VERSION ""

NS_ :

BS_:

BU_: VMCU VGGSECUSystem TECU OBDScanT2 HMIIOM EMS ECUspare2 ECUspare1 DACU CIOM BBM

BO_ 2566560036 VMCU_BB2_33S: 230 VMCU
 SG_ MaintInfoGrp_MaintOption30_ISig_ : 52|4@1+ (1,0) [0|0] ""  VGGSECUSystem,HMIIOM
 SG_ MaintInfoGrp_Unit36_ISig_4 : 363|3@1+ (1,0) [0|0] ""  VGGSECUSystem,HMIIOM
 SG_ MaintInfoGrp_MaintOption33_ISig_ : 40|4@1+ (1,0) [0|0] ""  HMIIOM,VGGSECUSystem
 SG_ MaintInfoGrp_ResetAuthorized32_I : 506|2@1+ (1,0) [0|0] ""  HMIIOM,VGGSECUSystem
 SG_ MaintInfoGrp_Status10_ISig_4 : 395|3@1+ (1,0) [0|0] ""  HMIIOM,VGGSECUSystem
 SG_ MaintInfoGrp_Unit2_ISig_4 : 459|3@1+ (1,0) [0|0] ""  VGGSECUSystem,HMIIOM
 SG_ MaintInfoGrp_Unit14_ISig_4 : 160|3@1+ (1,0) [0|0] ""  HMIIOM,VGGSECUSystem
 SG_ MaintInfoGrp_ResetAuthorized28_I : 486|2@1+ (1,0) [0|0] ""  HMIIOM,VGGSECUSystem
 SG_ MaintInfoGrp_ResetAuthorized10_I : 510|2@1+ (1,0) [0|0] ""  VGGSECUSystem,HMIIOM
 SG_ MaintInfoGrp_Status31_ISig_4 : 368|3@1+ (1,0) [0|0] ""  HMIIOM,VGGSECUSystem
 SG_ MaintInfoGrp_Unit32_ISig_4 : 427|3@1+ (1,0) [0|0] ""  HMIIOM,VGGSECUSystem
 SG_ MaintInfoGrp_Status15_ISig_4 : 251|3@1+ (1,0) [0|0] ""  HMIIOM,VGGSECUSystem
 SG_ MaintInfoGrp_Supported19_ISig_4 : 278|2@1+ (1,0) [0|0] ""  VGGSECUSystem,HMIIOM
 SG_ MaintInfoGrp_Unit34_ISig_4 : 312|3@1+ (1,0) [0|0] ""  VGGSECUSystem,HMIIOM
 SG_ MaintInfoGrp_Data17_ISig_4 : 816|32@1+ (1,0) [0|4294967295] ""  VGGSECUSystem,HMIIOM
 SG_ MaintInfoGrp_Unit26_ISig_4 : 179|3@1+ (1,0) [0|0] ""  VGGSECUSystem,HMIIOM
 SG_ MaintInfoGrp_Data24_ISig_4 : 848|32@1+ (1,0) [0|4294967295] ""  VGGSECUSystem,HMIIOM
 SG_ MaintInfoGrp_ResetAuthorized24_I : 502|2@1+ (1,0) [0|0] ""  VGGSECUSystem,HMIIOM
 SG_ MaintInfoGrp_ResetAuthorized34_I : 454|2@1+ (1,0) [0|0] ""  VGGSECUSystem,HMIIOM
 SG_ MaintInfoGrp_Unit28_ISig_4 : 176|3@1+ (1,0) [0|0] ""  VGGSECUSystem,HMIIOM
 SG_ MaintInfoGrp_Status26_ISig_4 : 219|3@1+ (1,0) [0|0] ""  HMIIOM,VGGSECUSystem
 SG_ MaintInfoGrp_Unit10_ISig_4 : 352|3@1+ (1,0) [0|0] ""  VGGSECUSystem,HMIIOM
 SG_ MaintInfoGrp_Data12_ISig_4 : 1616|32@1+ (1,0) [0|4294967295] ""  HMIIOM,VGGSECUSystem
 SG_ MaintInfoGrp_ResetAuthorized38_I : 230|2@1+ (1,0) [0|0] ""  HMIIOM,VGGSECUSystem
 SG_ MaintInfoGrp_MaintOption14_ISig_ : 128|4@1+ (1,0) [0|0] ""  HMIIOM,VGGSECUSystem
 SG_ MaintInfoGrp_MaintOption17_ISig_ : 0|4@1+ (1,0) [0|0] ""  VGGSECUSystem,HMIIOM
 SG_ MaintInfoGrp_Status33_ISig_4 : 360|3@1+ (1,0) [0|0] ""  HMIIOM,VGGSECUSystem
 SG_ MaintInfoGrp_Unit6_ISig_4 : 203|3@1+ (1,0) [0|0] ""  VGGSECUSystem,HMIIOM
 SG_ MaintInfoGrp_Supported7_ISig_4 : 504|2@1+ (1,0) [0|0] ""  HMIIOM,VGGSECUSystem
 SG_ MaintInfoGrp_Status7_ISig_4 : 240|3@1+ (1,0) [0|0] ""  VGGSECUSystem,HMIIOM
 SG_ MaintInfoGrp_ResetAuthorized2_IS : 462|2@1+ (1,0) [0|0] ""  HMIIOM,VGGSECUSystem
 SG_ MaintInfoGrp_MaintOption27_ISig_ : 44|4@1+ (1,0) [0|0] ""  HMIIOM,VGGSECUSystem
 SG_ MaintInfoGrp_Supported36_ISig_4 : 492|2@1+ (1,0) [0|0] ""  HMIIOM,VGGSECUSystem
 SG_ MaintInfoGrp_Unit22_ISig_4 : 171|3@1+ (1,0) [0|0] ""  VGGSECUSystem,HMIIOM
 SG_ MaintInfoGrp_Unit18_ISig_4 : 315|3@1+ (1,0) [0|0] ""  VGGSECUSystem,HMIIOM
 SG_ MaintInfoGrp_MaintOption28_ISig_ : 96|4@1+ (1,0) [0|0] ""  VGGSECUSystem,HMIIOM
 SG_ MaintInfoGrp_Supported18_ISig_4 : 526|2@1+ (1,0) [0|0] ""  HMIIOM,VGGSECUSystem
 SG_ MaintInfoGrp_Status22_ISig_4 : 304|3@1+ (1,0) [0|0] ""  HMIIOM,VGGSECUSystem
 SG_ MaintInfoGrp_Status30_ISig_4 : 200|3@1+ (1,0) [0|0] ""  VGGSECUSystem,HMIIOM
 SG_ MaintInfoGrp_Status20_ISig_4 : 467|3@1+ (1,0) [0|0] ""  VGGSECUSystem,HMIIOM
 SG_ MaintInfoGrp_Status38_ISig_4 : 419|3@1+ (1,0) [0|0] ""  VGGSECUSystem,HMIIOM
 SG_ MaintInfoGrp_Data38_ISig_4 : 688|32@1+ (1,0) [0|4294967295] ""  HMIIOM,VGGSECUSystem
 SG_ MaintInfoGrp_ResetAuthorized7_IS : 190|2@1+ (1,0) [0|0] ""  HMIIOM,VGGSECUSystem
 SG_ MaintInfoGrp_Data19_ISig_4 : 1104|32@1+ (1,0) [0|4294967295] ""  HMIIOM,VGGSECUSystem
 SG_ MaintInfoGrp_ResetAuthorized19_I : 438|2@1+ (1,0) [0|0] ""  HMIIOM,VGGSECUSystem
 SG_ MaintInfoGrp_ResetAuthorized12_I : 542|2@1+ (1,0) [0|0] ""  HMIIOM,VGGSECUSystem
 SG_ MaintInfoGrp_MaintOption8_ISig_4 : 108|4@1+ (1,0) [0|0] ""  HMIIOM,VGGSECUSystem
 SG_ MaintInfoGrp_MaintOption9_ISig_4 : 56|4@1+ (1,0) [0|0] ""  HMIIOM,VGGSECUSystem
 SG_ MaintInfoGrp_ResetAuthorized13_I : 522|2@1+ (1,0) [0|0] ""  VGGSECUSystem,HMIIOM
 SG_ MaintInfoGrp_Unit31_ISig_4 : 283|3@1+ (1,0) [0|0] ""  VGGSECUSystem,HMIIOM
 SG_ MaintInfoGrp_Status2_ISig_4 : 400|3@1+ (1,0) [0|0] ""  VGGSECUSystem,HMIIOM
 SG_ MaintInfoGrp_ResetAuthorized5_IS : 206|2@1+ (1,0) [0|0] ""  VGGSECUSystem,HMIIOM
 SG_ MaintInfoGrp_Supported33_ISig_4 : 350|2@1+ (1,0) [0|0] ""  VGGSECUSystem,HMIIOM
 SG_ MaintInfoGrp_Unit7_ISig_4 : 256|3@1+ (1,0) [0|0] ""  HMIIOM,VGGSECUSystem
 SG_ MaintInfoGrp_Supported34_ISig_4 : 524|2@1+ (1,0) [0|0] ""  HMIIOM,VGGSECUSystem
 SG_ MaintInfoGrp_Data16_ISig_4 : 1392|32@1+ (1,0) [0|4294967295] ""  HMIIOM,VGGSECUSystem
 SG_ MaintInfoGrp_Unit19_ISig_4 : 299|3@1+ (1,0) [0|0] ""  HMIIOM,VGGSECUSystem
 SG_ MaintInfoGrp_ResetAuthorized21_I : 494|2@1+ (1,0) [0|0] ""  HMIIOM,VGGSECUSystem
 SG_ MaintInfoGrp_ResetAuthorized31_I : 552|2@1+ (1,0) [0|0] ""  HMIIOM,VGGSECUSystem
 SG_ MaintInfoGrp_Data28_ISig_4 : 1488|32@1+ (1,0) [0|4294967295] ""  HMIIOM,VGGSECUSystem
 SG_ MaintInfoGrp_ResetAuthorized3_IS : 374|2@1+ (1,0) [0|0] ""  HMIIOM,VGGSECUSystem
 SG_ MaintInfoGrp_MaintOption34_ISig_ : 12|4@1+ (1,0) [0|0] ""  VGGSECUSystem,HMIIOM
 SG_ MaintInfoGrp_Status21_ISig_4 : 475|3@1+ (1,0) [0|0] ""  VGGSECUSystem,HMIIOM
 SG_ MaintInfoGrp_Unit21_ISig_4 : 235|3@1+ (1,0) [0|0] ""  VGGSECUSystem,HMIIOM
 SG_ MaintInfoGrp_MaintOption24_ISig_ : 116|4@1+ (1,0) [0|0] ""  HMIIOM,VGGSECUSystem
 SG_ MaintInfoGrp_Data26_ISig_4 : 976|32@1+ (1,0) [0|4294967295] ""  VGGSECUSystem,HMIIOM
 SG_ MaintInfoGrp_Data37_ISig_4 : 752|32@1+ (1,0) [0|4294967295] ""  VGGSECUSystem,HMIIOM
 SG_ MaintInfoGrp_Data35_ISig_4 : 1136|32@1+ (1,0) [0|4294967295] ""  VGGSECUSystem,HMIIOM
 SG_ MaintInfoGrp_Supported17_ISig_4 : 222|2@1+ (1,0) [0|0] ""  VGGSECUSystem,HMIIOM
 SG_ MaintInfoGrp_ResetAuthorized17_I : 546|2@1+ (1,0) [0|0] ""  VGGSECUSystem,HMIIOM
 SG_ MaintInfoGrp_Unit25_ISig_4 : 248|3@1+ (1,0) [0|0] ""  HMIIOM,VGGSECUSystem
 SG_ MaintInfoGrp_Unit37_ISig_4 : 344|3@1+ (1,0) [0|0] ""  VGGSECUSystem,HMIIOM
 SG_ MaintInfoGrp_MaintOption2_ISig_4 : 60|4@1+ (1,0) [0|0] ""  HMIIOM,VGGSECUSystem
 SG_ MaintInfoGrp_Supported21_ISig_4 : 406|2@1+ (1,0) [0|0] ""  VGGSECUSystem,HMIIOM
 SG_ MaintInfoGrp_ResetAuthorized16_I : 270|2@1+ (1,0) [0|0] ""  HMIIOM,VGGSECUSystem
 SG_ MaintInfoGrp_Supported15_ISig_4 : 528|2@1+ (1,0) [0|0] ""  HMIIOM,VGGSECUSystem
 SG_ MaintInfoGrp_ResetAuthorized9_IS : 540|2@1+ (1,0) [0|0] ""  HMIIOM,VGGSECUSystem
 SG_ MaintInfoGrp_MaintOption18_ISig_ : 36|4@1+ (1,0) [0|0] ""  VGGSECUSystem,HMIIOM
 SG_ MaintInfoGrp_Data14_ISig_4 : 1456|32@1+ (1,0) [0|4294967295] ""  HMIIOM,VGGSECUSystem
 SG_ MaintInfoGrp_Data8_ISig_4 : 1808|32@1+ (1,0) [0|4294967295] ""  HMIIOM,VGGSECUSystem
 SG_ MaintInfoGrp_Supported29_ISig_4 : 484|2@1+ (1,0) [0|0] ""  HMIIOM,VGGSECUSystem
 SG_ MaintInfoGrp_ResetAuthorized39_I : 558|2@1+ (1,0) [0|0] ""  HMIIOM,VGGSECUSystem
 SG_ MaintInfoGrp_Supported32_ISig_4 : 358|2@1+ (1,0) [0|0] ""  HMIIOM,VGGSECUSystem
 SG_ MaintInfoGrp_Data33_ISig_4 : 1328|32@1+ (1,0) [0|4294967295] ""  VGGSECUSystem,HMIIOM
 SG_ MaintInfoGrp_ResetAuthorized35_I : 550|2@1+ (1,0) [0|0] ""  VGGSECUSystem,HMIIOM
 SG_ MaintInfoGrp_Data30_ISig_4 : 880|32@1+ (1,0) [0|4294967295] ""  VGGSECUSystem,HMIIOM
 SG_ MaintInfoGrp_ResetAuthorized29_I : 534|2@1+ (1,0) [0|0] ""  VGGSECUSystem,HMIIOM
 SG_ MaintInfoGrp_Supported35_ISig_4 : 310|2@1+ (1,0) [0|0] ""  VGGSECUSystem,HMIIOM
 SG_ MaintInfoGrp_ResetAuthorized4_IS : 530|2@1+ (1,0) [0|0] ""  VGGSECUSystem,HMIIOM
 SG_ MaintInfoGrp_Data10_ISig_4 : 624|32@1+ (1,0) [0|4294967295] ""  HMIIOM,VGGSECUSystem
 SG_ MaintInfoGrp_Data9_ISig_4 : 1584|32@1+ (1,0) [0|4294967295] ""  VGGSECUSystem,HMIIOM
 SG_ MaintInfoGrp_Unit1_ISig_4 : 328|3@1+ (1,0) [0|0] ""  VGGSECUSystem,HMIIOM
 SG_ MaintInfoGrp_MaintOption7_ISig_4 : 104|4@1+ (1,0) [0|0] ""  HMIIOM,VGGSECUSystem
 SG_ MaintInfoGrp_Supported24_ISig_4 : 390|2@1+ (1,0) [0|0] ""  VGGSECUSystem,HMIIOM
 SG_ MaintInfoGrp_Supported25_ISig_4 : 514|2@1+ (1,0) [0|0] ""  VGGSECUSystem,HMIIOM
 SG_ MaintInfoGrp_Unit15_ISig_4 : 339|3@1+ (1,0) [0|0] ""  VGGSECUSystem,HMIIOM
 SG_ MaintInfoGrp_Supported1_ISig_4 : 446|2@1+ (1,0) [0|0] ""  HMIIOM,VGGSECUSystem
 SG_ MaintInfoGrp_ResetAuthorized11_I : 254|2@1+ (1,0) [0|0] ""  HMIIOM,VGGSECUSystem
 SG_ MaintInfoGrp_Supported13_ISig_4 : 238|2@1+ (1,0) [0|0] ""  HMIIOM,VGGSECUSystem
 SG_ MaintInfoGrp_Supported10_ISig_4 : 490|2@1+ (1,0) [0|0] ""  HMIIOM,VGGSECUSystem
 SG_ MaintInfoGrp_Data2_ISig_4 : 720|32@1+ (1,0) [0|4294967295] ""  HMIIOM,VGGSECUSystem
 SG_ MaintInfoGrp_Unit16_ISig_4 : 243|3@1+ (1,0) [0|0] ""  HMIIOM,VGGSECUSystem
 SG_ MaintInfoGrp_MaintOption35_ISig_ : 144|4@1+ (1,0) [0|0] ""  VGGSECUSystem,HMIIOM
 SG_ MaintInfoGrp_MaintOption22_ISig_ : 156|4@1+ (1,0) [0|0] ""  HMIIOM,VGGSECUSystem
 SG_ MaintInfoGrp_MaintOption12_ISig_ : 8|4@1+ (1,0) [0|0] ""  VGGSECUSystem,HMIIOM
 SG_ MaintInfoGrp_Supported9_ISig_4 : 342|2@1+ (1,0) [0|0] ""  HMIIOM,VGGSECUSystem
 SG_ MaintInfoGrp_Supported31_ISig_4 : 512|2@1+ (1,0) [0|0] ""  VGGSECUSystem,HMIIOM
 SG_ MaintInfoGrp_MaintOption37_ISig_ : 100|4@1+ (1,0) [0|0] ""  HMIIOM,VGGSECUSystem
 SG_ MaintInfoGrp_MaintOption13_ISig_ : 120|4@1+ (1,0) [0|0] ""  HMIIOM,VGGSECUSystem
 SG_ MaintInfoGrp_ResetAuthorized22_I : 538|2@1+ (1,0) [0|0] ""  VGGSECUSystem,HMIIOM
 SG_ MaintInfoGrp_Status14_ISig_4 : 259|3@1+ (1,0) [0|0] ""  VGGSECUSystem,HMIIOM
 SG_ MaintInfoGrp_Status18_ISig_4 : 424|3@1+ (1,0) [0|0] ""  HMIIOM,VGGSECUSystem
 SG_ MaintInfoGrp_Unit17_ISig_4 : 187|3@1+ (1,0) [0|0] ""  VGGSECUSystem,HMIIOM
 SG_ MaintInfoGrp_Unit12_ISig_4 : 224|3@1+ (1,0) [0|0] ""  HMIIOM,VGGSECUSystem
 SG_ MaintInfoGrp_Data22_ISig_4 : 1552|32@1+ (1,0) [0|4294967295] ""  HMIIOM,VGGSECUSystem
 SG_ MaintInfoGrp_Supported27_ISig_4 : 262|2@1+ (1,0) [0|0] ""  HMIIOM,VGGSECUSystem
 SG_ MaintInfoGrp_Unit4_ISig_4 : 163|3@1+ (1,0) [0|0] ""  HMIIOM,VGGSECUSystem
 SG_ MaintInfoGrp_Data13_ISig_4 : 656|32@1+ (1,0) [0|4294967295] ""  VGGSECUSystem,HMIIOM
 SG_ MaintInfoGrp_Status27_ISig_4 : 355|3@1+ (1,0) [0|0] ""  VGGSECUSystem,HMIIOM
 SG_ MaintInfoGrp_MaintOption29_ISig_ : 124|4@1+ (1,0) [0|0] ""  HMIIOM,VGGSECUSystem
 SG_ MaintInfoGrp_Unit9_ISig_4 : 435|3@1+ (1,0) [0|0] ""  VGGSECUSystem,HMIIOM
 SG_ MaintInfoGrp_Unit13_ISig_4 : 387|3@1+ (1,0) [0|0] ""  VGGSECUSystem,HMIIOM
 SG_ MaintInfoGrp_Data25_ISig_4 : 560|32@1+ (1,0) [0|4294967295] ""  HMIIOM,VGGSECUSystem
 SG_ MaintInfoGrp_Unit3_ISig_4 : 472|3@1+ (1,0) [0|0] ""  VGGSECUSystem,HMIIOM
 SG_ MaintInfoGrp_MaintOption15_ISig_ : 148|4@1+ (1,0) [0|0] ""  VGGSECUSystem,HMIIOM
 SG_ MaintInfoGrp_ResetAuthorized15_I : 508|2@1+ (1,0) [0|0] ""  VGGSECUSystem,HMIIOM
 SG_ MaintInfoGrp_MaintOption11_ISig_ : 68|4@1+ (1,0) [0|0] ""  HMIIOM,VGGSECUSystem
 SG_ MaintInfoGrp_MaintOption25_ISig_ : 112|4@1+ (1,0) [0|0] ""  VGGSECUSystem,HMIIOM
 SG_ MaintInfoGrp_Supported16_ISig_4 : 174|2@1+ (1,0) [0|0] ""  HMIIOM,VGGSECUSystem
 SG_ MaintInfoGrp_Supported23_ISig_4 : 544|2@1+ (1,0) [0|0] ""  VGGSECUSystem,HMIIOM
 SG_ MaintInfoGrp_Status13_ISig_4 : 267|3@1+ (1,0) [0|0] ""  VGGSECUSystem,HMIIOM
 SG_ MaintInfoGrp_Status17_ISig_4 : 307|3@1+ (1,0) [0|0] ""  HMIIOM,VGGSECUSystem
 SG_ MaintInfoGrp_Unit8_ISig_4 : 275|3@1+ (1,0) [0|0] ""  VGGSECUSystem,HMIIOM
 SG_ MaintInfoGrp_MaintOption38_ISig_ : 64|4@1+ (1,0) [0|0] ""  VGGSECUSystem,HMIIOM
 SG_ MaintInfoGrp_Data4_ISig_4 : 1040|32@1+ (1,0) [0|4294967295] ""  VGGSECUSystem,HMIIOM
 SG_ MaintInfoGrp_Supported2_ISig_4 : 198|2@1+ (1,0) [0|0] ""  VGGSECUSystem,HMIIOM
 SG_ MaintInfoGrp_ResetAuthorized0_IS : 516|2@1+ (1,0) [0|0] ""  VGGSECUSystem,HMIIOM
 SG_ MaintInfoGrp_Supported5_ISig_4 : 478|2@1+ (1,0) [0|0] ""  HMIIOM,VGGSECUSystem
 SG_ MaintInfoGrp_Status6_ISig_4 : 336|3@1+ (1,0) [0|0] ""  HMIIOM,VGGSECUSystem
 SG_ MaintInfoGrp_Unit5_ISig_4 : 411|3@1+ (1,0) [0|0] ""  VGGSECUSystem,HMIIOM
 SG_ MaintInfoGrp_Data0_ISig_4 : 592|32@1+ (1,0) [0|4294967295] ""  HMIIOM,VGGSECUSystem
 SG_ MaintInfoGrp_Data29_ISig_4 : 1776|32@1+ (1,0) [0|4294967295] ""  HMIIOM,VGGSECUSystem
 SG_ MaintInfoGrp_Supported28_ISig_4 : 498|2@1+ (1,0) [0|0] ""  VGGSECUSystem,HMIIOM
 SG_ MaintInfoGrp_Status32_ISig_4 : 371|3@1+ (1,0) [0|0] ""  VGGSECUSystem,HMIIOM
 SG_ MaintInfoGrp_MaintOption0_ISig_4 : 152|4@1+ (1,0) [0|0] ""  VGGSECUSystem,HMIIOM
 SG_ MaintInfoGrp_ResetAuthorized25_I : 480|2@1+ (1,0) [0|0] ""  HMIIOM,VGGSECUSystem
 SG_ MaintInfoGrp_MaintOption32_ISig_ : 28|4@1+ (1,0) [0|0] ""  HMIIOM,VGGSECUSystem
 SG_ MaintInfoGrp_Unit11_ISig_4 : 464|3@1+ (1,0) [0|0] ""  VGGSECUSystem,HMIIOM
 SG_ MaintInfoGrp_Data39_ISig_4 : 912|32@1+ (1,0) [0|4294967295] ""  VGGSECUSystem,HMIIOM
 SG_ MaintInfoGrp_MaintOption4_ISig_4 : 80|4@1+ (1,0) [0|0] ""  VGGSECUSystem,HMIIOM
 SG_ MaintInfoGrp_Supported38_ISig_4 : 302|2@1+ (1,0) [0|0] ""  VGGSECUSystem,HMIIOM
 SG_ MaintInfoGrp_MaintOption1_ISig_4 : 136|4@1+ (1,0) [0|0] ""  VGGSECUSystem,HMIIOM
 SG_ MaintInfoGrp_Supported30_ISig_4 : 182|2@1+ (1,0) [0|0] ""  HMIIOM,VGGSECUSystem
 SG_ MaintInfoGrp_ResetAuthorized33_I : 496|2@1+ (1,0) [0|0] ""  HMIIOM,VGGSECUSystem
 SG_ MaintInfoGrp_Status0_ISig_4 : 392|3@1+ (1,0) [0|0] ""  HMIIOM,VGGSECUSystem
 SG_ MaintInfoGrp_ResetAuthorized20_I : 334|2@1+ (1,0) [0|0] ""  VGGSECUSystem,HMIIOM
 SG_ MaintInfoGrp_Unit33_ISig_4 : 232|3@1+ (1,0) [0|0] ""  VGGSECUSystem,HMIIOM
 SG_ MaintInfoGrp_Supported26_ISig_4 : 500|2@1+ (1,0) [0|0] ""  VGGSECUSystem,HMIIOM
 SG_ MaintInfoGrp_ResetAuthorized6_IS : 532|2@1+ (1,0) [0|0] ""  VGGSECUSystem,HMIIOM
 SG_ MaintInfoGrp_Data18_ISig_4 : 1648|32@1+ (1,0) [0|4294967295] ""  HMIIOM,VGGSECUSystem
 SG_ MaintInfoGrp_Status16_ISig_4 : 432|3@1+ (1,0) [0|0] ""  HMIIOM,VGGSECUSystem
 SG_ MaintInfoGrp_ResetAuthorized18_I : 294|2@1+ (1,0) [0|0] ""  HMIIOM,VGGSECUSystem
 SG_ MaintInfoGrp_Status4_ISig_4 : 168|3@1+ (1,0) [0|0] ""  HMIIOM,VGGSECUSystem
 SG_ MaintInfoGrp_Data3_ISig_4 : 1072|32@1+ (1,0) [0|4294967295] ""  VGGSECUSystem,HMIIOM
 SG_ MaintInfoGrp_MaintOption20_ISig_ : 140|4@1+ (1,0) [0|0] ""  VGGSECUSystem,HMIIOM
 SG_ MaintInfoGrp_ResetAuthorized30_I : 166|2@1+ (1,0) [0|0] ""  HMIIOM,VGGSECUSystem
 SG_ MaintInfoGrp_ResetAuthorized23_I : 520|2@1+ (1,0) [0|0] ""  HMIIOM,VGGSECUSystem
 SG_ MaintInfoGrp_Unit30_ISig_4 : 408|3@1+ (1,0) [0|0] ""  HMIIOM,VGGSECUSystem
 SG_ MaintInfoGrp_Data20_ISig_4 : 944|32@1+ (1,0) [0|4294967295] ""  HMIIOM,VGGSECUSystem
 SG_ MaintInfoGrp_MaintOption23_ISig_ : 132|4@1+ (1,0) [0|0] ""  VGGSECUSystem,HMIIOM
 SG_ MaintInfoGrp_Data23_ISig_4 : 1680|32@1+ (1,0) [0|4294967295] ""  VGGSECUSystem,HMIIOM
 SG_ MaintInfoGrp_Unit20_ISig_4 : 376|3@1+ (1,0) [0|0] ""  VGGSECUSystem,HMIIOM
 SG_ MaintInfoGrp_MaintOption10_ISig_ : 76|4@1+ (1,0) [0|0] ""  VGGSECUSystem,HMIIOM
 SG_ MaintInfoGrp_Status39_ISig_4 : 443|3@1+ (1,0) [0|0] ""  VGGSECUSystem,HMIIOM
 SG_ MaintInfoGrp_Data21_ISig_4 : 1424|32@1+ (1,0) [0|4294967295] ""  VGGSECUSystem,HMIIOM
 SG_ MaintInfoGrp_Status3_ISig_4 : 451|3@1+ (1,0) [0|0] ""  VGGSECUSystem,HMIIOM
 SG_ MaintInfoGrp_Data5_ISig_4 : 784|32@1+ (1,0) [0|4294967295] ""  HMIIOM,VGGSECUSystem
 SG_ MaintInfoGrp_ResetAuthorized26_I : 556|2@1+ (1,0) [0|0] ""  VGGSECUSystem,HMIIOM
 SG_ MaintInfoGrp_Supported12_ISig_4 : 366|2@1+ (1,0) [0|0] ""  VGGSECUSystem,HMIIOM
 SG_ MaintInfoGrp_Data32_ISig_4 : 1296|32@1+ (1,0) [0|4294967295] ""  VGGSECUSystem,HMIIOM
 SG_ MaintInfoGrp_Status29_ISig_4 : 323|3@1+ (1,0) [0|0] ""  HMIIOM,VGGSECUSystem
 SG_ MaintInfoGrp_ResetAuthorized37_I : 246|2@1+ (1,0) [0|0] ""  HMIIOM,VGGSECUSystem
 SG_ MaintInfoGrp_Status36_ISig_4 : 379|3@1+ (1,0) [0|0] ""  HMIIOM,VGGSECUSystem
 SG_ MaintInfoGrp_Supported22_ISig_4 : 326|2@1+ (1,0) [0|0] ""  HMIIOM,VGGSECUSystem
 SG_ MaintInfoGrp_Status35_ISig_4 : 331|3@1+ (1,0) [0|0] ""  HMIIOM,VGGSECUSystem
 SG_ MaintInfoGrp_Data7_ISig_4 : 1360|32@1+ (1,0) [0|4294967295] ""  HMIIOM,VGGSECUSystem
 SG_ MaintInfoGrp_MaintOption26_ISig_ : 48|4@1+ (1,0) [0|0] ""  VGGSECUSystem,HMIIOM
 SG_ MaintInfoGrp_Status23_ISig_4 : 403|3@1+ (1,0) [0|0] ""  VGGSECUSystem,HMIIOM
 SG_ MaintInfoGrp_Unit35_ISig_4 : 192|3@1+ (1,0) [0|0] ""  VGGSECUSystem,HMIIOM
 SG_ MaintInfoGrp_Supported6_ISig_4 : 398|2@1+ (1,0) [0|0] ""  VGGSECUSystem,HMIIOM
 SG_ MaintInfoGrp_Data34_ISig_4 : 1008|32@1+ (1,0) [0|4294967295] ""  HMIIOM,VGGSECUSystem
 SG_ MaintInfoGrp_Unit27_ISig_4 : 416|3@1+ (1,0) [0|0] ""  VGGSECUSystem,HMIIOM
 SG_ MaintInfoGrp_MaintOption19_ISig_ : 72|4@1+ (1,0) [0|0] ""  HMIIOM,VGGSECUSystem
 SG_ MaintInfoGrp_ResetAuthorized14_I : 214|2@1+ (1,0) [0|0] ""  VGGSECUSystem,HMIIOM
 SG_ MaintInfoGrp_Status34_ISig_4 : 272|3@1+ (1,0) [0|0] ""  HMIIOM,VGGSECUSystem
 SG_ MaintInfoGrp_Supported37_ISig_4 : 286|2@1+ (1,0) [0|0] ""  VGGSECUSystem,HMIIOM
 SG_ MaintInfoGrp_MaintOption3_ISig_4 : 20|4@1+ (1,0) [0|0] ""  VGGSECUSystem,HMIIOM
 SG_ MaintInfoGrp_Status1_ISig_4 : 384|3@1+ (1,0) [0|0] ""  HMIIOM,VGGSECUSystem
 SG_ MaintInfoGrp_Data1_ISig_4 : 1200|32@1+ (1,0) [0|4294967295] ""  HMIIOM,VGGSECUSystem
 SG_ MaintInfoGrp_Status25_ISig_4 : 296|3@1+ (1,0) [0|0] ""  HMIIOM,VGGSECUSystem
 SG_ MaintInfoGrp_ResetAuthorized1_IS : 318|2@1+ (1,0) [0|0] ""  VGGSECUSystem,HMIIOM
 SG_ MaintInfoGrp_ResetAuthorized27_I : 518|2@1+ (1,0) [0|0] ""  VGGSECUSystem,HMIIOM
 SG_ MaintInfoGrp_ResetAuthorized36_I : 470|2@1+ (1,0) [0|0] ""  HMIIOM,VGGSECUSystem
 SG_ MaintInfoGrp_Status28_ISig_4 : 347|3@1+ (1,0) [0|0] ""  HMIIOM,VGGSECUSystem
 SG_ MaintInfoGrp_Status24_ISig_4 : 280|3@1+ (1,0) [0|0] ""  VGGSECUSystem,HMIIOM
 SG_ MaintInfoGrp_MaintOption31_ISig_ : 32|4@1+ (1,0) [0|0] ""  HMIIOM,VGGSECUSystem
 SG_ MaintInfoGrp_Supported20_ISig_4 : 482|2@1+ (1,0) [0|0] ""  HMIIOM,VGGSECUSystem
 SG_ MaintInfoGrp_Unit38_ISig_4 : 195|3@1+ (1,0) [0|0] ""  VGGSECUSystem,HMIIOM
 SG_ MaintInfoGrp_Unit24_ISig_4 : 448|3@1+ (1,0) [0|0] ""  VGGSECUSystem,HMIIOM
 SG_ MaintInfoGrp_Data15_ISig_4 : 1264|32@1+ (1,0) [0|4294967295] ""  HMIIOM,VGGSECUSystem
 SG_ MaintInfoGrp_Status37_ISig_4 : 440|3@1+ (1,0) [0|0] ""  VGGSECUSystem,HMIIOM
 SG_ MaintInfoGrp_Supported39_ISig_4 : 414|2@1+ (1,0) [0|0] ""  HMIIOM,VGGSECUSystem
 SG_ MaintInfoGrp_MaintOption39_ISig_ : 4|4@1+ (1,0) [0|0] ""  HMIIOM,VGGSECUSystem
 SG_ MaintInfoGrp_Supported4_ISig_4 : 430|2@1+ (1,0) [0|0] ""  HMIIOM,VGGSECUSystem
 SG_ MaintInfoGrp_Supported3_ISig_4 : 536|2@1+ (1,0) [0|0] ""  HMIIOM,VGGSECUSystem
 SG_ MaintInfoGrp_Data6_ISig_4 : 1520|32@1+ (1,0) [0|4294967295] ""  HMIIOM,VGGSECUSystem
 SG_ MaintInfoGrp_Unit39_ISig_4 : 320|3@1+ (1,0) [0|0] ""  VGGSECUSystem,HMIIOM
 SG_ MaintInfoGrp_Status5_ISig_4 : 291|3@1+ (1,0) [0|0] ""  HMIIOM,VGGSECUSystem
 SG_ MaintInfoGrp_Data36_ISig_4 : 1232|32@1+ (1,0) [0|4294967295] ""  VGGSECUSystem,HMIIOM
 SG_ MaintInfoGrp_MaintOption6_ISig_4 : 84|4@1+ (1,0) [0|0] ""  VGGSECUSystem,HMIIOM
 SG_ MaintInfoGrp_Status11_ISig_4 : 211|3@1+ (1,0) [0|0] ""  HMIIOM,VGGSECUSystem
 SG_ MaintInfoGrp_Status19_ISig_4 : 216|3@1+ (1,0) [0|0] ""  VGGSECUSystem,HMIIOM
 SG_ MaintInfoGrp_Status9_ISig_4 : 288|3@1+ (1,0) [0|0] ""  HMIIOM,VGGSECUSystem
 SG_ MaintInfoGrp_Supported11_ISig_4 : 548|2@1+ (1,0) [0|0] ""  HMIIOM,VGGSECUSystem
 SG_ MaintInfoGrp_Data27_ISig_4 : 1168|32@1+ (1,0) [0|4294967295] ""  VGGSECUSystem,HMIIOM
 SG_ MaintInfoGrp_Data31_ISig_4 : 1744|32@1+ (1,0) [0|4294967295] ""  HMIIOM,VGGSECUSystem
 SG_ MaintInfoGrp_MaintOption36_ISig_ : 16|4@1+ (1,0) [0|0] ""  VGGSECUSystem,HMIIOM
 SG_ MaintInfoGrp_ResetAuthorized8_IS : 422|2@1+ (1,0) [0|0] ""  VGGSECUSystem,HMIIOM
 SG_ MaintInfoGrp_MaintOption21_ISig_ : 92|4@1+ (1,0) [0|0] ""  HMIIOM,VGGSECUSystem
 SG_ MaintInfoGrp_Unit23_ISig_4 : 227|3@1+ (1,0) [0|0] ""  VGGSECUSystem,HMIIOM
 SG_ MaintInfoGrp_MaintOption5_ISig_4 : 88|4@1+ (1,0) [0|0] ""  HMIIOM,VGGSECUSystem
 SG_ MaintInfoGrp_MaintOption16_ISig_ : 24|4@1+ (1,0) [0|0] ""  VGGSECUSystem,HMIIOM
 SG_ MaintInfoGrp_Unit29_ISig_4 : 208|3@1+ (1,0) [0|0] ""  VGGSECUSystem,HMIIOM
 SG_ MaintInfoGrp_Status12_ISig_4 : 184|3@1+ (1,0) [0|0] ""  VGGSECUSystem,HMIIOM
 SG_ MaintInfoGrp_Supported0_ISig_4 : 554|2@1+ (1,0) [0|0] ""  HMIIOM,VGGSECUSystem
 SG_ MaintInfoGrp_Status8_ISig_4 : 456|3@1+ (1,0) [0|0] ""  VGGSECUSystem,HMIIOM
 SG_ MaintInfoGrp_Data11_ISig_4 : 1712|32@1+ (1,0) [0|4294967295] ""  VGGSECUSystem,HMIIOM
 SG_ MaintInfoGrp_Unit0_ISig_4 : 264|3@1+ (1,0) [0|0] ""  VGGSECUSystem,HMIIOM
 SG_ MaintInfoGrp_Supported14_ISig_4 : 488|2@1+ (1,0) [0|0] ""  HMIIOM,VGGSECUSystem
 SG_ MaintInfoGrp_Supported8_ISig_4 : 382|2@1+ (1,0) [0|0] ""  HMIIOM,VGGSECUSystem

BO_ 2566044965 VMCU_BB2_32S_FCM: 8 CIOM
 SG_ VMCU_BB2_32S_FCS : 0|64@1+ (1,0) [0|0] ""  VMCU

BO_ 2566044964 VMCU_BB2_32S: 11 VMCU
 SG_ ECU2VIN_stat_ISig_4 : 0|88@1+ (1,0) [0|0] ""  CIOM

BO_ 2566089509 VMCU_BB2_31S_FCM: 8 CIOM
 SG_ VMCU_BB2_31S_FCS : 0|64@1+ (1,0) [0|0] ""  VMCU

BO_ 2566089508 VMCU_BB2_31S: 11 VMCU
 SG_ ECU1VIN_stat : 0|88@1+ (1,0) [0|0] ""  CIOM

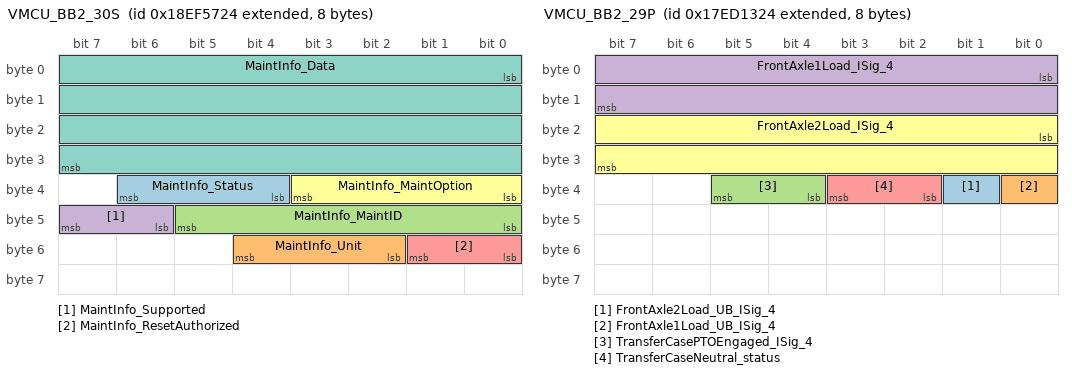
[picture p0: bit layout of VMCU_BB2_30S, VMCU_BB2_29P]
BO_ 2565822244 VMCU_BB2_30S: 8 VMCU
 SG_ MaintInfo_Status : 36|3@1+ (1,0) [0|0] ""  HMIIOM
 SG_ MaintInfo_Unit : 50|3@1+ (1,0) [0|0] ""  HMIIOM
 SG_ MaintInfo_MaintID : 40|6@1+ (1,0) [0|0] ""  HMIIOM
 SG_ MaintInfo_Supported : 46|2@1+ (1,0) [0|0] ""  HMIIOM
 SG_ MaintInfo_ResetAuthorized : 48|2@1+ (1,0) [0|0] ""  HMIIOM
 SG_ MaintInfo_MaintOption : 32|4@1+ (1,0) [0|0] ""  HMIIOM
 SG_ MaintInfo_Data : 0|32@1+ (1,0) [0|4294967295] ""  HMIIOM

BO_ 2548896548 VMCU_BB2_29P: 8 VMCU
 SG_ FrontAxle2Load_UB_ISig_4 : 33|1@1+ (1,0) [0|0] ""  TECU,BBM,DACU,HMIIOM
 SG_ FrontAxle1Load_UB_ISig_4 : 32|1@1+ (1,0) [0|0] ""  TECU,DACU,HMIIOM,BBM
 SG_ TransferCasePTOEngaged_ISig_4 : 36|2@1+ (1,0) [0|0] ""  CIOM
 SG_ FrontAxle1Load_ISig_4 : 0|16@1+ (0.5,0) [0|32767.5] "kg"  HMIIOM,DACU,TECU,BBM
 SG_ TransferCaseNeutral_status : 34|2@1+ (1,0) [0|0] ""  CIOM,HMIIOM,BBM
 SG_ FrontAxle2Load_ISig_4 : 16|16@1+ (0.5,0) [0|32767.5] "kg"  HMIIOM,DACU,BBM,TECU

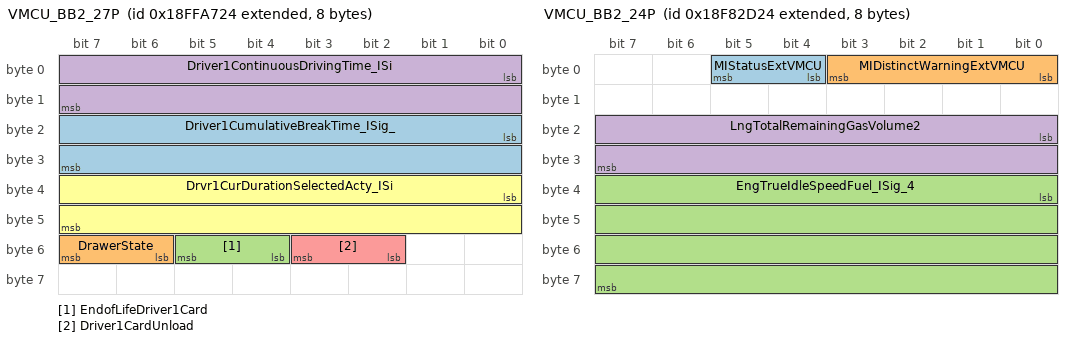
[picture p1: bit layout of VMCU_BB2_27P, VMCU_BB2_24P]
BO_ 2566891300 VMCU_BB2_27P: 8 VMCU
 SG_ Driver1CumulativeBreakTime_ISig_ : 16|16@1+ (1,0) [0|65535] "min"  HMIIOM
 SG_ DrawerState : 54|2@1+ (1,0) [0|0] ""  HMIIOM
 SG_ EndofLifeDriver1Card : 52|2@1+ (1,0) [0|0] ""  HMIIOM
 SG_ Driver1ContinuousDrivingTime_ISi : 0|16@1+ (1,0) [0|65535] "min"  HMIIOM
 SG_ Driver1CardUnload : 50|2@1+ (1,0) [0|0] ""  HMIIOM
 SG_ Drvr1CurDurationSelectedActy_ISi : 32|16@1+ (1,0) [0|65535] "min"  HMIIOM

BO_ 2566490404 VMCU_BB2_26P: 8 VMCU
 SG_ FuelConsumptionPTO_ISig_4 : 32|32@1+ (0.01,0) [0|42949672.95] "l"  HMIIOM
 SG_ AtLeastOnePTOActivationTime_ISig : 0|32@1+ (1,0) [0|4294967295] "s"  HMIIOM,BBM

BO_ 2566445860 VMCU_BB2_25P: 8 VMCU
 SG_ EngineGreenAreaOutFuel_ISig_4 : 0|32@1+ (0.01,0) [0|42949672.95] "l"  HMIIOM
 SG_ CCTime_ISig_4 : 32|32@1+ (1,0) [0|4294967295] "s"  HMIIOM

BO_ 2566401316 VMCU_BB2_24P: 8 VMCU
 SG_ MIStatusExtVMCU : 4|2@1+ (1,0) [0|0] ""  EMS
 SG_ MIDistinctWarningExtVMCU : 0|4@1+ (1,0) [0|0] ""  EMS
 SG_ EngTrueIdleSpeedFuel_ISig_4 : 32|32@1+ (0.01,0) [0|42949672.95] "l"  HMIIOM
 SG_ LngTotalRemainingGasVolume2 : 16|16@1+ (1,0) [0|65535] "kg"  HMIIOM

BO_ 2566356772 VMCU_BB2_23P: 8 VMCU
 SG_ FuelConsumptionVehicleStopped_IS : 32|32@1+ (0.01,0) [0|42949672.95] "l"  HMIIOM
 SG_ FuelConsumptionVehicleRunning_IS : 0|32@1+ (0.01,0) [0|42949672.95] "l"  HMIIOM

BO_ 2566312228 VMCU_BB2_22P: 8 VMCU
 SG_ AdBlueConsumptVehicleRunning_ISi : 0|32@1+ (0.01,0) [0|42949672.95] "l"  HMIIOM
 SG_ AdBlueConsumptVehicleStopped_ISi : 32|32@1+ (0.01,0) [0|42949672.95] "l"  HMIIOM

CM_ SG_ 2548896548 FrontAxle1Load_ISig_4 "65024 - 65279 Error ; 65280 - 65535 Not available";
CM_ SG_ 2548896548 FrontAxle2Load_ISig_4 "65024 - 65279 Error ; 65280 - 65535 Not available";
CM_ SG_ 2566891300 Driver1CumulativeBreakTime_ISig_ "65024 - 65279 Error ; 65280 - 65535 Not available";
CM_ SG_ 2566891300 Driver1ContinuousDrivingTime_ISi "65024 - 65279 Error ; 65280 - 65535 Not available";
CM_ SG_ 2566891300 Drvr1CurDurationSelectedActy_ISi "65024 - 65279 Error ; 65280 - 65535 Not available";
CM_ SG_ 2566490404 AtLeastOnePTOActivationTime_ISig "4294967295 Not available";
CM_ SG_ 2566445860 EngineGreenAreaOutFuel_ISig_4 "4294967295 Not available";
CM_ SG_ 2566445860 CCTime_ISig_4 "4294967295 Not available";
CM_ SG_ 2566401316 EngTrueIdleSpeedFuel_ISig_4 "4294967295 Not available";
CM_ SG_ 2566356772 FuelConsumptionVehicleStopped_IS "4294967295 Not available";
CM_ SG_ 2566356772 FuelConsumptionVehicleRunning_IS "4294967295 Not available";
CM_ SG_ 2566312228 AdBlueConsumptVehicleRunning_ISi "4294967295 Not available";
CM_ SG_ 2566312228 AdBlueConsumptVehicleStopped_ISi "4294967295 Not available";
BA_DEF_ BO_  "GenMsgStartDelayTime" INT 0 0;
BA_DEF_ BO_  "GenMsgDelayTime" INT 0 0;
BA_DEF_ BO_  "GenMsgCycleTime" INT 0 0;
BA_DEF_ BO_  "GenMsgSendType" ENUM  "Cyclic","NotUsed","NotUsed","NotUsed","NotUsed","NotUsed","NotUsed","IfActive","NoMsgSendType","NotUsed";
BA_DEF_ SG_  "GenSigStartValue" INT 0 0;
BA_DEF_ SG_  "GenSigCycleTimeActive" INT 0 0;
BA_DEF_ SG_  "GenSigCycleTime" INT 0 0;
BA_DEF_ SG_  "GenSigSendType" ENUM  "Cyclic","OnWrite","OnWriteWithRepetition","OnChange","OnChangeWithRepetition","IfActive","IfActiveWithRepetition","NoSigSendType","NotUsed","NotUsed","NotUsed","NotUsed","NotUsed";
BA_DEF_ BO_  "VFrameFormat" ENUM  "StandardCAN","ExtendedCAN","reserved","J1939PG";
BA_DEF_ SG_  "SigType" ENUM  "Default","Range","RangeSigned","ASCII","Discrete","Control","ReferencePGN","DTC","StringDelimiter","StringLength","StringLengthControl";
BA_DEF_ SG_  "SeToolVersion_SIGNAL" STRING ;
BA_DEF_ SG_  "SeToolUniqueID_SIGNAL" STRING ;
BA_DEF_ SG_  "SeToolOwnerSigGroup_SIGNAL" STRING ;
BA_DEF_ SG_  "SeToolOwnerSigGroupID_SIGNAL" STRING ;
BA_DEF_ SG_  "SeToolName_SIGNAL" STRING ;
BA_DEF_ SG_  "SeToolItemID_SIGNAL" STRING ;
BA_DEF_ SG_  "SeToolAncestorID_SIGNAL" STRING ;
BA_DEF_ SG_  "Platform_VMCU1_Sig" ENUM  "No","Yes";
BA_DEF_ BO_  "NmAsrMessage" ENUM  "No","Yes";
BA_DEF_ SG_  "NeedsUpdateBit" ENUM  "No","Yes";
BA_DEF_ SG_  "MmAnSignal" ENUM  "No","Yes";
BA_DEF_ SG_  "GenSigMaxLatency" INT 0 65535;
BA_DEF_ SG_  "GenSigILSupport" ENUM  "Yes","No";
BA_DEF_ BO_  "GenMsgRequestable" INT 0 1;
BA_DEF_ BO_  "GenMsgILSupport" ENUM  "No","Yes";
BA_DEF_ BO_  "DiagUUDTResponse" ENUM  "No","Yes";
BA_DEF_ BO_  "DiagState" ENUM  "No","Yes";
BA_DEF_ BO_  "DiagResponse" ENUM  "No","Yes";
BA_DEF_ BO_  "DiagRequest" ENUM  "No","Yes";
BA_DEF_ BO_  "DiagConnection" HEX 0 65535;
BA_DEF_ BO_  "CanTpSTmin" INT 0 255;
BA_DEF_ BO_  "CanTpFcFrameId" HEX 0 2147483647;
BA_DEF_ BO_  "CanTpBs" INT 0 255;
BA_DEF_ SG_  "SystemSignalLongSymbol" STRING ;
BA_DEF_REL_ BU_SG_REL_  "GenSigTimeoutTime" INT 0 65535;
BA_DEF_REL_ BU_SG_REL_  "GenSigFirstTimeoutTime" INT 0 65535;
BA_DEF_DEF_  "GenMsgStartDelayTime" 0;
BA_DEF_DEF_  "GenMsgDelayTime" 0;
BA_DEF_DEF_  "GenMsgCycleTime" 0;
BA_DEF_DEF_  "GenMsgSendType" "Cyclic";
BA_DEF_DEF_  "GenSigStartValue" 0;
BA_DEF_DEF_  "GenSigCycleTimeActive" 0;
BA_DEF_DEF_  "GenSigCycleTime" 0;
BA_DEF_DEF_  "GenSigSendType" "Cyclic";
BA_DEF_DEF_  "VFrameFormat" "ExtendedCAN";
BA_DEF_DEF_  "SigType" "Default";
BA_DEF_DEF_  "SeToolVersion_SIGNAL" "";
BA_DEF_DEF_  "SeToolUniqueID_SIGNAL" "";
BA_DEF_DEF_  "SeToolOwnerSigGroup_SIGNAL" "";
BA_DEF_DEF_  "SeToolOwnerSigGroupID_SIGNAL" "";
BA_DEF_DEF_  "SeToolName_SIGNAL" "";
BA_DEF_DEF_  "SeToolItemID_SIGNAL" "";
BA_DEF_DEF_  "SeToolAncestorID_SIGNAL" "";
BA_DEF_DEF_  "Platform_VMCU1_Sig" "No";
BA_DEF_DEF_  "NmAsrMessage" "No";
BA_DEF_DEF_  "NeedsUpdateBit" "No";
BA_DEF_DEF_  "MmAnSignal" "No";
BA_DEF_DEF_  "GenSigMaxLatency" 0;
BA_DEF_DEF_  "GenSigILSupport" "Yes";
BA_DEF_DEF_  "GenMsgRequestable" 1;
BA_DEF_DEF_  "GenMsgILSupport" "Yes";
BA_DEF_DEF_  "DiagUUDTResponse" "No";
BA_DEF_DEF_  "DiagState" "No";
BA_DEF_DEF_  "DiagResponse" "No";
BA_DEF_DEF_  "DiagRequest" "No";
BA_DEF_DEF_  "DiagConnection" 0;
BA_DEF_DEF_  "CanTpSTmin" 0;
BA_DEF_DEF_  "CanTpFcFrameId" 2147483647;
BA_DEF_DEF_  "CanTpBs" 255;
BA_DEF_DEF_REL_ "GenSigTimeoutTime" 0;
BA_DEF_DEF_REL_ "GenSigFirstTimeoutTime" 0;
BA_DEF_DEF_  "SystemSignalLongSymbol" "";
BA_ "CanTpFcFrameId" BO_ 2566560036 419076389;
BA_ "GenMsgSendType" BO_ 2566560036 8;
BA_ "GenMsgDelayTime" BO_ 2566560036 2500;
BA_ "GenMsgStartDelayTime" BO_ 2566560036 50;
BA_ "GenMsgILSupport" BO_ 2566044965 0;
BA_ "GenMsgSendType" BO_ 2566044965 8;
BA_ "CanTpFcFrameId" BO_ 2566044964 418561317;
BA_ "GenMsgSendType" BO_ 2566044964 8;
BA_ "GenMsgDelayTime" BO_ 2566044964 110;
BA_ "GenMsgILSupport" BO_ 2566089509 0;
BA_ "GenMsgSendType" BO_ 2566089509 8;
BA_ "CanTpFcFrameId" BO_ 2566089508 418605861;
BA_ "GenMsgSendType" BO_ 2566089508 8;
BA_ "GenMsgDelayTime" BO_ 2566089508 110;
BA_ "GenMsgSendType" BO_ 2565822244 8;
BA_ "GenMsgDelayTime" BO_ 2565822244 80;
BA_ "GenMsgStartDelayTime" BO_ 2565822244 50;
BA_ "GenMsgCycleTime" BO_ 2548896548 250;
BA_ "GenMsgStartDelayTime" BO_ 2548896548 25;
BA_ "GenMsgCycleTime" BO_ 2566891300 1000;
BA_ "GenMsgStartDelayTime" BO_ 2566891300 295;
BA_ "GenMsgCycleTime" BO_ 2566490404 1000;
BA_ "GenMsgStartDelayTime" BO_ 2566490404 390;
BA_ "GenMsgCycleTime" BO_ 2566445860 1000;
BA_ "GenMsgStartDelayTime" BO_ 2566445860 485;
BA_ "GenMsgCycleTime" BO_ 2566401316 1000;
BA_ "GenMsgStartDelayTime" BO_ 2566401316 580;
BA_ "GenMsgCycleTime" BO_ 2566356772 1000;
BA_ "GenMsgStartDelayTime" BO_ 2566356772 675;
BA_ "GenMsgCycleTime" BO_ 2566312228 1000;
BA_ "GenMsgStartDelayTime" BO_ 2566312228 770;
BA_ "GenSigSendType" SG_ 2566560036 MaintInfoGrp_MaintOption30_ISig_ 1;
BA_ "GenSigStartValue" SG_ 2566560036 MaintInfoGrp_MaintOption30_ISig_ 15;
BA_ "GenSigMaxLatency" SG_ 2566560036 MaintInfoGrp_MaintOption30_ISig_ 3000;
BA_ "Platform_VMCU1_Sig" SG_ 2566560036 MaintInfoGrp_MaintOption30_ISig_ 1;
BA_ "SystemSignalLongSymbol" SG_ 2566560036 MaintInfoGrp_MaintOption30_ISig_ "MaintInfoGrp_MaintOption30_ISig_4";
BA_ "GenSigSendType" SG_ 2566560036 MaintInfoGrp_Unit36_ISig_4 1;
BA_ "GenSigStartValue" SG_ 2566560036 MaintInfoGrp_Unit36_ISig_4 7;
BA_ "GenSigMaxLatency" SG_ 2566560036 MaintInfoGrp_Unit36_ISig_4 3000;
BA_ "Platform_VMCU1_Sig" SG_ 2566560036 MaintInfoGrp_Unit36_ISig_4 1;
BA_ "GenSigSendType" SG_ 2566560036 MaintInfoGrp_MaintOption33_ISig_ 1;
BA_ "GenSigStartValue" SG_ 2566560036 MaintInfoGrp_MaintOption33_ISig_ 15;
BA_ "GenSigMaxLatency" SG_ 2566560036 MaintInfoGrp_MaintOption33_ISig_ 3000;
BA_ "Platform_VMCU1_Sig" SG_ 2566560036 MaintInfoGrp_MaintOption33_ISig_ 1;
BA_ "SystemSignalLongSymbol" SG_ 2566560036 MaintInfoGrp_MaintOption33_ISig_ "MaintInfoGrp_MaintOption33_ISig_4";
BA_ "GenSigSendType" SG_ 2566560036 MaintInfoGrp_ResetAuthorized32_I 1;
BA_ "GenSigStartValue" SG_ 2566560036 MaintInfoGrp_ResetAuthorized32_I 3;
BA_ "GenSigMaxLatency" SG_ 2566560036 MaintInfoGrp_ResetAuthorized32_I 3000;
BA_ "Platform_VMCU1_Sig" SG_ 2566560036 MaintInfoGrp_ResetAuthorized32_I 1;
BA_ "SystemSignalLongSymbol" SG_ 2566560036 MaintInfoGrp_ResetAuthorized32_I "MaintInfoGrp_ResetAuthorized32_ISig_4";
BA_ "GenSigSendType" SG_ 2566560036 MaintInfoGrp_Status10_ISig_4 1;
BA_ "GenSigStartValue" SG_ 2566560036 MaintInfoGrp_Status10_ISig_4 7;
BA_ "GenSigMaxLatency" SG_ 2566560036 MaintInfoGrp_Status10_ISig_4 3000;
BA_ "Platform_VMCU1_Sig" SG_ 2566560036 MaintInfoGrp_Status10_ISig_4 1;
BA_ "GenSigSendType" SG_ 2566560036 MaintInfoGrp_Unit2_ISig_4 1;
BA_ "GenSigStartValue" SG_ 2566560036 MaintInfoGrp_Unit2_ISig_4 7;
BA_ "GenSigMaxLatency" SG_ 2566560036 MaintInfoGrp_Unit2_ISig_4 3000;
BA_ "Platform_VMCU1_Sig" SG_ 2566560036 MaintInfoGrp_Unit2_ISig_4 1;
BA_ "GenSigSendType" SG_ 2566560036 MaintInfoGrp_Unit14_ISig_4 1;
BA_ "GenSigStartValue" SG_ 2566560036 MaintInfoGrp_Unit14_ISig_4 7;
BA_ "GenSigMaxLatency" SG_ 2566560036 MaintInfoGrp_Unit14_ISig_4 3000;
BA_ "Platform_VMCU1_Sig" SG_ 2566560036 MaintInfoGrp_Unit14_ISig_4 1;
BA_ "GenSigSendType" SG_ 2566560036 MaintInfoGrp_ResetAuthorized28_I 1;
BA_ "GenSigStartValue" SG_ 2566560036 MaintInfoGrp_ResetAuthorized28_I 3;
BA_ "GenSigMaxLatency" SG_ 2566560036 MaintInfoGrp_ResetAuthorized28_I 3000;
BA_ "Platform_VMCU1_Sig" SG_ 2566560036 MaintInfoGrp_ResetAuthorized28_I 1;
BA_ "SystemSignalLongSymbol" SG_ 2566560036 MaintInfoGrp_ResetAuthorized28_I "MaintInfoGrp_ResetAuthorized28_ISig_4";
BA_ "GenSigSendType" SG_ 2566560036 MaintInfoGrp_ResetAuthorized10_I 1;
BA_ "GenSigStartValue" SG_ 2566560036 MaintInfoGrp_ResetAuthorized10_I 3;
BA_ "GenSigMaxLatency" SG_ 2566560036 MaintInfoGrp_ResetAuthorized10_I 3000;
BA_ "Platform_VMCU1_Sig" SG_ 2566560036 MaintInfoGrp_ResetAuthorized10_I 1;
BA_ "SystemSignalLongSymbol" SG_ 2566560036 MaintInfoGrp_ResetAuthorized10_I "MaintInfoGrp_ResetAuthorized10_ISig_4";
BA_ "GenSigSendType" SG_ 2566560036 MaintInfoGrp_Status31_ISig_4 1;
BA_ "GenSigStartValue" SG_ 2566560036 MaintInfoGrp_Status31_ISig_4 7;
BA_ "GenSigMaxLatency" SG_ 2566560036 MaintInfoGrp_Status31_ISig_4 3000;
BA_ "Platform_VMCU1_Sig" SG_ 2566560036 MaintInfoGrp_Status31_ISig_4 1;
BA_ "GenSigSendType" SG_ 2566560036 MaintInfoGrp_Unit32_ISig_4 1;
BA_ "GenSigStartValue" SG_ 2566560036 MaintInfoGrp_Unit32_ISig_4 7;
BA_ "GenSigMaxLatency" SG_ 2566560036 MaintInfoGrp_Unit32_ISig_4 3000;
BA_ "Platform_VMCU1_Sig" SG_ 2566560036 MaintInfoGrp_Unit32_ISig_4 1;
BA_ "GenSigSendType" SG_ 2566560036 MaintInfoGrp_Status15_ISig_4 1;
BA_ "GenSigStartValue" SG_ 2566560036 MaintInfoGrp_Status15_ISig_4 7;
BA_ "GenSigMaxLatency" SG_ 2566560036 MaintInfoGrp_Status15_ISig_4 3000;
BA_ "Platform_VMCU1_Sig" SG_ 2566560036 MaintInfoGrp_Status15_ISig_4 1;
BA_ "GenSigSendType" SG_ 2566560036 MaintInfoGrp_Supported19_ISig_4 1;
BA_ "GenSigStartValue" SG_ 2566560036 MaintInfoGrp_Supported19_ISig_4 3;
BA_ "GenSigMaxLatency" SG_ 2566560036 MaintInfoGrp_Supported19_ISig_4 3000;
BA_ "Platform_VMCU1_Sig" SG_ 2566560036 MaintInfoGrp_Supported19_ISig_4 1;
BA_ "GenSigSendType" SG_ 2566560036 MaintInfoGrp_Unit34_ISig_4 1;
BA_ "GenSigStartValue" SG_ 2566560036 MaintInfoGrp_Unit34_ISig_4 7;
BA_ "GenSigMaxLatency" SG_ 2566560036 MaintInfoGrp_Unit34_ISig_4 3000;
BA_ "Platform_VMCU1_Sig" SG_ 2566560036 MaintInfoGrp_Unit34_ISig_4 1;
BA_ "GenSigSendType" SG_ 2566560036 MaintInfoGrp_Data17_ISig_4 1;
BA_ "GenSigStartValue" SG_ 2566560036 MaintInfoGrp_Data17_ISig_4 4294967295;
BA_ "GenSigMaxLatency" SG_ 2566560036 MaintInfoGrp_Data17_ISig_4 3000;
BA_ "Platform_VMCU1_Sig" SG_ 2566560036 MaintInfoGrp_Data17_ISig_4 1;
BA_ "GenSigSendType" SG_ 2566560036 MaintInfoGrp_Unit26_ISig_4 1;
BA_ "GenSigStartValue" SG_ 2566560036 MaintInfoGrp_Unit26_ISig_4 7;
BA_ "GenSigMaxLatency" SG_ 2566560036 MaintInfoGrp_Unit26_ISig_4 3000;
BA_ "Platform_VMCU1_Sig" SG_ 2566560036 MaintInfoGrp_Unit26_ISig_4 1;
BA_ "GenSigSendType" SG_ 2566560036 MaintInfoGrp_Data24_ISig_4 1;
BA_ "GenSigStartValue" SG_ 2566560036 MaintInfoGrp_Data24_ISig_4 4294967295;
BA_ "GenSigMaxLatency" SG_ 2566560036 MaintInfoGrp_Data24_ISig_4 3000;
BA_ "Platform_VMCU1_Sig" SG_ 2566560036 MaintInfoGrp_Data24_ISig_4 1;
BA_ "GenSigSendType" SG_ 2566560036 MaintInfoGrp_ResetAuthorized24_I 1;
BA_ "GenSigStartValue" SG_ 2566560036 MaintInfoGrp_ResetAuthorized24_I 3;
BA_ "GenSigMaxLatency" SG_ 2566560036 MaintInfoGrp_ResetAuthorized24_I 3000;
BA_ "Platform_VMCU1_Sig" SG_ 2566560036 MaintInfoGrp_ResetAuthorized24_I 1;
BA_ "SystemSignalLongSymbol" SG_ 2566560036 MaintInfoGrp_ResetAuthorized24_I "MaintInfoGrp_ResetAuthorized24_ISig_4";
BA_ "GenSigSendType" SG_ 2566560036 MaintInfoGrp_ResetAuthorized34_I 1;
BA_ "GenSigStartValue" SG_ 2566560036 MaintInfoGrp_ResetAuthorized34_I 3;
BA_ "GenSigMaxLatency" SG_ 2566560036 MaintInfoGrp_ResetAuthorized34_I 3000;
BA_ "Platform_VMCU1_Sig" SG_ 2566560036 MaintInfoGrp_ResetAuthorized34_I 1;
BA_ "SystemSignalLongSymbol" SG_ 2566560036 MaintInfoGrp_ResetAuthorized34_I "MaintInfoGrp_ResetAuthorized34_ISig_4";
BA_ "GenSigSendType" SG_ 2566560036 MaintInfoGrp_Unit28_ISig_4 1;
BA_ "GenSigStartValue" SG_ 2566560036 MaintInfoGrp_Unit28_ISig_4 7;
BA_ "GenSigMaxLatency" SG_ 2566560036 MaintInfoGrp_Unit28_ISig_4 3000;
BA_ "Platform_VMCU1_Sig" SG_ 2566560036 MaintInfoGrp_Unit28_ISig_4 1;
BA_ "GenSigSendType" SG_ 2566560036 MaintInfoGrp_Status26_ISig_4 1;
BA_ "GenSigStartValue" SG_ 2566560036 MaintInfoGrp_Status26_ISig_4 7;
BA_ "GenSigMaxLatency" SG_ 2566560036 MaintInfoGrp_Status26_ISig_4 3000;
BA_ "Platform_VMCU1_Sig" SG_ 2566560036 MaintInfoGrp_Status26_ISig_4 1;
BA_ "GenSigSendType" SG_ 2566560036 MaintInfoGrp_Unit10_ISig_4 1;
BA_ "GenSigStartValue" SG_ 2566560036 MaintInfoGrp_Unit10_ISig_4 7;
BA_ "GenSigMaxLatency" SG_ 2566560036 MaintInfoGrp_Unit10_ISig_4 3000;
BA_ "Platform_VMCU1_Sig" SG_ 2566560036 MaintInfoGrp_Unit10_ISig_4 1;
BA_ "GenSigSendType" SG_ 2566560036 MaintInfoGrp_Data12_ISig_4 1;
BA_ "GenSigStartValue" SG_ 2566560036 MaintInfoGrp_Data12_ISig_4 4294967295;
BA_ "GenSigMaxLatency" SG_ 2566560036 MaintInfoGrp_Data12_ISig_4 3000;
BA_ "Platform_VMCU1_Sig" SG_ 2566560036 MaintInfoGrp_Data12_ISig_4 1;
BA_ "GenSigSendType" SG_ 2566560036 MaintInfoGrp_ResetAuthorized38_I 1;
BA_ "GenSigStartValue" SG_ 2566560036 MaintInfoGrp_ResetAuthorized38_I 3;
BA_ "GenSigMaxLatency" SG_ 2566560036 MaintInfoGrp_ResetAuthorized38_I 3000;
BA_ "Platform_VMCU1_Sig" SG_ 2566560036 MaintInfoGrp_ResetAuthorized38_I 1;
BA_ "SystemSignalLongSymbol" SG_ 2566560036 MaintInfoGrp_ResetAuthorized38_I "MaintInfoGrp_ResetAuthorized38_ISig_4";
BA_ "GenSigSendType" SG_ 2566560036 MaintInfoGrp_MaintOption14_ISig_ 1;
BA_ "GenSigStartValue" SG_ 2566560036 MaintInfoGrp_MaintOption14_ISig_ 15;
BA_ "GenSigMaxLatency" SG_ 2566560036 MaintInfoGrp_MaintOption14_ISig_ 3000;
BA_ "Platform_VMCU1_Sig" SG_ 2566560036 MaintInfoGrp_MaintOption14_ISig_ 1;
BA_ "SystemSignalLongSymbol" SG_ 2566560036 MaintInfoGrp_MaintOption14_ISig_ "MaintInfoGrp_MaintOption14_ISig_4";
BA_ "GenSigSendType" SG_ 2566560036 MaintInfoGrp_MaintOption17_ISig_ 1;
BA_ "GenSigStartValue" SG_ 2566560036 MaintInfoGrp_MaintOption17_ISig_ 15;
BA_ "GenSigMaxLatency" SG_ 2566560036 MaintInfoGrp_MaintOption17_ISig_ 3000;
BA_ "Platform_VMCU1_Sig" SG_ 2566560036 MaintInfoGrp_MaintOption17_ISig_ 1;
BA_ "SystemSignalLongSymbol" SG_ 2566560036 MaintInfoGrp_MaintOption17_ISig_ "MaintInfoGrp_MaintOption17_ISig_4";
BA_ "GenSigSendType" SG_ 2566560036 MaintInfoGrp_Status33_ISig_4 1;
BA_ "GenSigStartValue" SG_ 2566560036 MaintInfoGrp_Status33_ISig_4 7;
BA_ "GenSigMaxLatency" SG_ 2566560036 MaintInfoGrp_Status33_ISig_4 3000;
BA_ "Platform_VMCU1_Sig" SG_ 2566560036 MaintInfoGrp_Status33_ISig_4 1;
BA_ "GenSigSendType" SG_ 2566560036 MaintInfoGrp_Unit6_ISig_4 1;
BA_ "GenSigStartValue" SG_ 2566560036 MaintInfoGrp_Unit6_ISig_4 7;
BA_ "GenSigMaxLatency" SG_ 2566560036 MaintInfoGrp_Unit6_ISig_4 3000;
BA_ "Platform_VMCU1_Sig" SG_ 2566560036 MaintInfoGrp_Unit6_ISig_4 1;
BA_ "GenSigSendType" SG_ 2566560036 MaintInfoGrp_Supported7_ISig_4 1;
BA_ "GenSigStartValue" SG_ 2566560036 MaintInfoGrp_Supported7_ISig_4 3;
BA_ "GenSigMaxLatency" SG_ 2566560036 MaintInfoGrp_Supported7_ISig_4 3000;
BA_ "Platform_VMCU1_Sig" SG_ 2566560036 MaintInfoGrp_Supported7_ISig_4 1;
BA_ "GenSigSendType" SG_ 2566560036 MaintInfoGrp_Status7_ISig_4 1;
BA_ "GenSigStartValue" SG_ 2566560036 MaintInfoGrp_Status7_ISig_4 7;
BA_ "GenSigMaxLatency" SG_ 2566560036 MaintInfoGrp_Status7_ISig_4 3000;
BA_ "Platform_VMCU1_Sig" SG_ 2566560036 MaintInfoGrp_Status7_ISig_4 1;
BA_ "GenSigSendType" SG_ 2566560036 MaintInfoGrp_ResetAuthorized2_IS 1;
BA_ "GenSigStartValue" SG_ 2566560036 MaintInfoGrp_ResetAuthorized2_IS 3;
BA_ "GenSigMaxLatency" SG_ 2566560036 MaintInfoGrp_ResetAuthorized2_IS 3000;
BA_ "Platform_VMCU1_Sig" SG_ 2566560036 MaintInfoGrp_ResetAuthorized2_IS 1;
BA_ "SystemSignalLongSymbol" SG_ 2566560036 MaintInfoGrp_ResetAuthorized2_IS "MaintInfoGrp_ResetAuthorized2_ISig_4";
BA_ "GenSigSendType" SG_ 2566560036 MaintInfoGrp_MaintOption27_ISig_ 1;
BA_ "GenSigStartValue" SG_ 2566560036 MaintInfoGrp_MaintOption27_ISig_ 15;
BA_ "GenSigMaxLatency" SG_ 2566560036 MaintInfoGrp_MaintOption27_ISig_ 3000;
BA_ "Platform_VMCU1_Sig" SG_ 2566560036 MaintInfoGrp_MaintOption27_ISig_ 1;
BA_ "SystemSignalLongSymbol" SG_ 2566560036 MaintInfoGrp_MaintOption27_ISig_ "MaintInfoGrp_MaintOption27_ISig_4";
BA_ "GenSigSendType" SG_ 2566560036 MaintInfoGrp_Supported36_ISig_4 1;
BA_ "GenSigStartValue" SG_ 2566560036 MaintInfoGrp_Supported36_ISig_4 3;
BA_ "GenSigMaxLatency" SG_ 2566560036 MaintInfoGrp_Supported36_ISig_4 3000;
BA_ "Platform_VMCU1_Sig" SG_ 2566560036 MaintInfoGrp_Supported36_ISig_4 1;
BA_ "GenSigSendType" SG_ 2566560036 MaintInfoGrp_Unit22_ISig_4 1;
BA_ "GenSigStartValue" SG_ 2566560036 MaintInfoGrp_Unit22_ISig_4 7;
BA_ "GenSigMaxLatency" SG_ 2566560036 MaintInfoGrp_Unit22_ISig_4 3000;
BA_ "Platform_VMCU1_Sig" SG_ 2566560036 MaintInfoGrp_Unit22_ISig_4 1;
BA_ "GenSigSendType" SG_ 2566560036 MaintInfoGrp_Unit18_ISig_4 1;
BA_ "GenSigStartValue" SG_ 2566560036 MaintInfoGrp_Unit18_ISig_4 7;
BA_ "GenSigMaxLatency" SG_ 2566560036 MaintInfoGrp_Unit18_ISig_4 3000;
BA_ "Platform_VMCU1_Sig" SG_ 2566560036 MaintInfoGrp_Unit18_ISig_4 1;
BA_ "GenSigSendType" SG_ 2566560036 MaintInfoGrp_MaintOption28_ISig_ 1;
BA_ "GenSigStartValue" SG_ 2566560036 MaintInfoGrp_MaintOption28_ISig_ 15;
BA_ "GenSigMaxLatency" SG_ 2566560036 MaintInfoGrp_MaintOption28_ISig_ 3000;
BA_ "Platform_VMCU1_Sig" SG_ 2566560036 MaintInfoGrp_MaintOption28_ISig_ 1;
BA_ "SystemSignalLongSymbol" SG_ 2566560036 MaintInfoGrp_MaintOption28_ISig_ "MaintInfoGrp_MaintOption28_ISig_4";
BA_ "GenSigSendType" SG_ 2566560036 MaintInfoGrp_Supported18_ISig_4 1;
BA_ "GenSigStartValue" SG_ 2566560036 MaintInfoGrp_Supported18_ISig_4 3;
BA_ "GenSigMaxLatency" SG_ 2566560036 MaintInfoGrp_Supported18_ISig_4 3000;
BA_ "Platform_VMCU1_Sig" SG_ 2566560036 MaintInfoGrp_Supported18_ISig_4 1;
BA_ "GenSigSendType" SG_ 2566560036 MaintInfoGrp_Status22_ISig_4 1;
BA_ "GenSigStartValue" SG_ 2566560036 MaintInfoGrp_Status22_ISig_4 7;
BA_ "GenSigMaxLatency" SG_ 2566560036 MaintInfoGrp_Status22_ISig_4 3000;
BA_ "Platform_VMCU1_Sig" SG_ 2566560036 MaintInfoGrp_Status22_ISig_4 1;
BA_ "GenSigSendType" SG_ 2566560036 MaintInfoGrp_Status30_ISig_4 1;
BA_ "GenSigStartValue" SG_ 2566560036 MaintInfoGrp_Status30_ISig_4 7;
BA_ "GenSigMaxLatency" SG_ 2566560036 MaintInfoGrp_Status30_ISig_4 3000;
BA_ "Platform_VMCU1_Sig" SG_ 2566560036 MaintInfoGrp_Status30_ISig_4 1;
BA_ "GenSigSendType" SG_ 2566560036 MaintInfoGrp_Status20_ISig_4 1;
BA_ "GenSigStartValue" SG_ 2566560036 MaintInfoGrp_Status20_ISig_4 7;
BA_ "GenSigMaxLatency" SG_ 2566560036 MaintInfoGrp_Status20_ISig_4 3000;
BA_ "Platform_VMCU1_Sig" SG_ 2566560036 MaintInfoGrp_Status20_ISig_4 1;
BA_ "GenSigSendType" SG_ 2566560036 MaintInfoGrp_Status38_ISig_4 1;
BA_ "GenSigStartValue" SG_ 2566560036 MaintInfoGrp_Status38_ISig_4 7;
BA_ "GenSigMaxLatency" SG_ 2566560036 MaintInfoGrp_Status38_ISig_4 3000;
BA_ "Platform_VMCU1_Sig" SG_ 2566560036 MaintInfoGrp_Status38_ISig_4 1;
BA_ "GenSigSendType" SG_ 2566560036 MaintInfoGrp_Data38_ISig_4 1;
BA_ "GenSigStartValue" SG_ 2566560036 MaintInfoGrp_Data38_ISig_4 4294967295;
BA_ "GenSigMaxLatency" SG_ 2566560036 MaintInfoGrp_Data38_ISig_4 3000;
BA_ "Platform_VMCU1_Sig" SG_ 2566560036 MaintInfoGrp_Data38_ISig_4 1;
BA_ "GenSigSendType" SG_ 2566560036 MaintInfoGrp_ResetAuthorized7_IS 1;
BA_ "GenSigStartValue" SG_ 2566560036 MaintInfoGrp_ResetAuthorized7_IS 3;
BA_ "GenSigMaxLatency" SG_ 2566560036 MaintInfoGrp_ResetAuthorized7_IS 3000;
BA_ "Platform_VMCU1_Sig" SG_ 2566560036 MaintInfoGrp_ResetAuthorized7_IS 1;
BA_ "SystemSignalLongSymbol" SG_ 2566560036 MaintInfoGrp_ResetAuthorized7_IS "MaintInfoGrp_ResetAuthorized7_ISig_4";
BA_ "GenSigSendType" SG_ 2566560036 MaintInfoGrp_Data19_ISig_4 1;
BA_ "GenSigStartValue" SG_ 2566560036 MaintInfoGrp_Data19_ISig_4 4294967295;
BA_ "GenSigMaxLatency" SG_ 2566560036 MaintInfoGrp_Data19_ISig_4 3000;
BA_ "Platform_VMCU1_Sig" SG_ 2566560036 MaintInfoGrp_Data19_ISig_4 1;
BA_ "GenSigSendType" SG_ 2566560036 MaintInfoGrp_ResetAuthorized19_I 1;
BA_ "GenSigStartValue" SG_ 2566560036 MaintInfoGrp_ResetAuthorized19_I 3;
BA_ "GenSigMaxLatency" SG_ 2566560036 MaintInfoGrp_ResetAuthorized19_I 3000;
BA_ "Platform_VMCU1_Sig" SG_ 2566560036 MaintInfoGrp_ResetAuthorized19_I 1;
BA_ "SystemSignalLongSymbol" SG_ 2566560036 MaintInfoGrp_ResetAuthorized19_I "MaintInfoGrp_ResetAuthorized19_ISig_4";
BA_ "GenSigSendType" SG_ 2566560036 MaintInfoGrp_ResetAuthorized12_I 1;
BA_ "GenSigStartValue" SG_ 2566560036 MaintInfoGrp_ResetAuthorized12_I 3;
BA_ "GenSigMaxLatency" SG_ 2566560036 MaintInfoGrp_ResetAuthorized12_I 3000;
BA_ "Platform_VMCU1_Sig" SG_ 2566560036 MaintInfoGrp_ResetAuthorized12_I 1;
BA_ "SystemSignalLongSymbol" SG_ 2566560036 MaintInfoGrp_ResetAuthorized12_I "MaintInfoGrp_ResetAuthorized12_ISig_4";
BA_ "GenSigSendType" SG_ 2566560036 MaintInfoGrp_MaintOption8_ISig_4 1;
BA_ "GenSigStartValue" SG_ 2566560036 MaintInfoGrp_MaintOption8_ISig_4 15;
BA_ "GenSigMaxLatency" SG_ 2566560036 MaintInfoGrp_MaintOption8_ISig_4 3000;
BA_ "Platform_VMCU1_Sig" SG_ 2566560036 MaintInfoGrp_MaintOption8_ISig_4 1;
BA_ "GenSigSendType" SG_ 2566560036 MaintInfoGrp_MaintOption9_ISig_4 1;
BA_ "GenSigStartValue" SG_ 2566560036 MaintInfoGrp_MaintOption9_ISig_4 15;
BA_ "GenSigMaxLatency" SG_ 2566560036 MaintInfoGrp_MaintOption9_ISig_4 3000;
BA_ "Platform_VMCU1_Sig" SG_ 2566560036 MaintInfoGrp_MaintOption9_ISig_4 1;
BA_ "GenSigSendType" SG_ 2566560036 MaintInfoGrp_ResetAuthorized13_I 1;
BA_ "GenSigStartValue" SG_ 2566560036 MaintInfoGrp_ResetAuthorized13_I 3;
BA_ "GenSigMaxLatency" SG_ 2566560036 MaintInfoGrp_ResetAuthorized13_I 3000;
BA_ "Platform_VMCU1_Sig" SG_ 2566560036 MaintInfoGrp_ResetAuthorized13_I 1;
BA_ "SystemSignalLongSymbol" SG_ 2566560036 MaintInfoGrp_ResetAuthorized13_I "MaintInfoGrp_ResetAuthorized13_ISig_4";
BA_ "GenSigSendType" SG_ 2566560036 MaintInfoGrp_Unit31_ISig_4 1;
BA_ "GenSigStartValue" SG_ 2566560036 MaintInfoGrp_Unit31_ISig_4 7;
BA_ "GenSigMaxLatency" SG_ 2566560036 MaintInfoGrp_Unit31_ISig_4 3000;
BA_ "Platform_VMCU1_Sig" SG_ 2566560036 MaintInfoGrp_Unit31_ISig_4 1;
BA_ "GenSigSendType" SG_ 2566560036 MaintInfoGrp_Status2_ISig_4 1;
BA_ "GenSigStartValue" SG_ 2566560036 MaintInfoGrp_Status2_ISig_4 7;
BA_ "GenSigMaxLatency" SG_ 2566560036 MaintInfoGrp_Status2_ISig_4 3000;
BA_ "Platform_VMCU1_Sig" SG_ 2566560036 MaintInfoGrp_Status2_ISig_4 1;
BA_ "GenSigSendType" SG_ 2566560036 MaintInfoGrp_ResetAuthorized5_IS 1;
BA_ "GenSigStartValue" SG_ 2566560036 MaintInfoGrp_ResetAuthorized5_IS 3;
BA_ "GenSigMaxLatency" SG_ 2566560036 MaintInfoGrp_ResetAuthorized5_IS 3000;
BA_ "Platform_VMCU1_Sig" SG_ 2566560036 MaintInfoGrp_ResetAuthorized5_IS 1;
BA_ "SystemSignalLongSymbol" SG_ 2566560036 MaintInfoGrp_ResetAuthorized5_IS "MaintInfoGrp_ResetAuthorized5_ISig_4";
BA_ "GenSigSendType" SG_ 2566560036 MaintInfoGrp_Supported33_ISig_4 1;
BA_ "GenSigStartValue" SG_ 2566560036 MaintInfoGrp_Supported33_ISig_4 3;
BA_ "GenSigMaxLatency" SG_ 2566560036 MaintInfoGrp_Supported33_ISig_4 3000;
BA_ "Platform_VMCU1_Sig" SG_ 2566560036 MaintInfoGrp_Supported33_ISig_4 1;
BA_ "GenSigSendType" SG_ 2566560036 MaintInfoGrp_Unit7_ISig_4 1;
BA_ "GenSigStartValue" SG_ 2566560036 MaintInfoGrp_Unit7_ISig_4 7;
BA_ "GenSigMaxLatency" SG_ 2566560036 MaintInfoGrp_Unit7_ISig_4 3000;
BA_ "Platform_VMCU1_Sig" SG_ 2566560036 MaintInfoGrp_Unit7_ISig_4 1;
BA_ "GenSigSendType" SG_ 2566560036 MaintInfoGrp_Supported34_ISig_4 1;
BA_ "GenSigStartValue" SG_ 2566560036 MaintInfoGrp_Supported34_ISig_4 3;
BA_ "GenSigMaxLatency" SG_ 2566560036 MaintInfoGrp_Supported34_ISig_4 3000;
BA_ "Platform_VMCU1_Sig" SG_ 2566560036 MaintInfoGrp_Supported34_ISig_4 1;
BA_ "GenSigSendType" SG_ 2566560036 MaintInfoGrp_Data16_ISig_4 1;
BA_ "GenSigStartValue" SG_ 2566560036 MaintInfoGrp_Data16_ISig_4 4294967295;
BA_ "GenSigMaxLatency" SG_ 2566560036 MaintInfoGrp_Data16_ISig_4 3000;
BA_ "Platform_VMCU1_Sig" SG_ 2566560036 MaintInfoGrp_Data16_ISig_4 1;
BA_ "GenSigSendType" SG_ 2566560036 MaintInfoGrp_Unit19_ISig_4 1;
BA_ "GenSigStartValue" SG_ 2566560036 MaintInfoGrp_Unit19_ISig_4 7;
BA_ "GenSigMaxLatency" SG_ 2566560036 MaintInfoGrp_Unit19_ISig_4 3000;
BA_ "Platform_VMCU1_Sig" SG_ 2566560036 MaintInfoGrp_Unit19_ISig_4 1;
BA_ "GenSigSendType" SG_ 2566560036 MaintInfoGrp_ResetAuthorized21_I 1;
BA_ "GenSigStartValue" SG_ 2566560036 MaintInfoGrp_ResetAuthorized21_I 3;
BA_ "GenSigMaxLatency" SG_ 2566560036 MaintInfoGrp_ResetAuthorized21_I 3000;
BA_ "Platform_VMCU1_Sig" SG_ 2566560036 MaintInfoGrp_ResetAuthorized21_I 1;
BA_ "SystemSignalLongSymbol" SG_ 2566560036 MaintInfoGrp_ResetAuthorized21_I "MaintInfoGrp_ResetAuthorized21_ISig_4";
BA_ "GenSigSendType" SG_ 2566560036 MaintInfoGrp_ResetAuthorized31_I 1;
BA_ "GenSigStartValue" SG_ 2566560036 MaintInfoGrp_ResetAuthorized31_I 3;
BA_ "GenSigMaxLatency" SG_ 2566560036 MaintInfoGrp_ResetAuthorized31_I 3000;
BA_ "Platform_VMCU1_Sig" SG_ 2566560036 MaintInfoGrp_ResetAuthorized31_I 1;
BA_ "SystemSignalLongSymbol" SG_ 2566560036 MaintInfoGrp_ResetAuthorized31_I "MaintInfoGrp_ResetAuthorized31_ISig_4";
BA_ "GenSigSendType" SG_ 2566560036 MaintInfoGrp_Data28_ISig_4 1;
BA_ "GenSigStartValue" SG_ 2566560036 MaintInfoGrp_Data28_ISig_4 4294967295;
BA_ "GenSigMaxLatency" SG_ 2566560036 MaintInfoGrp_Data28_ISig_4 3000;
BA_ "Platform_VMCU1_Sig" SG_ 2566560036 MaintInfoGrp_Data28_ISig_4 1;
BA_ "GenSigSendType" SG_ 2566560036 MaintInfoGrp_ResetAuthorized3_IS 1;
BA_ "GenSigStartValue" SG_ 2566560036 MaintInfoGrp_ResetAuthorized3_IS 3;
BA_ "GenSigMaxLatency" SG_ 2566560036 MaintInfoGrp_ResetAuthorized3_IS 3000;
BA_ "Platform_VMCU1_Sig" SG_ 2566560036 MaintInfoGrp_ResetAuthorized3_IS 1;
BA_ "SystemSignalLongSymbol" SG_ 2566560036 MaintInfoGrp_ResetAuthorized3_IS "MaintInfoGrp_ResetAuthorized3_ISig_4";
BA_ "GenSigSendType" SG_ 2566560036 MaintInfoGrp_MaintOption34_ISig_ 1;
BA_ "GenSigStartValue" SG_ 2566560036 MaintInfoGrp_MaintOption34_ISig_ 15;
BA_ "GenSigMaxLatency" SG_ 2566560036 MaintInfoGrp_MaintOption34_ISig_ 3000;
BA_ "Platform_VMCU1_Sig" SG_ 2566560036 MaintInfoGrp_MaintOption34_ISig_ 1;
BA_ "SystemSignalLongSymbol" SG_ 2566560036 MaintInfoGrp_MaintOption34_ISig_ "MaintInfoGrp_MaintOption34_ISig_4";
BA_ "GenSigSendType" SG_ 2566560036 MaintInfoGrp_Status21_ISig_4 1;
BA_ "GenSigStartValue" SG_ 2566560036 MaintInfoGrp_Status21_ISig_4 7;
BA_ "GenSigMaxLatency" SG_ 2566560036 MaintInfoGrp_Status21_ISig_4 3000;
BA_ "Platform_VMCU1_Sig" SG_ 2566560036 MaintInfoGrp_Status21_ISig_4 1;
BA_ "GenSigSendType" SG_ 2566560036 MaintInfoGrp_Unit21_ISig_4 1;
BA_ "GenSigStartValue" SG_ 2566560036 MaintInfoGrp_Unit21_ISig_4 7;
BA_ "GenSigMaxLatency" SG_ 2566560036 MaintInfoGrp_Unit21_ISig_4 3000;
BA_ "Platform_VMCU1_Sig" SG_ 2566560036 MaintInfoGrp_Unit21_ISig_4 1;
BA_ "GenSigSendType" SG_ 2566560036 MaintInfoGrp_MaintOption24_ISig_ 1;
BA_ "GenSigStartValue" SG_ 2566560036 MaintInfoGrp_MaintOption24_ISig_ 15;
BA_ "GenSigMaxLatency" SG_ 2566560036 MaintInfoGrp_MaintOption24_ISig_ 3000;
BA_ "Platform_VMCU1_Sig" SG_ 2566560036 MaintInfoGrp_MaintOption24_ISig_ 1;
BA_ "SystemSignalLongSymbol" SG_ 2566560036 MaintInfoGrp_MaintOption24_ISig_ "MaintInfoGrp_MaintOption24_ISig_4";
BA_ "GenSigSendType" SG_ 2566560036 MaintInfoGrp_Data26_ISig_4 1;
BA_ "GenSigStartValue" SG_ 2566560036 MaintInfoGrp_Data26_ISig_4 4294967295;
BA_ "GenSigMaxLatency" SG_ 2566560036 MaintInfoGrp_Data26_ISig_4 3000;
BA_ "Platform_VMCU1_Sig" SG_ 2566560036 MaintInfoGrp_Data26_ISig_4 1;
BA_ "GenSigSendType" SG_ 2566560036 MaintInfoGrp_Data37_ISig_4 1;
BA_ "GenSigStartValue" SG_ 2566560036 MaintInfoGrp_Data37_ISig_4 4294967295;
BA_ "GenSigMaxLatency" SG_ 2566560036 MaintInfoGrp_Data37_ISig_4 3000;
BA_ "Platform_VMCU1_Sig" SG_ 2566560036 MaintInfoGrp_Data37_ISig_4 1;
BA_ "GenSigSendType" SG_ 2566560036 MaintInfoGrp_Data35_ISig_4 1;
BA_ "GenSigStartValue" SG_ 2566560036 MaintInfoGrp_Data35_ISig_4 4294967295;
BA_ "GenSigMaxLatency" SG_ 2566560036 MaintInfoGrp_Data35_ISig_4 3000;
BA_ "Platform_VMCU1_Sig" SG_ 2566560036 MaintInfoGrp_Data35_ISig_4 1;
BA_ "GenSigSendType" SG_ 2566560036 MaintInfoGrp_Supported17_ISig_4 1;
BA_ "GenSigStartValue" SG_ 2566560036 MaintInfoGrp_Supported17_ISig_4 3;
BA_ "GenSigMaxLatency" SG_ 2566560036 MaintInfoGrp_Supported17_ISig_4 3000;
BA_ "Platform_VMCU1_Sig" SG_ 2566560036 MaintInfoGrp_Supported17_ISig_4 1;
BA_ "GenSigSendType" SG_ 2566560036 MaintInfoGrp_ResetAuthorized17_I 1;
BA_ "GenSigStartValue" SG_ 2566560036 MaintInfoGrp_ResetAuthorized17_I 3;
BA_ "GenSigMaxLatency" SG_ 2566560036 MaintInfoGrp_ResetAuthorized17_I 3000;
BA_ "Platform_VMCU1_Sig" SG_ 2566560036 MaintInfoGrp_ResetAuthorized17_I 1;
BA_ "SystemSignalLongSymbol" SG_ 2566560036 MaintInfoGrp_ResetAuthorized17_I "MaintInfoGrp_ResetAuthorized17_ISig_4";
BA_ "GenSigSendType" SG_ 2566560036 MaintInfoGrp_Unit25_ISig_4 1;
BA_ "GenSigStartValue" SG_ 2566560036 MaintInfoGrp_Unit25_ISig_4 7;
BA_ "GenSigMaxLatency" SG_ 2566560036 MaintInfoGrp_Unit25_ISig_4 3000;
BA_ "Platform_VMCU1_Sig" SG_ 2566560036 MaintInfoGrp_Unit25_ISig_4 1;
BA_ "GenSigSendType" SG_ 2566560036 MaintInfoGrp_Unit37_ISig_4 1;
BA_ "GenSigStartValue" SG_ 2566560036 MaintInfoGrp_Unit37_ISig_4 7;
BA_ "GenSigMaxLatency" SG_ 2566560036 MaintInfoGrp_Unit37_ISig_4 3000;
BA_ "Platform_VMCU1_Sig" SG_ 2566560036 MaintInfoGrp_Unit37_ISig_4 1;
BA_ "GenSigSendType" SG_ 2566560036 MaintInfoGrp_MaintOption2_ISig_4 1;
BA_ "GenSigStartValue" SG_ 2566560036 MaintInfoGrp_MaintOption2_ISig_4 15;
BA_ "GenSigMaxLatency" SG_ 2566560036 MaintInfoGrp_MaintOption2_ISig_4 3000;
BA_ "Platform_VMCU1_Sig" SG_ 2566560036 MaintInfoGrp_MaintOption2_ISig_4 1;
BA_ "GenSigSendType" SG_ 2566560036 MaintInfoGrp_Supported21_ISig_4 1;
BA_ "GenSigStartValue" SG_ 2566560036 MaintInfoGrp_Supported21_ISig_4 3;
BA_ "GenSigMaxLatency" SG_ 2566560036 MaintInfoGrp_Supported21_ISig_4 3000;
BA_ "Platform_VMCU1_Sig" SG_ 2566560036 MaintInfoGrp_Supported21_ISig_4 1;
BA_ "GenSigSendType" SG_ 2566560036 MaintInfoGrp_ResetAuthorized16_I 1;
BA_ "GenSigStartValue" SG_ 2566560036 MaintInfoGrp_ResetAuthorized16_I 3;
BA_ "GenSigMaxLatency" SG_ 2566560036 MaintInfoGrp_ResetAuthorized16_I 3000;
BA_ "Platform_VMCU1_Sig" SG_ 2566560036 MaintInfoGrp_ResetAuthorized16_I 1;
BA_ "SystemSignalLongSymbol" SG_ 2566560036 MaintInfoGrp_ResetAuthorized16_I "MaintInfoGrp_ResetAuthorized16_ISig_4";
BA_ "GenSigSendType" SG_ 2566560036 MaintInfoGrp_Supported15_ISig_4 1;
BA_ "GenSigStartValue" SG_ 2566560036 MaintInfoGrp_Supported15_ISig_4 3;
BA_ "GenSigMaxLatency" SG_ 2566560036 MaintInfoGrp_Supported15_ISig_4 3000;
BA_ "Platform_VMCU1_Sig" SG_ 2566560036 MaintInfoGrp_Supported15_ISig_4 1;
BA_ "GenSigSendType" SG_ 2566560036 MaintInfoGrp_ResetAuthorized9_IS 1;
BA_ "GenSigStartValue" SG_ 2566560036 MaintInfoGrp_ResetAuthorized9_IS 3;
BA_ "GenSigMaxLatency" SG_ 2566560036 MaintInfoGrp_ResetAuthorized9_IS 3000;
BA_ "Platform_VMCU1_Sig" SG_ 2566560036 MaintInfoGrp_ResetAuthorized9_IS 1;
BA_ "SystemSignalLongSymbol" SG_ 2566560036 MaintInfoGrp_ResetAuthorized9_IS "MaintInfoGrp_ResetAuthorized9_ISig_4";
BA_ "GenSigSendType" SG_ 2566560036 MaintInfoGrp_MaintOption18_ISig_ 1;
BA_ "GenSigStartValue" SG_ 2566560036 MaintInfoGrp_MaintOption18_ISig_ 15;
BA_ "GenSigMaxLatency" SG_ 2566560036 MaintInfoGrp_MaintOption18_ISig_ 3000;
BA_ "Platform_VMCU1_Sig" SG_ 2566560036 MaintInfoGrp_MaintOption18_ISig_ 1;
BA_ "SystemSignalLongSymbol" SG_ 2566560036 MaintInfoGrp_MaintOption18_ISig_ "MaintInfoGrp_MaintOption18_ISig_4";
BA_ "GenSigSendType" SG_ 2566560036 MaintInfoGrp_Data14_ISig_4 1;
BA_ "GenSigStartValue" SG_ 2566560036 MaintInfoGrp_Data14_ISig_4 4294967295;
BA_ "GenSigMaxLatency" SG_ 2566560036 MaintInfoGrp_Data14_ISig_4 3000;
BA_ "Platform_VMCU1_Sig" SG_ 2566560036 MaintInfoGrp_Data14_ISig_4 1;
BA_ "GenSigSendType" SG_ 2566560036 MaintInfoGrp_Data8_ISig_4 1;
BA_ "GenSigStartValue" SG_ 2566560036 MaintInfoGrp_Data8_ISig_4 4294967295;
BA_ "GenSigMaxLatency" SG_ 2566560036 MaintInfoGrp_Data8_ISig_4 3000;
BA_ "Platform_VMCU1_Sig" SG_ 2566560036 MaintInfoGrp_Data8_ISig_4 1;
BA_ "GenSigSendType" SG_ 2566560036 MaintInfoGrp_Supported29_ISig_4 1;
BA_ "GenSigStartValue" SG_ 2566560036 MaintInfoGrp_Supported29_ISig_4 3;
BA_ "GenSigMaxLatency" SG_ 2566560036 MaintInfoGrp_Supported29_ISig_4 3000;
BA_ "Platform_VMCU1_Sig" SG_ 2566560036 MaintInfoGrp_Supported29_ISig_4 1;
BA_ "GenSigSendType" SG_ 2566560036 MaintInfoGrp_ResetAuthorized39_I 1;
BA_ "GenSigStartValue" SG_ 2566560036 MaintInfoGrp_ResetAuthorized39_I 3;
BA_ "GenSigMaxLatency" SG_ 2566560036 MaintInfoGrp_ResetAuthorized39_I 3000;
BA_ "Platform_VMCU1_Sig" SG_ 2566560036 MaintInfoGrp_ResetAuthorized39_I 1;
BA_ "SystemSignalLongSymbol" SG_ 2566560036 MaintInfoGrp_ResetAuthorized39_I "MaintInfoGrp_ResetAuthorized39_ISig_4";
BA_ "GenSigSendType" SG_ 2566560036 MaintInfoGrp_Supported32_ISig_4 1;
BA_ "GenSigStartValue" SG_ 2566560036 MaintInfoGrp_Supported32_ISig_4 3;
BA_ "GenSigMaxLatency" SG_ 2566560036 MaintInfoGrp_Supported32_ISig_4 3000;
BA_ "Platform_VMCU1_Sig" SG_ 2566560036 MaintInfoGrp_Supported32_ISig_4 1;
BA_ "GenSigSendType" SG_ 2566560036 MaintInfoGrp_Data33_ISig_4 1;
BA_ "GenSigStartValue" SG_ 2566560036 MaintInfoGrp_Data33_ISig_4 4294967295;
BA_ "GenSigMaxLatency" SG_ 2566560036 MaintInfoGrp_Data33_ISig_4 3000;
BA_ "Platform_VMCU1_Sig" SG_ 2566560036 MaintInfoGrp_Data33_ISig_4 1;
BA_ "GenSigSendType" SG_ 2566560036 MaintInfoGrp_ResetAuthorized35_I 1;
BA_ "GenSigStartValue" SG_ 2566560036 MaintInfoGrp_ResetAuthorized35_I 3;
BA_ "GenSigMaxLatency" SG_ 2566560036 MaintInfoGrp_ResetAuthorized35_I 3000;
BA_ "Platform_VMCU1_Sig" SG_ 2566560036 MaintInfoGrp_ResetAuthorized35_I 1;
BA_ "SystemSignalLongSymbol" SG_ 2566560036 MaintInfoGrp_ResetAuthorized35_I "MaintInfoGrp_ResetAuthorized35_ISig_4";
BA_ "GenSigSendType" SG_ 2566560036 MaintInfoGrp_Data30_ISig_4 1;
BA_ "GenSigStartValue" SG_ 2566560036 MaintInfoGrp_Data30_ISig_4 4294967295;
BA_ "GenSigMaxLatency" SG_ 2566560036 MaintInfoGrp_Data30_ISig_4 3000;
BA_ "Platform_VMCU1_Sig" SG_ 2566560036 MaintInfoGrp_Data30_ISig_4 1;
BA_ "GenSigSendType" SG_ 2566560036 MaintInfoGrp_ResetAuthorized29_I 1;
BA_ "GenSigStartValue" SG_ 2566560036 MaintInfoGrp_ResetAuthorized29_I 3;
BA_ "GenSigMaxLatency" SG_ 2566560036 MaintInfoGrp_ResetAuthorized29_I 3000;
BA_ "Platform_VMCU1_Sig" SG_ 2566560036 MaintInfoGrp_ResetAuthorized29_I 1;
BA_ "SystemSignalLongSymbol" SG_ 2566560036 MaintInfoGrp_ResetAuthorized29_I "MaintInfoGrp_ResetAuthorized29_ISig_4";
BA_ "GenSigSendType" SG_ 2566560036 MaintInfoGrp_Supported35_ISig_4 1;
BA_ "GenSigStartValue" SG_ 2566560036 MaintInfoGrp_Supported35_ISig_4 3;
BA_ "GenSigMaxLatency" SG_ 2566560036 MaintInfoGrp_Supported35_ISig_4 3000;
BA_ "Platform_VMCU1_Sig" SG_ 2566560036 MaintInfoGrp_Supported35_ISig_4 1;
BA_ "GenSigSendType" SG_ 2566560036 MaintInfoGrp_ResetAuthorized4_IS 1;
BA_ "GenSigStartValue" SG_ 2566560036 MaintInfoGrp_ResetAuthorized4_IS 3;
BA_ "GenSigMaxLatency" SG_ 2566560036 MaintInfoGrp_ResetAuthorized4_IS 3000;
BA_ "Platform_VMCU1_Sig" SG_ 2566560036 MaintInfoGrp_ResetAuthorized4_IS 1;
BA_ "SystemSignalLongSymbol" SG_ 2566560036 MaintInfoGrp_ResetAuthorized4_IS "MaintInfoGrp_ResetAuthorized4_ISig_4";
BA_ "GenSigSendType" SG_ 2566560036 MaintInfoGrp_Data10_ISig_4 1;
BA_ "GenSigStartValue" SG_ 2566560036 MaintInfoGrp_Data10_ISig_4 4294967295;
BA_ "GenSigMaxLatency" SG_ 2566560036 MaintInfoGrp_Data10_ISig_4 3000;
BA_ "Platform_VMCU1_Sig" SG_ 2566560036 MaintInfoGrp_Data10_ISig_4 1;
BA_ "GenSigSendType" SG_ 2566560036 MaintInfoGrp_Data9_ISig_4 1;
BA_ "GenSigStartValue" SG_ 2566560036 MaintInfoGrp_Data9_ISig_4 4294967295;
BA_ "GenSigMaxLatency" SG_ 2566560036 MaintInfoGrp_Data9_ISig_4 3000;
BA_ "Platform_VMCU1_Sig" SG_ 2566560036 MaintInfoGrp_Data9_ISig_4 1;
BA_ "GenSigSendType" SG_ 2566560036 MaintInfoGrp_Unit1_ISig_4 1;
BA_ "GenSigStartValue" SG_ 2566560036 MaintInfoGrp_Unit1_ISig_4 7;
BA_ "GenSigMaxLatency" SG_ 2566560036 MaintInfoGrp_Unit1_ISig_4 3000;
BA_ "Platform_VMCU1_Sig" SG_ 2566560036 MaintInfoGrp_Unit1_ISig_4 1;
BA_ "GenSigSendType" SG_ 2566560036 MaintInfoGrp_MaintOption7_ISig_4 1;
BA_ "GenSigStartValue" SG_ 2566560036 MaintInfoGrp_MaintOption7_ISig_4 15;
BA_ "GenSigMaxLatency" SG_ 2566560036 MaintInfoGrp_MaintOption7_ISig_4 3000;
BA_ "Platform_VMCU1_Sig" SG_ 2566560036 MaintInfoGrp_MaintOption7_ISig_4 1;
BA_ "GenSigSendType" SG_ 2566560036 MaintInfoGrp_Supported24_ISig_4 1;
BA_ "GenSigStartValue" SG_ 2566560036 MaintInfoGrp_Supported24_ISig_4 3;
BA_ "GenSigMaxLatency" SG_ 2566560036 MaintInfoGrp_Supported24_ISig_4 3000;
BA_ "Platform_VMCU1_Sig" SG_ 2566560036 MaintInfoGrp_Supported24_ISig_4 1;
BA_ "GenSigSendType" SG_ 2566560036 MaintInfoGrp_Supported25_ISig_4 1;
BA_ "GenSigStartValue" SG_ 2566560036 MaintInfoGrp_Supported25_ISig_4 3;
BA_ "GenSigMaxLatency" SG_ 2566560036 MaintInfoGrp_Supported25_ISig_4 3000;
BA_ "Platform_VMCU1_Sig" SG_ 2566560036 MaintInfoGrp_Supported25_ISig_4 1;
BA_ "GenSigSendType" SG_ 2566560036 MaintInfoGrp_Unit15_ISig_4 1;
BA_ "GenSigStartValue" SG_ 2566560036 MaintInfoGrp_Unit15_ISig_4 7;
BA_ "GenSigMaxLatency" SG_ 2566560036 MaintInfoGrp_Unit15_ISig_4 3000;
BA_ "Platform_VMCU1_Sig" SG_ 2566560036 MaintInfoGrp_Unit15_ISig_4 1;
BA_ "GenSigSendType" SG_ 2566560036 MaintInfoGrp_Supported1_ISig_4 1;
BA_ "GenSigStartValue" SG_ 2566560036 MaintInfoGrp_Supported1_ISig_4 3;
BA_ "GenSigMaxLatency" SG_ 2566560036 MaintInfoGrp_Supported1_ISig_4 3000;
BA_ "Platform_VMCU1_Sig" SG_ 2566560036 MaintInfoGrp_Supported1_ISig_4 1;
BA_ "GenSigSendType" SG_ 2566560036 MaintInfoGrp_ResetAuthorized11_I 1;
BA_ "GenSigStartValue" SG_ 2566560036 MaintInfoGrp_ResetAuthorized11_I 3;
BA_ "GenSigMaxLatency" SG_ 2566560036 MaintInfoGrp_ResetAuthorized11_I 3000;
BA_ "Platform_VMCU1_Sig" SG_ 2566560036 MaintInfoGrp_ResetAuthorized11_I 1;
BA_ "SystemSignalLongSymbol" SG_ 2566560036 MaintInfoGrp_ResetAuthorized11_I "MaintInfoGrp_ResetAuthorized11_ISig_4";
BA_ "GenSigSendType" SG_ 2566560036 MaintInfoGrp_Supported13_ISig_4 1;
BA_ "GenSigStartValue" SG_ 2566560036 MaintInfoGrp_Supported13_ISig_4 3;
BA_ "GenSigMaxLatency" SG_ 2566560036 MaintInfoGrp_Supported13_ISig_4 3000;
BA_ "Platform_VMCU1_Sig" SG_ 2566560036 MaintInfoGrp_Supported13_ISig_4 1;
BA_ "GenSigSendType" SG_ 2566560036 MaintInfoGrp_Supported10_ISig_4 1;
BA_ "GenSigStartValue" SG_ 2566560036 MaintInfoGrp_Supported10_ISig_4 3;
BA_ "GenSigMaxLatency" SG_ 2566560036 MaintInfoGrp_Supported10_ISig_4 3000;
BA_ "Platform_VMCU1_Sig" SG_ 2566560036 MaintInfoGrp_Supported10_ISig_4 1;
BA_ "GenSigSendType" SG_ 2566560036 MaintInfoGrp_Data2_ISig_4 1;
BA_ "GenSigStartValue" SG_ 2566560036 MaintInfoGrp_Data2_ISig_4 4294967295;
BA_ "GenSigMaxLatency" SG_ 2566560036 MaintInfoGrp_Data2_ISig_4 3000;
BA_ "Platform_VMCU1_Sig" SG_ 2566560036 MaintInfoGrp_Data2_ISig_4 1;
BA_ "GenSigSendType" SG_ 2566560036 MaintInfoGrp_Unit16_ISig_4 1;
BA_ "GenSigStartValue" SG_ 2566560036 MaintInfoGrp_Unit16_ISig_4 7;
BA_ "GenSigMaxLatency" SG_ 2566560036 MaintInfoGrp_Unit16_ISig_4 3000;
BA_ "Platform_VMCU1_Sig" SG_ 2566560036 MaintInfoGrp_Unit16_ISig_4 1;
BA_ "GenSigSendType" SG_ 2566560036 MaintInfoGrp_MaintOption35_ISig_ 1;
BA_ "GenSigStartValue" SG_ 2566560036 MaintInfoGrp_MaintOption35_ISig_ 15;
BA_ "GenSigMaxLatency" SG_ 2566560036 MaintInfoGrp_MaintOption35_ISig_ 3000;
BA_ "Platform_VMCU1_Sig" SG_ 2566560036 MaintInfoGrp_MaintOption35_ISig_ 1;
BA_ "SystemSignalLongSymbol" SG_ 2566560036 MaintInfoGrp_MaintOption35_ISig_ "MaintInfoGrp_MaintOption35_ISig_4";
BA_ "GenSigSendType" SG_ 2566560036 MaintInfoGrp_MaintOption22_ISig_ 1;
BA_ "GenSigStartValue" SG_ 2566560036 MaintInfoGrp_MaintOption22_ISig_ 15;
BA_ "GenSigMaxLatency" SG_ 2566560036 MaintInfoGrp_MaintOption22_ISig_ 3000;
BA_ "Platform_VMCU1_Sig" SG_ 2566560036 MaintInfoGrp_MaintOption22_ISig_ 1;
BA_ "SystemSignalLongSymbol" SG_ 2566560036 MaintInfoGrp_MaintOption22_ISig_ "MaintInfoGrp_MaintOption22_ISig_4";
BA_ "GenSigSendType" SG_ 2566560036 MaintInfoGrp_MaintOption12_ISig_ 1;
BA_ "GenSigStartValue" SG_ 2566560036 MaintInfoGrp_MaintOption12_ISig_ 15;
BA_ "GenSigMaxLatency" SG_ 2566560036 MaintInfoGrp_MaintOption12_ISig_ 3000;
BA_ "Platform_VMCU1_Sig" SG_ 2566560036 MaintInfoGrp_MaintOption12_ISig_ 1;
BA_ "SystemSignalLongSymbol" SG_ 2566560036 MaintInfoGrp_MaintOption12_ISig_ "MaintInfoGrp_MaintOption12_ISig_4";
BA_ "GenSigSendType" SG_ 2566560036 MaintInfoGrp_Supported9_ISig_4 1;
BA_ "GenSigStartValue" SG_ 2566560036 MaintInfoGrp_Supported9_ISig_4 3;
BA_ "GenSigMaxLatency" SG_ 2566560036 MaintInfoGrp_Supported9_ISig_4 3000;
BA_ "Platform_VMCU1_Sig" SG_ 2566560036 MaintInfoGrp_Supported9_ISig_4 1;
BA_ "GenSigSendType" SG_ 2566560036 MaintInfoGrp_Supported31_ISig_4 1;
BA_ "GenSigStartValue" SG_ 2566560036 MaintInfoGrp_Supported31_ISig_4 3;
BA_ "GenSigMaxLatency" SG_ 2566560036 MaintInfoGrp_Supported31_ISig_4 3000;
BA_ "Platform_VMCU1_Sig" SG_ 2566560036 MaintInfoGrp_Supported31_ISig_4 1;
BA_ "GenSigSendType" SG_ 2566560036 MaintInfoGrp_MaintOption37_ISig_ 1;
BA_ "GenSigStartValue" SG_ 2566560036 MaintInfoGrp_MaintOption37_ISig_ 15;
BA_ "GenSigMaxLatency" SG_ 2566560036 MaintInfoGrp_MaintOption37_ISig_ 3000;
BA_ "Platform_VMCU1_Sig" SG_ 2566560036 MaintInfoGrp_MaintOption37_ISig_ 1;
BA_ "SystemSignalLongSymbol" SG_ 2566560036 MaintInfoGrp_MaintOption37_ISig_ "MaintInfoGrp_MaintOption37_ISig_4";
BA_ "GenSigSendType" SG_ 2566560036 MaintInfoGrp_MaintOption13_ISig_ 1;
BA_ "GenSigStartValue" SG_ 2566560036 MaintInfoGrp_MaintOption13_ISig_ 15;
BA_ "GenSigMaxLatency" SG_ 2566560036 MaintInfoGrp_MaintOption13_ISig_ 3000;
BA_ "Platform_VMCU1_Sig" SG_ 2566560036 MaintInfoGrp_MaintOption13_ISig_ 1;
BA_ "SystemSignalLongSymbol" SG_ 2566560036 MaintInfoGrp_MaintOption13_ISig_ "MaintInfoGrp_MaintOption13_ISig_4";
BA_ "GenSigSendType" SG_ 2566560036 MaintInfoGrp_ResetAuthorized22_I 1;
BA_ "GenSigStartValue" SG_ 2566560036 MaintInfoGrp_ResetAuthorized22_I 3;
BA_ "GenSigMaxLatency" SG_ 2566560036 MaintInfoGrp_ResetAuthorized22_I 3000;
BA_ "Platform_VMCU1_Sig" SG_ 2566560036 MaintInfoGrp_ResetAuthorized22_I 1;
BA_ "SystemSignalLongSymbol" SG_ 2566560036 MaintInfoGrp_ResetAuthorized22_I "MaintInfoGrp_ResetAuthorized22_ISig_4";
BA_ "GenSigSendType" SG_ 2566560036 MaintInfoGrp_Status14_ISig_4 1;
BA_ "GenSigStartValue" SG_ 2566560036 MaintInfoGrp_Status14_ISig_4 7;
BA_ "GenSigMaxLatency" SG_ 2566560036 MaintInfoGrp_Status14_ISig_4 3000;
BA_ "Platform_VMCU1_Sig" SG_ 2566560036 MaintInfoGrp_Status14_ISig_4 1;
BA_ "GenSigSendType" SG_ 2566560036 MaintInfoGrp_Status18_ISig_4 1;
BA_ "GenSigStartValue" SG_ 2566560036 MaintInfoGrp_Status18_ISig_4 7;
BA_ "GenSigMaxLatency" SG_ 2566560036 MaintInfoGrp_Status18_ISig_4 3000;
BA_ "Platform_VMCU1_Sig" SG_ 2566560036 MaintInfoGrp_Status18_ISig_4 1;
BA_ "GenSigSendType" SG_ 2566560036 MaintInfoGrp_Unit17_ISig_4 1;
BA_ "GenSigStartValue" SG_ 2566560036 MaintInfoGrp_Unit17_ISig_4 7;
BA_ "GenSigMaxLatency" SG_ 2566560036 MaintInfoGrp_Unit17_ISig_4 3000;
BA_ "Platform_VMCU1_Sig" SG_ 2566560036 MaintInfoGrp_Unit17_ISig_4 1;
BA_ "GenSigSendType" SG_ 2566560036 MaintInfoGrp_Unit12_ISig_4 1;
BA_ "GenSigStartValue" SG_ 2566560036 MaintInfoGrp_Unit12_ISig_4 7;
BA_ "GenSigMaxLatency" SG_ 2566560036 MaintInfoGrp_Unit12_ISig_4 3000;
BA_ "Platform_VMCU1_Sig" SG_ 2566560036 MaintInfoGrp_Unit12_ISig_4 1;
BA_ "GenSigSendType" SG_ 2566560036 MaintInfoGrp_Data22_ISig_4 1;
BA_ "GenSigStartValue" SG_ 2566560036 MaintInfoGrp_Data22_ISig_4 4294967295;
BA_ "GenSigMaxLatency" SG_ 2566560036 MaintInfoGrp_Data22_ISig_4 3000;
BA_ "Platform_VMCU1_Sig" SG_ 2566560036 MaintInfoGrp_Data22_ISig_4 1;
BA_ "GenSigSendType" SG_ 2566560036 MaintInfoGrp_Supported27_ISig_4 1;
BA_ "GenSigStartValue" SG_ 2566560036 MaintInfoGrp_Supported27_ISig_4 3;
BA_ "GenSigMaxLatency" SG_ 2566560036 MaintInfoGrp_Supported27_ISig_4 3000;
BA_ "Platform_VMCU1_Sig" SG_ 2566560036 MaintInfoGrp_Supported27_ISig_4 1;
BA_ "GenSigSendType" SG_ 2566560036 MaintInfoGrp_Unit4_ISig_4 1;
BA_ "GenSigStartValue" SG_ 2566560036 MaintInfoGrp_Unit4_ISig_4 7;
BA_ "GenSigMaxLatency" SG_ 2566560036 MaintInfoGrp_Unit4_ISig_4 3000;
BA_ "Platform_VMCU1_Sig" SG_ 2566560036 MaintInfoGrp_Unit4_ISig_4 1;
BA_ "GenSigSendType" SG_ 2566560036 MaintInfoGrp_Data13_ISig_4 1;
BA_ "GenSigStartValue" SG_ 2566560036 MaintInfoGrp_Data13_ISig_4 4294967295;
BA_ "GenSigMaxLatency" SG_ 2566560036 MaintInfoGrp_Data13_ISig_4 3000;
BA_ "Platform_VMCU1_Sig" SG_ 2566560036 MaintInfoGrp_Data13_ISig_4 1;
BA_ "GenSigSendType" SG_ 2566560036 MaintInfoGrp_Status27_ISig_4 1;
BA_ "GenSigStartValue" SG_ 2566560036 MaintInfoGrp_Status27_ISig_4 7;
BA_ "GenSigMaxLatency" SG_ 2566560036 MaintInfoGrp_Status27_ISig_4 3000;
BA_ "Platform_VMCU1_Sig" SG_ 2566560036 MaintInfoGrp_Status27_ISig_4 1;
BA_ "GenSigSendType" SG_ 2566560036 MaintInfoGrp_MaintOption29_ISig_ 1;
BA_ "GenSigStartValue" SG_ 2566560036 MaintInfoGrp_MaintOption29_ISig_ 15;
BA_ "GenSigMaxLatency" SG_ 2566560036 MaintInfoGrp_MaintOption29_ISig_ 3000;
BA_ "Platform_VMCU1_Sig" SG_ 2566560036 MaintInfoGrp_MaintOption29_ISig_ 1;
BA_ "SystemSignalLongSymbol" SG_ 2566560036 MaintInfoGrp_MaintOption29_ISig_ "MaintInfoGrp_MaintOption29_ISig_4";
BA_ "GenSigSendType" SG_ 2566560036 MaintInfoGrp_Unit9_ISig_4 1;
BA_ "GenSigStartValue" SG_ 2566560036 MaintInfoGrp_Unit9_ISig_4 7;
BA_ "GenSigMaxLatency" SG_ 2566560036 MaintInfoGrp_Unit9_ISig_4 3000;
BA_ "Platform_VMCU1_Sig" SG_ 2566560036 MaintInfoGrp_Unit9_ISig_4 1;
BA_ "GenSigSendType" SG_ 2566560036 MaintInfoGrp_Unit13_ISig_4 1;
BA_ "GenSigStartValue" SG_ 2566560036 MaintInfoGrp_Unit13_ISig_4 7;
BA_ "GenSigMaxLatency" SG_ 2566560036 MaintInfoGrp_Unit13_ISig_4 3000;
BA_ "Platform_VMCU1_Sig" SG_ 2566560036 MaintInfoGrp_Unit13_ISig_4 1;
BA_ "GenSigSendType" SG_ 2566560036 MaintInfoGrp_Data25_ISig_4 1;
BA_ "GenSigStartValue" SG_ 2566560036 MaintInfoGrp_Data25_ISig_4 4294967295;
BA_ "GenSigMaxLatency" SG_ 2566560036 MaintInfoGrp_Data25_ISig_4 3000;
BA_ "Platform_VMCU1_Sig" SG_ 2566560036 MaintInfoGrp_Data25_ISig_4 1;
BA_ "GenSigSendType" SG_ 2566560036 MaintInfoGrp_Unit3_ISig_4 1;
BA_ "GenSigStartValue" SG_ 2566560036 MaintInfoGrp_Unit3_ISig_4 7;
BA_ "GenSigMaxLatency" SG_ 2566560036 MaintInfoGrp_Unit3_ISig_4 3000;
BA_ "Platform_VMCU1_Sig" SG_ 2566560036 MaintInfoGrp_Unit3_ISig_4 1;
BA_ "GenSigSendType" SG_ 2566560036 MaintInfoGrp_MaintOption15_ISig_ 1;
BA_ "GenSigStartValue" SG_ 2566560036 MaintInfoGrp_MaintOption15_ISig_ 15;
BA_ "GenSigMaxLatency" SG_ 2566560036 MaintInfoGrp_MaintOption15_ISig_ 3000;
BA_ "Platform_VMCU1_Sig" SG_ 2566560036 MaintInfoGrp_MaintOption15_ISig_ 1;
BA_ "SystemSignalLongSymbol" SG_ 2566560036 MaintInfoGrp_MaintOption15_ISig_ "MaintInfoGrp_MaintOption15_ISig_4";
BA_ "GenSigSendType" SG_ 2566560036 MaintInfoGrp_ResetAuthorized15_I 1;
BA_ "GenSigStartValue" SG_ 2566560036 MaintInfoGrp_ResetAuthorized15_I 3;
BA_ "GenSigMaxLatency" SG_ 2566560036 MaintInfoGrp_ResetAuthorized15_I 3000;
BA_ "Platform_VMCU1_Sig" SG_ 2566560036 MaintInfoGrp_ResetAuthorized15_I 1;
BA_ "SystemSignalLongSymbol" SG_ 2566560036 MaintInfoGrp_ResetAuthorized15_I "MaintInfoGrp_ResetAuthorized15_ISig_4";
BA_ "GenSigSendType" SG_ 2566560036 MaintInfoGrp_MaintOption11_ISig_ 1;
BA_ "GenSigStartValue" SG_ 2566560036 MaintInfoGrp_MaintOption11_ISig_ 15;
BA_ "GenSigMaxLatency" SG_ 2566560036 MaintInfoGrp_MaintOption11_ISig_ 3000;
BA_ "Platform_VMCU1_Sig" SG_ 2566560036 MaintInfoGrp_MaintOption11_ISig_ 1;
BA_ "SystemSignalLongSymbol" SG_ 2566560036 MaintInfoGrp_MaintOption11_ISig_ "MaintInfoGrp_MaintOption11_ISig_4";
BA_ "GenSigSendType" SG_ 2566560036 MaintInfoGrp_MaintOption25_ISig_ 1;
BA_ "GenSigStartValue" SG_ 2566560036 MaintInfoGrp_MaintOption25_ISig_ 15;
BA_ "GenSigMaxLatency" SG_ 2566560036 MaintInfoGrp_MaintOption25_ISig_ 3000;
BA_ "Platform_VMCU1_Sig" SG_ 2566560036 MaintInfoGrp_MaintOption25_ISig_ 1;
BA_ "SystemSignalLongSymbol" SG_ 2566560036 MaintInfoGrp_MaintOption25_ISig_ "MaintInfoGrp_MaintOption25_ISig_4";
BA_ "GenSigSendType" SG_ 2566560036 MaintInfoGrp_Supported16_ISig_4 1;
BA_ "GenSigStartValue" SG_ 2566560036 MaintInfoGrp_Supported16_ISig_4 3;
BA_ "GenSigMaxLatency" SG_ 2566560036 MaintInfoGrp_Supported16_ISig_4 3000;
BA_ "Platform_VMCU1_Sig" SG_ 2566560036 MaintInfoGrp_Supported16_ISig_4 1;
BA_ "GenSigSendType" SG_ 2566560036 MaintInfoGrp_Supported23_ISig_4 1;
BA_ "GenSigStartValue" SG_ 2566560036 MaintInfoGrp_Supported23_ISig_4 3;
BA_ "GenSigMaxLatency" SG_ 2566560036 MaintInfoGrp_Supported23_ISig_4 3000;
BA_ "Platform_VMCU1_Sig" SG_ 2566560036 MaintInfoGrp_Supported23_ISig_4 1;
BA_ "GenSigSendType" SG_ 2566560036 MaintInfoGrp_Status13_ISig_4 1;
BA_ "GenSigStartValue" SG_ 2566560036 MaintInfoGrp_Status13_ISig_4 7;
BA_ "GenSigMaxLatency" SG_ 2566560036 MaintInfoGrp_Status13_ISig_4 3000;
BA_ "Platform_VMCU1_Sig" SG_ 2566560036 MaintInfoGrp_Status13_ISig_4 1;
BA_ "GenSigSendType" SG_ 2566560036 MaintInfoGrp_Status17_ISig_4 1;
BA_ "GenSigStartValue" SG_ 2566560036 MaintInfoGrp_Status17_ISig_4 7;
BA_ "GenSigMaxLatency" SG_ 2566560036 MaintInfoGrp_Status17_ISig_4 3000;
BA_ "Platform_VMCU1_Sig" SG_ 2566560036 MaintInfoGrp_Status17_ISig_4 1;
BA_ "GenSigSendType" SG_ 2566560036 MaintInfoGrp_Unit8_ISig_4 1;
BA_ "GenSigStartValue" SG_ 2566560036 MaintInfoGrp_Unit8_ISig_4 7;
BA_ "GenSigMaxLatency" SG_ 2566560036 MaintInfoGrp_Unit8_ISig_4 3000;
BA_ "Platform_VMCU1_Sig" SG_ 2566560036 MaintInfoGrp_Unit8_ISig_4 1;
BA_ "GenSigSendType" SG_ 2566560036 MaintInfoGrp_MaintOption38_ISig_ 1;
BA_ "GenSigStartValue" SG_ 2566560036 MaintInfoGrp_MaintOption38_ISig_ 15;
BA_ "GenSigMaxLatency" SG_ 2566560036 MaintInfoGrp_MaintOption38_ISig_ 3000;
BA_ "Platform_VMCU1_Sig" SG_ 2566560036 MaintInfoGrp_MaintOption38_ISig_ 1;
BA_ "SystemSignalLongSymbol" SG_ 2566560036 MaintInfoGrp_MaintOption38_ISig_ "MaintInfoGrp_MaintOption38_ISig_4";
BA_ "GenSigSendType" SG_ 2566560036 MaintInfoGrp_Data4_ISig_4 1;
BA_ "GenSigStartValue" SG_ 2566560036 MaintInfoGrp_Data4_ISig_4 4294967295;
BA_ "GenSigMaxLatency" SG_ 2566560036 MaintInfoGrp_Data4_ISig_4 3000;
BA_ "Platform_VMCU1_Sig" SG_ 2566560036 MaintInfoGrp_Data4_ISig_4 1;
BA_ "GenSigSendType" SG_ 2566560036 MaintInfoGrp_Supported2_ISig_4 1;
BA_ "GenSigStartValue" SG_ 2566560036 MaintInfoGrp_Supported2_ISig_4 3;
BA_ "GenSigMaxLatency" SG_ 2566560036 MaintInfoGrp_Supported2_ISig_4 3000;
BA_ "Platform_VMCU1_Sig" SG_ 2566560036 MaintInfoGrp_Supported2_ISig_4 1;
BA_ "GenSigSendType" SG_ 2566560036 MaintInfoGrp_ResetAuthorized0_IS 1;
BA_ "GenSigStartValue" SG_ 2566560036 MaintInfoGrp_ResetAuthorized0_IS 3;
BA_ "GenSigMaxLatency" SG_ 2566560036 MaintInfoGrp_ResetAuthorized0_IS 3000;
BA_ "Platform_VMCU1_Sig" SG_ 2566560036 MaintInfoGrp_ResetAuthorized0_IS 1;
BA_ "SystemSignalLongSymbol" SG_ 2566560036 MaintInfoGrp_ResetAuthorized0_IS "MaintInfoGrp_ResetAuthorized0_ISig_4";
BA_ "GenSigSendType" SG_ 2566560036 MaintInfoGrp_Supported5_ISig_4 1;
BA_ "GenSigStartValue" SG_ 2566560036 MaintInfoGrp_Supported5_ISig_4 3;
BA_ "GenSigMaxLatency" SG_ 2566560036 MaintInfoGrp_Supported5_ISig_4 3000;
BA_ "Platform_VMCU1_Sig" SG_ 2566560036 MaintInfoGrp_Supported5_ISig_4 1;
BA_ "GenSigSendType" SG_ 2566560036 MaintInfoGrp_Status6_ISig_4 1;
BA_ "GenSigStartValue" SG_ 2566560036 MaintInfoGrp_Status6_ISig_4 7;
BA_ "GenSigMaxLatency" SG_ 2566560036 MaintInfoGrp_Status6_ISig_4 3000;
BA_ "Platform_VMCU1_Sig" SG_ 2566560036 MaintInfoGrp_Status6_ISig_4 1;
BA_ "GenSigSendType" SG_ 2566560036 MaintInfoGrp_Unit5_ISig_4 1;
BA_ "GenSigStartValue" SG_ 2566560036 MaintInfoGrp_Unit5_ISig_4 7;
BA_ "GenSigMaxLatency" SG_ 2566560036 MaintInfoGrp_Unit5_ISig_4 3000;
BA_ "Platform_VMCU1_Sig" SG_ 2566560036 MaintInfoGrp_Unit5_ISig_4 1;
BA_ "GenSigSendType" SG_ 2566560036 MaintInfoGrp_Data0_ISig_4 1;
BA_ "GenSigStartValue" SG_ 2566560036 MaintInfoGrp_Data0_ISig_4 4294967295;
BA_ "GenSigMaxLatency" SG_ 2566560036 MaintInfoGrp_Data0_ISig_4 3000;
BA_ "Platform_VMCU1_Sig" SG_ 2566560036 MaintInfoGrp_Data0_ISig_4 1;
BA_ "GenSigSendType" SG_ 2566560036 MaintInfoGrp_Data29_ISig_4 1;
BA_ "GenSigStartValue" SG_ 2566560036 MaintInfoGrp_Data29_ISig_4 4294967295;
BA_ "GenSigMaxLatency" SG_ 2566560036 MaintInfoGrp_Data29_ISig_4 3000;
BA_ "Platform_VMCU1_Sig" SG_ 2566560036 MaintInfoGrp_Data29_ISig_4 1;
BA_ "GenSigSendType" SG_ 2566560036 MaintInfoGrp_Supported28_ISig_4 1;
BA_ "GenSigStartValue" SG_ 2566560036 MaintInfoGrp_Supported28_ISig_4 3;
BA_ "GenSigMaxLatency" SG_ 2566560036 MaintInfoGrp_Supported28_ISig_4 3000;
BA_ "Platform_VMCU1_Sig" SG_ 2566560036 MaintInfoGrp_Supported28_ISig_4 1;
BA_ "GenSigSendType" SG_ 2566560036 MaintInfoGrp_Status32_ISig_4 1;
BA_ "GenSigStartValue" SG_ 2566560036 MaintInfoGrp_Status32_ISig_4 7;
BA_ "GenSigMaxLatency" SG_ 2566560036 MaintInfoGrp_Status32_ISig_4 3000;
BA_ "Platform_VMCU1_Sig" SG_ 2566560036 MaintInfoGrp_Status32_ISig_4 1;
BA_ "GenSigSendType" SG_ 2566560036 MaintInfoGrp_MaintOption0_ISig_4 1;
BA_ "GenSigStartValue" SG_ 2566560036 MaintInfoGrp_MaintOption0_ISig_4 15;
BA_ "GenSigMaxLatency" SG_ 2566560036 MaintInfoGrp_MaintOption0_ISig_4 3000;
BA_ "Platform_VMCU1_Sig" SG_ 2566560036 MaintInfoGrp_MaintOption0_ISig_4 1;
BA_ "GenSigSendType" SG_ 2566560036 MaintInfoGrp_ResetAuthorized25_I 1;
BA_ "GenSigStartValue" SG_ 2566560036 MaintInfoGrp_ResetAuthorized25_I 3;
BA_ "GenSigMaxLatency" SG_ 2566560036 MaintInfoGrp_ResetAuthorized25_I 3000;
BA_ "Platform_VMCU1_Sig" SG_ 2566560036 MaintInfoGrp_ResetAuthorized25_I 1;
BA_ "SystemSignalLongSymbol" SG_ 2566560036 MaintInfoGrp_ResetAuthorized25_I "MaintInfoGrp_ResetAuthorized25_ISig_4";
BA_ "GenSigSendType" SG_ 2566560036 MaintInfoGrp_MaintOption32_ISig_ 1;
BA_ "GenSigStartValue" SG_ 2566560036 MaintInfoGrp_MaintOption32_ISig_ 15;
BA_ "GenSigMaxLatency" SG_ 2566560036 MaintInfoGrp_MaintOption32_ISig_ 3000;
BA_ "Platform_VMCU1_Sig" SG_ 2566560036 MaintInfoGrp_MaintOption32_ISig_ 1;
BA_ "SystemSignalLongSymbol" SG_ 2566560036 MaintInfoGrp_MaintOption32_ISig_ "MaintInfoGrp_MaintOption32_ISig_4";
BA_ "GenSigSendType" SG_ 2566560036 MaintInfoGrp_Unit11_ISig_4 1;
BA_ "GenSigStartValue" SG_ 2566560036 MaintInfoGrp_Unit11_ISig_4 7;
BA_ "GenSigMaxLatency" SG_ 2566560036 MaintInfoGrp_Unit11_ISig_4 3000;
BA_ "Platform_VMCU1_Sig" SG_ 2566560036 MaintInfoGrp_Unit11_ISig_4 1;
BA_ "GenSigSendType" SG_ 2566560036 MaintInfoGrp_Data39_ISig_4 1;
BA_ "GenSigStartValue" SG_ 2566560036 MaintInfoGrp_Data39_ISig_4 4294967295;
BA_ "GenSigMaxLatency" SG_ 2566560036 MaintInfoGrp_Data39_ISig_4 3000;
BA_ "Platform_VMCU1_Sig" SG_ 2566560036 MaintInfoGrp_Data39_ISig_4 1;
BA_ "GenSigSendType" SG_ 2566560036 MaintInfoGrp_MaintOption4_ISig_4 1;
BA_ "GenSigStartValue" SG_ 2566560036 MaintInfoGrp_MaintOption4_ISig_4 15;
BA_ "GenSigMaxLatency" SG_ 2566560036 MaintInfoGrp_MaintOption4_ISig_4 3000;
BA_ "Platform_VMCU1_Sig" SG_ 2566560036 MaintInfoGrp_MaintOption4_ISig_4 1;
BA_ "GenSigSendType" SG_ 2566560036 MaintInfoGrp_Supported38_ISig_4 1;
BA_ "GenSigStartValue" SG_ 2566560036 MaintInfoGrp_Supported38_ISig_4 3;
BA_ "GenSigMaxLatency" SG_ 2566560036 MaintInfoGrp_Supported38_ISig_4 3000;
BA_ "Platform_VMCU1_Sig" SG_ 2566560036 MaintInfoGrp_Supported38_ISig_4 1;
BA_ "GenSigSendType" SG_ 2566560036 MaintInfoGrp_MaintOption1_ISig_4 1;
BA_ "GenSigStartValue" SG_ 2566560036 MaintInfoGrp_MaintOption1_ISig_4 15;
BA_ "GenSigMaxLatency" SG_ 2566560036 MaintInfoGrp_MaintOption1_ISig_4 3000;
BA_ "Platform_VMCU1_Sig" SG_ 2566560036 MaintInfoGrp_MaintOption1_ISig_4 1;
BA_ "GenSigSendType" SG_ 2566560036 MaintInfoGrp_Supported30_ISig_4 1;
BA_ "GenSigStartValue" SG_ 2566560036 MaintInfoGrp_Supported30_ISig_4 3;
BA_ "GenSigMaxLatency" SG_ 2566560036 MaintInfoGrp_Supported30_ISig_4 3000;
BA_ "Platform_VMCU1_Sig" SG_ 2566560036 MaintInfoGrp_Supported30_ISig_4 1;
BA_ "GenSigSendType" SG_ 2566560036 MaintInfoGrp_ResetAuthorized33_I 1;
BA_ "GenSigStartValue" SG_ 2566560036 MaintInfoGrp_ResetAuthorized33_I 3;
BA_ "GenSigMaxLatency" SG_ 2566560036 MaintInfoGrp_ResetAuthorized33_I 3000;
BA_ "Platform_VMCU1_Sig" SG_ 2566560036 MaintInfoGrp_ResetAuthorized33_I 1;
BA_ "SystemSignalLongSymbol" SG_ 2566560036 MaintInfoGrp_ResetAuthorized33_I "MaintInfoGrp_ResetAuthorized33_ISig_4";
BA_ "GenSigSendType" SG_ 2566560036 MaintInfoGrp_Status0_ISig_4 1;
BA_ "GenSigStartValue" SG_ 2566560036 MaintInfoGrp_Status0_ISig_4 7;
BA_ "GenSigMaxLatency" SG_ 2566560036 MaintInfoGrp_Status0_ISig_4 3000;
BA_ "Platform_VMCU1_Sig" SG_ 2566560036 MaintInfoGrp_Status0_ISig_4 1;
BA_ "GenSigSendType" SG_ 2566560036 MaintInfoGrp_ResetAuthorized20_I 1;
BA_ "GenSigStartValue" SG_ 2566560036 MaintInfoGrp_ResetAuthorized20_I 3;
BA_ "GenSigMaxLatency" SG_ 2566560036 MaintInfoGrp_ResetAuthorized20_I 3000;
BA_ "Platform_VMCU1_Sig" SG_ 2566560036 MaintInfoGrp_ResetAuthorized20_I 1;
BA_ "SystemSignalLongSymbol" SG_ 2566560036 MaintInfoGrp_ResetAuthorized20_I "MaintInfoGrp_ResetAuthorized20_ISig_4";
BA_ "GenSigSendType" SG_ 2566560036 MaintInfoGrp_Unit33_ISig_4 1;
BA_ "GenSigStartValue" SG_ 2566560036 MaintInfoGrp_Unit33_ISig_4 7;
BA_ "GenSigMaxLatency" SG_ 2566560036 MaintInfoGrp_Unit33_ISig_4 3000;
BA_ "Platform_VMCU1_Sig" SG_ 2566560036 MaintInfoGrp_Unit33_ISig_4 1;
BA_ "GenSigSendType" SG_ 2566560036 MaintInfoGrp_Supported26_ISig_4 1;
BA_ "GenSigStartValue" SG_ 2566560036 MaintInfoGrp_Supported26_ISig_4 3;
BA_ "GenSigMaxLatency" SG_ 2566560036 MaintInfoGrp_Supported26_ISig_4 3000;
BA_ "Platform_VMCU1_Sig" SG_ 2566560036 MaintInfoGrp_Supported26_ISig_4 1;
BA_ "GenSigSendType" SG_ 2566560036 MaintInfoGrp_ResetAuthorized6_IS 1;
BA_ "GenSigStartValue" SG_ 2566560036 MaintInfoGrp_ResetAuthorized6_IS 3;
BA_ "GenSigMaxLatency" SG_ 2566560036 MaintInfoGrp_ResetAuthorized6_IS 3000;
BA_ "Platform_VMCU1_Sig" SG_ 2566560036 MaintInfoGrp_ResetAuthorized6_IS 1;
BA_ "SystemSignalLongSymbol" SG_ 2566560036 MaintInfoGrp_ResetAuthorized6_IS "MaintInfoGrp_ResetAuthorized6_ISig_4";
BA_ "GenSigSendType" SG_ 2566560036 MaintInfoGrp_Data18_ISig_4 1;
BA_ "GenSigStartValue" SG_ 2566560036 MaintInfoGrp_Data18_ISig_4 4294967295;
BA_ "GenSigMaxLatency" SG_ 2566560036 MaintInfoGrp_Data18_ISig_4 3000;
BA_ "Platform_VMCU1_Sig" SG_ 2566560036 MaintInfoGrp_Data18_ISig_4 1;
BA_ "GenSigSendType" SG_ 2566560036 MaintInfoGrp_Status16_ISig_4 1;
BA_ "GenSigStartValue" SG_ 2566560036 MaintInfoGrp_Status16_ISig_4 7;
BA_ "GenSigMaxLatency" SG_ 2566560036 MaintInfoGrp_Status16_ISig_4 3000;
BA_ "Platform_VMCU1_Sig" SG_ 2566560036 MaintInfoGrp_Status16_ISig_4 1;
BA_ "GenSigSendType" SG_ 2566560036 MaintInfoGrp_ResetAuthorized18_I 1;
BA_ "GenSigStartValue" SG_ 2566560036 MaintInfoGrp_ResetAuthorized18_I 3;
BA_ "GenSigMaxLatency" SG_ 2566560036 MaintInfoGrp_ResetAuthorized18_I 3000;
BA_ "Platform_VMCU1_Sig" SG_ 2566560036 MaintInfoGrp_ResetAuthorized18_I 1;
BA_ "SystemSignalLongSymbol" SG_ 2566560036 MaintInfoGrp_ResetAuthorized18_I "MaintInfoGrp_ResetAuthorized18_ISig_4";
BA_ "GenSigSendType" SG_ 2566560036 MaintInfoGrp_Status4_ISig_4 1;
BA_ "GenSigStartValue" SG_ 2566560036 MaintInfoGrp_Status4_ISig_4 7;
BA_ "GenSigMaxLatency" SG_ 2566560036 MaintInfoGrp_Status4_ISig_4 3000;
BA_ "Platform_VMCU1_Sig" SG_ 2566560036 MaintInfoGrp_Status4_ISig_4 1;
BA_ "GenSigSendType" SG_ 2566560036 MaintInfoGrp_Data3_ISig_4 1;
BA_ "GenSigStartValue" SG_ 2566560036 MaintInfoGrp_Data3_ISig_4 4294967295;
BA_ "GenSigMaxLatency" SG_ 2566560036 MaintInfoGrp_Data3_ISig_4 3000;
BA_ "Platform_VMCU1_Sig" SG_ 2566560036 MaintInfoGrp_Data3_ISig_4 1;
BA_ "GenSigSendType" SG_ 2566560036 MaintInfoGrp_MaintOption20_ISig_ 1;
BA_ "GenSigStartValue" SG_ 2566560036 MaintInfoGrp_MaintOption20_ISig_ 15;
BA_ "GenSigMaxLatency" SG_ 2566560036 MaintInfoGrp_MaintOption20_ISig_ 3000;
BA_ "Platform_VMCU1_Sig" SG_ 2566560036 MaintInfoGrp_MaintOption20_ISig_ 1;
BA_ "SystemSignalLongSymbol" SG_ 2566560036 MaintInfoGrp_MaintOption20_ISig_ "MaintInfoGrp_MaintOption20_ISig_4";
BA_ "GenSigSendType" SG_ 2566560036 MaintInfoGrp_ResetAuthorized30_I 1;
BA_ "GenSigStartValue" SG_ 2566560036 MaintInfoGrp_ResetAuthorized30_I 3;
BA_ "GenSigMaxLatency" SG_ 2566560036 MaintInfoGrp_ResetAuthorized30_I 3000;
BA_ "Platform_VMCU1_Sig" SG_ 2566560036 MaintInfoGrp_ResetAuthorized30_I 1;
BA_ "SystemSignalLongSymbol" SG_ 2566560036 MaintInfoGrp_ResetAuthorized30_I "MaintInfoGrp_ResetAuthorized30_ISig_4";
BA_ "GenSigSendType" SG_ 2566560036 MaintInfoGrp_ResetAuthorized23_I 1;
BA_ "GenSigStartValue" SG_ 2566560036 MaintInfoGrp_ResetAuthorized23_I 3;
BA_ "GenSigMaxLatency" SG_ 2566560036 MaintInfoGrp_ResetAuthorized23_I 3000;
BA_ "Platform_VMCU1_Sig" SG_ 2566560036 MaintInfoGrp_ResetAuthorized23_I 1;
BA_ "SystemSignalLongSymbol" SG_ 2566560036 MaintInfoGrp_ResetAuthorized23_I "MaintInfoGrp_ResetAuthorized23_ISig_4";
BA_ "GenSigSendType" SG_ 2566560036 MaintInfoGrp_Unit30_ISig_4 1;
BA_ "GenSigStartValue" SG_ 2566560036 MaintInfoGrp_Unit30_ISig_4 7;
BA_ "GenSigMaxLatency" SG_ 2566560036 MaintInfoGrp_Unit30_ISig_4 3000;
BA_ "Platform_VMCU1_Sig" SG_ 2566560036 MaintInfoGrp_Unit30_ISig_4 1;
BA_ "GenSigSendType" SG_ 2566560036 MaintInfoGrp_Data20_ISig_4 1;
BA_ "GenSigStartValue" SG_ 2566560036 MaintInfoGrp_Data20_ISig_4 4294967295;
BA_ "GenSigMaxLatency" SG_ 2566560036 MaintInfoGrp_Data20_ISig_4 3000;
BA_ "Platform_VMCU1_Sig" SG_ 2566560036 MaintInfoGrp_Data20_ISig_4 1;
BA_ "GenSigSendType" SG_ 2566560036 MaintInfoGrp_MaintOption23_ISig_ 1;
BA_ "GenSigStartValue" SG_ 2566560036 MaintInfoGrp_MaintOption23_ISig_ 15;
BA_ "GenSigMaxLatency" SG_ 2566560036 MaintInfoGrp_MaintOption23_ISig_ 3000;
BA_ "Platform_VMCU1_Sig" SG_ 2566560036 MaintInfoGrp_MaintOption23_ISig_ 1;
BA_ "SystemSignalLongSymbol" SG_ 2566560036 MaintInfoGrp_MaintOption23_ISig_ "MaintInfoGrp_MaintOption23_ISig_4";
BA_ "GenSigSendType" SG_ 2566560036 MaintInfoGrp_Data23_ISig_4 1;
BA_ "GenSigStartValue" SG_ 2566560036 MaintInfoGrp_Data23_ISig_4 4294967295;
BA_ "GenSigMaxLatency" SG_ 2566560036 MaintInfoGrp_Data23_ISig_4 3000;
BA_ "Platform_VMCU1_Sig" SG_ 2566560036 MaintInfoGrp_Data23_ISig_4 1;
BA_ "GenSigSendType" SG_ 2566560036 MaintInfoGrp_Unit20_ISig_4 1;
BA_ "GenSigStartValue" SG_ 2566560036 MaintInfoGrp_Unit20_ISig_4 7;
BA_ "GenSigMaxLatency" SG_ 2566560036 MaintInfoGrp_Unit20_ISig_4 3000;
BA_ "Platform_VMCU1_Sig" SG_ 2566560036 MaintInfoGrp_Unit20_ISig_4 1;
BA_ "GenSigSendType" SG_ 2566560036 MaintInfoGrp_MaintOption10_ISig_ 1;
BA_ "GenSigStartValue" SG_ 2566560036 MaintInfoGrp_MaintOption10_ISig_ 15;
BA_ "GenSigMaxLatency" SG_ 2566560036 MaintInfoGrp_MaintOption10_ISig_ 3000;
BA_ "Platform_VMCU1_Sig" SG_ 2566560036 MaintInfoGrp_MaintOption10_ISig_ 1;
BA_ "SystemSignalLongSymbol" SG_ 2566560036 MaintInfoGrp_MaintOption10_ISig_ "MaintInfoGrp_MaintOption10_ISig_4";
BA_ "GenSigSendType" SG_ 2566560036 MaintInfoGrp_Status39_ISig_4 1;
BA_ "GenSigStartValue" SG_ 2566560036 MaintInfoGrp_Status39_ISig_4 7;
BA_ "GenSigMaxLatency" SG_ 2566560036 MaintInfoGrp_Status39_ISig_4 3000;
BA_ "Platform_VMCU1_Sig" SG_ 2566560036 MaintInfoGrp_Status39_ISig_4 1;
BA_ "GenSigSendType" SG_ 2566560036 MaintInfoGrp_Data21_ISig_4 1;
BA_ "GenSigStartValue" SG_ 2566560036 MaintInfoGrp_Data21_ISig_4 4294967295;
BA_ "GenSigMaxLatency" SG_ 2566560036 MaintInfoGrp_Data21_ISig_4 3000;
BA_ "Platform_VMCU1_Sig" SG_ 2566560036 MaintInfoGrp_Data21_ISig_4 1;
BA_ "GenSigSendType" SG_ 2566560036 MaintInfoGrp_Status3_ISig_4 1;
BA_ "GenSigStartValue" SG_ 2566560036 MaintInfoGrp_Status3_ISig_4 7;
BA_ "GenSigMaxLatency" SG_ 2566560036 MaintInfoGrp_Status3_ISig_4 3000;
BA_ "Platform_VMCU1_Sig" SG_ 2566560036 MaintInfoGrp_Status3_ISig_4 1;
BA_ "GenSigSendType" SG_ 2566560036 MaintInfoGrp_Data5_ISig_4 1;
BA_ "GenSigStartValue" SG_ 2566560036 MaintInfoGrp_Data5_ISig_4 4294967295;
BA_ "GenSigMaxLatency" SG_ 2566560036 MaintInfoGrp_Data5_ISig_4 3000;
BA_ "Platform_VMCU1_Sig" SG_ 2566560036 MaintInfoGrp_Data5_ISig_4 1;
BA_ "GenSigSendType" SG_ 2566560036 MaintInfoGrp_ResetAuthorized26_I 1;
BA_ "GenSigStartValue" SG_ 2566560036 MaintInfoGrp_ResetAuthorized26_I 3;
BA_ "GenSigMaxLatency" SG_ 2566560036 MaintInfoGrp_ResetAuthorized26_I 3000;
BA_ "Platform_VMCU1_Sig" SG_ 2566560036 MaintInfoGrp_ResetAuthorized26_I 1;
BA_ "SystemSignalLongSymbol" SG_ 2566560036 MaintInfoGrp_ResetAuthorized26_I "MaintInfoGrp_ResetAuthorized26_ISig_4";
BA_ "GenSigSendType" SG_ 2566560036 MaintInfoGrp_Supported12_ISig_4 1;
BA_ "GenSigStartValue" SG_ 2566560036 MaintInfoGrp_Supported12_ISig_4 3;
BA_ "GenSigMaxLatency" SG_ 2566560036 MaintInfoGrp_Supported12_ISig_4 3000;
BA_ "Platform_VMCU1_Sig" SG_ 2566560036 MaintInfoGrp_Supported12_ISig_4 1;
BA_ "GenSigSendType" SG_ 2566560036 MaintInfoGrp_Data32_ISig_4 1;
BA_ "GenSigStartValue" SG_ 2566560036 MaintInfoGrp_Data32_ISig_4 4294967295;
BA_ "GenSigMaxLatency" SG_ 2566560036 MaintInfoGrp_Data32_ISig_4 3000;
BA_ "Platform_VMCU1_Sig" SG_ 2566560036 MaintInfoGrp_Data32_ISig_4 1;
BA_ "GenSigSendType" SG_ 2566560036 MaintInfoGrp_Status29_ISig_4 1;
BA_ "GenSigStartValue" SG_ 2566560036 MaintInfoGrp_Status29_ISig_4 7;
BA_ "GenSigMaxLatency" SG_ 2566560036 MaintInfoGrp_Status29_ISig_4 3000;
BA_ "Platform_VMCU1_Sig" SG_ 2566560036 MaintInfoGrp_Status29_ISig_4 1;
BA_ "GenSigSendType" SG_ 2566560036 MaintInfoGrp_ResetAuthorized37_I 1;
BA_ "GenSigStartValue" SG_ 2566560036 MaintInfoGrp_ResetAuthorized37_I 3;
BA_ "GenSigMaxLatency" SG_ 2566560036 MaintInfoGrp_ResetAuthorized37_I 3000;
BA_ "Platform_VMCU1_Sig" SG_ 2566560036 MaintInfoGrp_ResetAuthorized37_I 1;
BA_ "SystemSignalLongSymbol" SG_ 2566560036 MaintInfoGrp_ResetAuthorized37_I "MaintInfoGrp_ResetAuthorized37_ISig_4";
BA_ "GenSigSendType" SG_ 2566560036 MaintInfoGrp_Status36_ISig_4 1;
BA_ "GenSigStartValue" SG_ 2566560036 MaintInfoGrp_Status36_ISig_4 7;
BA_ "GenSigMaxLatency" SG_ 2566560036 MaintInfoGrp_Status36_ISig_4 3000;
BA_ "Platform_VMCU1_Sig" SG_ 2566560036 MaintInfoGrp_Status36_ISig_4 1;
BA_ "GenSigSendType" SG_ 2566560036 MaintInfoGrp_Supported22_ISig_4 1;
BA_ "GenSigStartValue" SG_ 2566560036 MaintInfoGrp_Supported22_ISig_4 3;
BA_ "GenSigMaxLatency" SG_ 2566560036 MaintInfoGrp_Supported22_ISig_4 3000;
BA_ "Platform_VMCU1_Sig" SG_ 2566560036 MaintInfoGrp_Supported22_ISig_4 1;
BA_ "GenSigSendType" SG_ 2566560036 MaintInfoGrp_Status35_ISig_4 1;
BA_ "GenSigStartValue" SG_ 2566560036 MaintInfoGrp_Status35_ISig_4 7;
BA_ "GenSigMaxLatency" SG_ 2566560036 MaintInfoGrp_Status35_ISig_4 3000;
BA_ "Platform_VMCU1_Sig" SG_ 2566560036 MaintInfoGrp_Status35_ISig_4 1;
BA_ "GenSigSendType" SG_ 2566560036 MaintInfoGrp_Data7_ISig_4 1;
BA_ "GenSigStartValue" SG_ 2566560036 MaintInfoGrp_Data7_ISig_4 4294967295;
BA_ "GenSigMaxLatency" SG_ 2566560036 MaintInfoGrp_Data7_ISig_4 3000;
BA_ "Platform_VMCU1_Sig" SG_ 2566560036 MaintInfoGrp_Data7_ISig_4 1;
BA_ "GenSigSendType" SG_ 2566560036 MaintInfoGrp_MaintOption26_ISig_ 1;
BA_ "GenSigStartValue" SG_ 2566560036 MaintInfoGrp_MaintOption26_ISig_ 15;
BA_ "GenSigMaxLatency" SG_ 2566560036 MaintInfoGrp_MaintOption26_ISig_ 3000;
BA_ "Platform_VMCU1_Sig" SG_ 2566560036 MaintInfoGrp_MaintOption26_ISig_ 1;
BA_ "SystemSignalLongSymbol" SG_ 2566560036 MaintInfoGrp_MaintOption26_ISig_ "MaintInfoGrp_MaintOption26_ISig_4";
BA_ "GenSigSendType" SG_ 2566560036 MaintInfoGrp_Status23_ISig_4 1;
BA_ "GenSigStartValue" SG_ 2566560036 MaintInfoGrp_Status23_ISig_4 7;
BA_ "GenSigMaxLatency" SG_ 2566560036 MaintInfoGrp_Status23_ISig_4 3000;
BA_ "Platform_VMCU1_Sig" SG_ 2566560036 MaintInfoGrp_Status23_ISig_4 1;
BA_ "GenSigSendType" SG_ 2566560036 MaintInfoGrp_Unit35_ISig_4 1;
BA_ "GenSigStartValue" SG_ 2566560036 MaintInfoGrp_Unit35_ISig_4 7;
BA_ "GenSigMaxLatency" SG_ 2566560036 MaintInfoGrp_Unit35_ISig_4 3000;
BA_ "Platform_VMCU1_Sig" SG_ 2566560036 MaintInfoGrp_Unit35_ISig_4 1;
BA_ "GenSigSendType" SG_ 2566560036 MaintInfoGrp_Supported6_ISig_4 1;
BA_ "GenSigStartValue" SG_ 2566560036 MaintInfoGrp_Supported6_ISig_4 3;
BA_ "GenSigMaxLatency" SG_ 2566560036 MaintInfoGrp_Supported6_ISig_4 3000;
BA_ "Platform_VMCU1_Sig" SG_ 2566560036 MaintInfoGrp_Supported6_ISig_4 1;
BA_ "GenSigSendType" SG_ 2566560036 MaintInfoGrp_Data34_ISig_4 1;
BA_ "GenSigStartValue" SG_ 2566560036 MaintInfoGrp_Data34_ISig_4 4294967295;
BA_ "GenSigMaxLatency" SG_ 2566560036 MaintInfoGrp_Data34_ISig_4 3000;
BA_ "Platform_VMCU1_Sig" SG_ 2566560036 MaintInfoGrp_Data34_ISig_4 1;
BA_ "GenSigSendType" SG_ 2566560036 MaintInfoGrp_Unit27_ISig_4 1;
BA_ "GenSigStartValue" SG_ 2566560036 MaintInfoGrp_Unit27_ISig_4 7;
BA_ "GenSigMaxLatency" SG_ 2566560036 MaintInfoGrp_Unit27_ISig_4 3000;
BA_ "Platform_VMCU1_Sig" SG_ 2566560036 MaintInfoGrp_Unit27_ISig_4 1;
BA_ "GenSigSendType" SG_ 2566560036 MaintInfoGrp_MaintOption19_ISig_ 1;
BA_ "GenSigStartValue" SG_ 2566560036 MaintInfoGrp_MaintOption19_ISig_ 15;
BA_ "GenSigMaxLatency" SG_ 2566560036 MaintInfoGrp_MaintOption19_ISig_ 3000;
BA_ "Platform_VMCU1_Sig" SG_ 2566560036 MaintInfoGrp_MaintOption19_ISig_ 1;
BA_ "SystemSignalLongSymbol" SG_ 2566560036 MaintInfoGrp_MaintOption19_ISig_ "MaintInfoGrp_MaintOption19_ISig_4";
BA_ "GenSigSendType" SG_ 2566560036 MaintInfoGrp_ResetAuthorized14_I 1;
BA_ "GenSigStartValue" SG_ 2566560036 MaintInfoGrp_ResetAuthorized14_I 3;
BA_ "GenSigMaxLatency" SG_ 2566560036 MaintInfoGrp_ResetAuthorized14_I 3000;
BA_ "Platform_VMCU1_Sig" SG_ 2566560036 MaintInfoGrp_ResetAuthorized14_I 1;
BA_ "SystemSignalLongSymbol" SG_ 2566560036 MaintInfoGrp_ResetAuthorized14_I "MaintInfoGrp_ResetAuthorized14_ISig_4";
BA_ "GenSigSendType" SG_ 2566560036 MaintInfoGrp_Status34_ISig_4 1;
BA_ "GenSigStartValue" SG_ 2566560036 MaintInfoGrp_Status34_ISig_4 7;
BA_ "GenSigMaxLatency" SG_ 2566560036 MaintInfoGrp_Status34_ISig_4 3000;
BA_ "Platform_VMCU1_Sig" SG_ 2566560036 MaintInfoGrp_Status34_ISig_4 1;
BA_ "GenSigSendType" SG_ 2566560036 MaintInfoGrp_Supported37_ISig_4 1;
BA_ "GenSigStartValue" SG_ 2566560036 MaintInfoGrp_Supported37_ISig_4 3;
BA_ "GenSigMaxLatency" SG_ 2566560036 MaintInfoGrp_Supported37_ISig_4 3000;
BA_ "Platform_VMCU1_Sig" SG_ 2566560036 MaintInfoGrp_Supported37_ISig_4 1;
BA_ "GenSigSendType" SG_ 2566560036 MaintInfoGrp_MaintOption3_ISig_4 1;
BA_ "GenSigStartValue" SG_ 2566560036 MaintInfoGrp_MaintOption3_ISig_4 15;
BA_ "GenSigMaxLatency" SG_ 2566560036 MaintInfoGrp_MaintOption3_ISig_4 3000;
BA_ "Platform_VMCU1_Sig" SG_ 2566560036 MaintInfoGrp_MaintOption3_ISig_4 1;
BA_ "GenSigSendType" SG_ 2566560036 MaintInfoGrp_Status1_ISig_4 1;
BA_ "GenSigStartValue" SG_ 2566560036 MaintInfoGrp_Status1_ISig_4 7;
BA_ "GenSigMaxLatency" SG_ 2566560036 MaintInfoGrp_Status1_ISig_4 3000;
BA_ "Platform_VMCU1_Sig" SG_ 2566560036 MaintInfoGrp_Status1_ISig_4 1;
BA_ "GenSigSendType" SG_ 2566560036 MaintInfoGrp_Data1_ISig_4 1;
BA_ "GenSigStartValue" SG_ 2566560036 MaintInfoGrp_Data1_ISig_4 4294967295;
BA_ "GenSigMaxLatency" SG_ 2566560036 MaintInfoGrp_Data1_ISig_4 3000;
BA_ "Platform_VMCU1_Sig" SG_ 2566560036 MaintInfoGrp_Data1_ISig_4 1;
BA_ "GenSigSendType" SG_ 2566560036 MaintInfoGrp_Status25_ISig_4 1;
BA_ "GenSigStartValue" SG_ 2566560036 MaintInfoGrp_Status25_ISig_4 7;
BA_ "GenSigMaxLatency" SG_ 2566560036 MaintInfoGrp_Status25_ISig_4 3000;
BA_ "Platform_VMCU1_Sig" SG_ 2566560036 MaintInfoGrp_Status25_ISig_4 1;
BA_ "GenSigSendType" SG_ 2566560036 MaintInfoGrp_ResetAuthorized1_IS 1;
BA_ "GenSigStartValue" SG_ 2566560036 MaintInfoGrp_ResetAuthorized1_IS 3;
BA_ "GenSigMaxLatency" SG_ 2566560036 MaintInfoGrp_ResetAuthorized1_IS 3000;
BA_ "Platform_VMCU1_Sig" SG_ 2566560036 MaintInfoGrp_ResetAuthorized1_IS 1;
BA_ "SystemSignalLongSymbol" SG_ 2566560036 MaintInfoGrp_ResetAuthorized1_IS "MaintInfoGrp_ResetAuthorized1_ISig_4";
BA_ "GenSigSendType" SG_ 2566560036 MaintInfoGrp_ResetAuthorized27_I 1;
BA_ "GenSigStartValue" SG_ 2566560036 MaintInfoGrp_ResetAuthorized27_I 3;
BA_ "GenSigMaxLatency" SG_ 2566560036 MaintInfoGrp_ResetAuthorized27_I 3000;
BA_ "Platform_VMCU1_Sig" SG_ 2566560036 MaintInfoGrp_ResetAuthorized27_I 1;
BA_ "SystemSignalLongSymbol" SG_ 2566560036 MaintInfoGrp_ResetAuthorized27_I "MaintInfoGrp_ResetAuthorized27_ISig_4";
BA_ "GenSigSendType" SG_ 2566560036 MaintInfoGrp_ResetAuthorized36_I 1;
BA_ "GenSigStartValue" SG_ 2566560036 MaintInfoGrp_ResetAuthorized36_I 3;
BA_ "GenSigMaxLatency" SG_ 2566560036 MaintInfoGrp_ResetAuthorized36_I 3000;
BA_ "Platform_VMCU1_Sig" SG_ 2566560036 MaintInfoGrp_ResetAuthorized36_I 1;
BA_ "SystemSignalLongSymbol" SG_ 2566560036 MaintInfoGrp_ResetAuthorized36_I "MaintInfoGrp_ResetAuthorized36_ISig_4";
BA_ "GenSigSendType" SG_ 2566560036 MaintInfoGrp_Status28_ISig_4 1;
BA_ "GenSigStartValue" SG_ 2566560036 MaintInfoGrp_Status28_ISig_4 7;
BA_ "GenSigMaxLatency" SG_ 2566560036 MaintInfoGrp_Status28_ISig_4 3000;
BA_ "Platform_VMCU1_Sig" SG_ 2566560036 MaintInfoGrp_Status28_ISig_4 1;
BA_ "GenSigSendType" SG_ 2566560036 MaintInfoGrp_Status24_ISig_4 1;
BA_ "GenSigStartValue" SG_ 2566560036 MaintInfoGrp_Status24_ISig_4 7;
BA_ "GenSigMaxLatency" SG_ 2566560036 MaintInfoGrp_Status24_ISig_4 3000;
BA_ "Platform_VMCU1_Sig" SG_ 2566560036 MaintInfoGrp_Status24_ISig_4 1;
BA_ "GenSigSendType" SG_ 2566560036 MaintInfoGrp_MaintOption31_ISig_ 1;
BA_ "GenSigStartValue" SG_ 2566560036 MaintInfoGrp_MaintOption31_ISig_ 15;
BA_ "GenSigMaxLatency" SG_ 2566560036 MaintInfoGrp_MaintOption31_ISig_ 3000;
BA_ "Platform_VMCU1_Sig" SG_ 2566560036 MaintInfoGrp_MaintOption31_ISig_ 1;
BA_ "SystemSignalLongSymbol" SG_ 2566560036 MaintInfoGrp_MaintOption31_ISig_ "MaintInfoGrp_MaintOption31_ISig_4";
BA_ "GenSigSendType" SG_ 2566560036 MaintInfoGrp_Supported20_ISig_4 1;
BA_ "GenSigStartValue" SG_ 2566560036 MaintInfoGrp_Supported20_ISig_4 3;
BA_ "GenSigMaxLatency" SG_ 2566560036 MaintInfoGrp_Supported20_ISig_4 3000;
BA_ "Platform_VMCU1_Sig" SG_ 2566560036 MaintInfoGrp_Supported20_ISig_4 1;
BA_ "GenSigSendType" SG_ 2566560036 MaintInfoGrp_Unit38_ISig_4 1;
BA_ "GenSigStartValue" SG_ 2566560036 MaintInfoGrp_Unit38_ISig_4 7;
BA_ "GenSigMaxLatency" SG_ 2566560036 MaintInfoGrp_Unit38_ISig_4 3000;
BA_ "Platform_VMCU1_Sig" SG_ 2566560036 MaintInfoGrp_Unit38_ISig_4 1;
BA_ "GenSigSendType" SG_ 2566560036 MaintInfoGrp_Unit24_ISig_4 1;
BA_ "GenSigStartValue" SG_ 2566560036 MaintInfoGrp_Unit24_ISig_4 7;
BA_ "GenSigMaxLatency" SG_ 2566560036 MaintInfoGrp_Unit24_ISig_4 3000;
BA_ "Platform_VMCU1_Sig" SG_ 2566560036 MaintInfoGrp_Unit24_ISig_4 1;
BA_ "GenSigSendType" SG_ 2566560036 MaintInfoGrp_Data15_ISig_4 1;
BA_ "GenSigStartValue" SG_ 2566560036 MaintInfoGrp_Data15_ISig_4 4294967295;
BA_ "GenSigMaxLatency" SG_ 2566560036 MaintInfoGrp_Data15_ISig_4 3000;
BA_ "Platform_VMCU1_Sig" SG_ 2566560036 MaintInfoGrp_Data15_ISig_4 1;
BA_ "GenSigSendType" SG_ 2566560036 MaintInfoGrp_Status37_ISig_4 1;
BA_ "GenSigStartValue" SG_ 2566560036 MaintInfoGrp_Status37_ISig_4 7;
BA_ "GenSigMaxLatency" SG_ 2566560036 MaintInfoGrp_Status37_ISig_4 3000;
BA_ "Platform_VMCU1_Sig" SG_ 2566560036 MaintInfoGrp_Status37_ISig_4 1;
BA_ "GenSigSendType" SG_ 2566560036 MaintInfoGrp_Supported39_ISig_4 1;
BA_ "GenSigStartValue" SG_ 2566560036 MaintInfoGrp_Supported39_ISig_4 3;
BA_ "GenSigMaxLatency" SG_ 2566560036 MaintInfoGrp_Supported39_ISig_4 3000;
BA_ "Platform_VMCU1_Sig" SG_ 2566560036 MaintInfoGrp_Supported39_ISig_4 1;
BA_ "GenSigSendType" SG_ 2566560036 MaintInfoGrp_MaintOption39_ISig_ 1;
BA_ "GenSigStartValue" SG_ 2566560036 MaintInfoGrp_MaintOption39_ISig_ 15;
BA_ "GenSigMaxLatency" SG_ 2566560036 MaintInfoGrp_MaintOption39_ISig_ 3000;
BA_ "Platform_VMCU1_Sig" SG_ 2566560036 MaintInfoGrp_MaintOption39_ISig_ 1;
BA_ "SystemSignalLongSymbol" SG_ 2566560036 MaintInfoGrp_MaintOption39_ISig_ "MaintInfoGrp_MaintOption39_ISig_4";
BA_ "GenSigSendType" SG_ 2566560036 MaintInfoGrp_Supported4_ISig_4 1;
BA_ "GenSigStartValue" SG_ 2566560036 MaintInfoGrp_Supported4_ISig_4 3;
BA_ "GenSigMaxLatency" SG_ 2566560036 MaintInfoGrp_Supported4_ISig_4 3000;
BA_ "Platform_VMCU1_Sig" SG_ 2566560036 MaintInfoGrp_Supported4_ISig_4 1;
BA_ "GenSigSendType" SG_ 2566560036 MaintInfoGrp_Supported3_ISig_4 1;
BA_ "GenSigStartValue" SG_ 2566560036 MaintInfoGrp_Supported3_ISig_4 3;
BA_ "GenSigMaxLatency" SG_ 2566560036 MaintInfoGrp_Supported3_ISig_4 3000;
BA_ "Platform_VMCU1_Sig" SG_ 2566560036 MaintInfoGrp_Supported3_ISig_4 1;
BA_ "GenSigSendType" SG_ 2566560036 MaintInfoGrp_Data6_ISig_4 1;
BA_ "GenSigStartValue" SG_ 2566560036 MaintInfoGrp_Data6_ISig_4 4294967295;
BA_ "GenSigMaxLatency" SG_ 2566560036 MaintInfoGrp_Data6_ISig_4 3000;
BA_ "Platform_VMCU1_Sig" SG_ 2566560036 MaintInfoGrp_Data6_ISig_4 1;
BA_ "GenSigSendType" SG_ 2566560036 MaintInfoGrp_Unit39_ISig_4 1;
BA_ "GenSigStartValue" SG_ 2566560036 MaintInfoGrp_Unit39_ISig_4 7;
BA_ "GenSigMaxLatency" SG_ 2566560036 MaintInfoGrp_Unit39_ISig_4 3000;
BA_ "Platform_VMCU1_Sig" SG_ 2566560036 MaintInfoGrp_Unit39_ISig_4 1;
BA_ "GenSigSendType" SG_ 2566560036 MaintInfoGrp_Status5_ISig_4 1;
BA_ "GenSigStartValue" SG_ 2566560036 MaintInfoGrp_Status5_ISig_4 7;
BA_ "GenSigMaxLatency" SG_ 2566560036 MaintInfoGrp_Status5_ISig_4 3000;
BA_ "Platform_VMCU1_Sig" SG_ 2566560036 MaintInfoGrp_Status5_ISig_4 1;
BA_ "GenSigSendType" SG_ 2566560036 MaintInfoGrp_Data36_ISig_4 1;
BA_ "GenSigStartValue" SG_ 2566560036 MaintInfoGrp_Data36_ISig_4 4294967295;
BA_ "GenSigMaxLatency" SG_ 2566560036 MaintInfoGrp_Data36_ISig_4 3000;
BA_ "Platform_VMCU1_Sig" SG_ 2566560036 MaintInfoGrp_Data36_ISig_4 1;
BA_ "GenSigSendType" SG_ 2566560036 MaintInfoGrp_MaintOption6_ISig_4 1;
BA_ "GenSigStartValue" SG_ 2566560036 MaintInfoGrp_MaintOption6_ISig_4 15;
BA_ "GenSigMaxLatency" SG_ 2566560036 MaintInfoGrp_MaintOption6_ISig_4 3000;
BA_ "Platform_VMCU1_Sig" SG_ 2566560036 MaintInfoGrp_MaintOption6_ISig_4 1;
BA_ "GenSigSendType" SG_ 2566560036 MaintInfoGrp_Status11_ISig_4 1;
BA_ "GenSigStartValue" SG_ 2566560036 MaintInfoGrp_Status11_ISig_4 7;
BA_ "GenSigMaxLatency" SG_ 2566560036 MaintInfoGrp_Status11_ISig_4 3000;
BA_ "Platform_VMCU1_Sig" SG_ 2566560036 MaintInfoGrp_Status11_ISig_4 1;
BA_ "GenSigSendType" SG_ 2566560036 MaintInfoGrp_Status19_ISig_4 1;
BA_ "GenSigStartValue" SG_ 2566560036 MaintInfoGrp_Status19_ISig_4 7;
BA_ "GenSigMaxLatency" SG_ 2566560036 MaintInfoGrp_Status19_ISig_4 3000;
BA_ "Platform_VMCU1_Sig" SG_ 2566560036 MaintInfoGrp_Status19_ISig_4 1;
BA_ "GenSigSendType" SG_ 2566560036 MaintInfoGrp_Status9_ISig_4 1;
BA_ "GenSigStartValue" SG_ 2566560036 MaintInfoGrp_Status9_ISig_4 7;
BA_ "GenSigMaxLatency" SG_ 2566560036 MaintInfoGrp_Status9_ISig_4 3000;
BA_ "Platform_VMCU1_Sig" SG_ 2566560036 MaintInfoGrp_Status9_ISig_4 1;
BA_ "GenSigSendType" SG_ 2566560036 MaintInfoGrp_Supported11_ISig_4 1;
BA_ "GenSigStartValue" SG_ 2566560036 MaintInfoGrp_Supported11_ISig_4 3;
BA_ "GenSigMaxLatency" SG_ 2566560036 MaintInfoGrp_Supported11_ISig_4 3000;
BA_ "Platform_VMCU1_Sig" SG_ 2566560036 MaintInfoGrp_Supported11_ISig_4 1;
BA_ "GenSigSendType" SG_ 2566560036 MaintInfoGrp_Data27_ISig_4 1;
BA_ "GenSigStartValue" SG_ 2566560036 MaintInfoGrp_Data27_ISig_4 4294967295;
BA_ "GenSigMaxLatency" SG_ 2566560036 MaintInfoGrp_Data27_ISig_4 3000;
BA_ "Platform_VMCU1_Sig" SG_ 2566560036 MaintInfoGrp_Data27_ISig_4 1;
BA_ "GenSigSendType" SG_ 2566560036 MaintInfoGrp_Data31_ISig_4 1;
BA_ "GenSigStartValue" SG_ 2566560036 MaintInfoGrp_Data31_ISig_4 4294967295;
BA_ "GenSigMaxLatency" SG_ 2566560036 MaintInfoGrp_Data31_ISig_4 3000;
BA_ "Platform_VMCU1_Sig" SG_ 2566560036 MaintInfoGrp_Data31_ISig_4 1;
BA_ "GenSigSendType" SG_ 2566560036 MaintInfoGrp_MaintOption36_ISig_ 1;
BA_ "GenSigStartValue" SG_ 2566560036 MaintInfoGrp_MaintOption36_ISig_ 15;
BA_ "GenSigMaxLatency" SG_ 2566560036 MaintInfoGrp_MaintOption36_ISig_ 3000;
BA_ "Platform_VMCU1_Sig" SG_ 2566560036 MaintInfoGrp_MaintOption36_ISig_ 1;
BA_ "SystemSignalLongSymbol" SG_ 2566560036 MaintInfoGrp_MaintOption36_ISig_ "MaintInfoGrp_MaintOption36_ISig_4";
BA_ "GenSigSendType" SG_ 2566560036 MaintInfoGrp_ResetAuthorized8_IS 1;
BA_ "GenSigStartValue" SG_ 2566560036 MaintInfoGrp_ResetAuthorized8_IS 3;
BA_ "GenSigMaxLatency" SG_ 2566560036 MaintInfoGrp_ResetAuthorized8_IS 3000;
BA_ "Platform_VMCU1_Sig" SG_ 2566560036 MaintInfoGrp_ResetAuthorized8_IS 1;
BA_ "SystemSignalLongSymbol" SG_ 2566560036 MaintInfoGrp_ResetAuthorized8_IS "MaintInfoGrp_ResetAuthorized8_ISig_4";
BA_ "GenSigSendType" SG_ 2566560036 MaintInfoGrp_MaintOption21_ISig_ 1;
BA_ "GenSigStartValue" SG_ 2566560036 MaintInfoGrp_MaintOption21_ISig_ 15;
BA_ "GenSigMaxLatency" SG_ 2566560036 MaintInfoGrp_MaintOption21_ISig_ 3000;
BA_ "Platform_VMCU1_Sig" SG_ 2566560036 MaintInfoGrp_MaintOption21_ISig_ 1;
BA_ "SystemSignalLongSymbol" SG_ 2566560036 MaintInfoGrp_MaintOption21_ISig_ "MaintInfoGrp_MaintOption21_ISig_4";
BA_ "GenSigSendType" SG_ 2566560036 MaintInfoGrp_Unit23_ISig_4 1;
BA_ "GenSigStartValue" SG_ 2566560036 MaintInfoGrp_Unit23_ISig_4 7;
BA_ "GenSigMaxLatency" SG_ 2566560036 MaintInfoGrp_Unit23_ISig_4 3000;
BA_ "Platform_VMCU1_Sig" SG_ 2566560036 MaintInfoGrp_Unit23_ISig_4 1;
BA_ "GenSigSendType" SG_ 2566560036 MaintInfoGrp_MaintOption5_ISig_4 1;
BA_ "GenSigStartValue" SG_ 2566560036 MaintInfoGrp_MaintOption5_ISig_4 15;
BA_ "GenSigMaxLatency" SG_ 2566560036 MaintInfoGrp_MaintOption5_ISig_4 3000;
BA_ "Platform_VMCU1_Sig" SG_ 2566560036 MaintInfoGrp_MaintOption5_ISig_4 1;
BA_ "GenSigSendType" SG_ 2566560036 MaintInfoGrp_MaintOption16_ISig_ 1;
BA_ "GenSigStartValue" SG_ 2566560036 MaintInfoGrp_MaintOption16_ISig_ 15;
BA_ "GenSigMaxLatency" SG_ 2566560036 MaintInfoGrp_MaintOption16_ISig_ 3000;
BA_ "Platform_VMCU1_Sig" SG_ 2566560036 MaintInfoGrp_MaintOption16_ISig_ 1;
BA_ "SystemSignalLongSymbol" SG_ 2566560036 MaintInfoGrp_MaintOption16_ISig_ "MaintInfoGrp_MaintOption16_ISig_4";
BA_ "GenSigSendType" SG_ 2566560036 MaintInfoGrp_Unit29_ISig_4 1;
BA_ "GenSigStartValue" SG_ 2566560036 MaintInfoGrp_Unit29_ISig_4 7;
BA_ "GenSigMaxLatency" SG_ 2566560036 MaintInfoGrp_Unit29_ISig_4 3000;
BA_ "Platform_VMCU1_Sig" SG_ 2566560036 MaintInfoGrp_Unit29_ISig_4 1;
BA_ "GenSigSendType" SG_ 2566560036 MaintInfoGrp_Status12_ISig_4 1;
BA_ "GenSigStartValue" SG_ 2566560036 MaintInfoGrp_Status12_ISig_4 7;
BA_ "GenSigMaxLatency" SG_ 2566560036 MaintInfoGrp_Status12_ISig_4 3000;
BA_ "Platform_VMCU1_Sig" SG_ 2566560036 MaintInfoGrp_Status12_ISig_4 1;
BA_ "GenSigSendType" SG_ 2566560036 MaintInfoGrp_Supported0_ISig_4 1;
BA_ "GenSigStartValue" SG_ 2566560036 MaintInfoGrp_Supported0_ISig_4 3;
BA_ "GenSigMaxLatency" SG_ 2566560036 MaintInfoGrp_Supported0_ISig_4 3000;
BA_ "Platform_VMCU1_Sig" SG_ 2566560036 MaintInfoGrp_Supported0_ISig_4 1;
BA_ "GenSigSendType" SG_ 2566560036 MaintInfoGrp_Status8_ISig_4 1;
BA_ "GenSigStartValue" SG_ 2566560036 MaintInfoGrp_Status8_ISig_4 7;
BA_ "GenSigMaxLatency" SG_ 2566560036 MaintInfoGrp_Status8_ISig_4 3000;
BA_ "Platform_VMCU1_Sig" SG_ 2566560036 MaintInfoGrp_Status8_ISig_4 1;
BA_ "GenSigSendType" SG_ 2566560036 MaintInfoGrp_Data11_ISig_4 1;
BA_ "GenSigStartValue" SG_ 2566560036 MaintInfoGrp_Data11_ISig_4 4294967295;
BA_ "GenSigMaxLatency" SG_ 2566560036 MaintInfoGrp_Data11_ISig_4 3000;
BA_ "Platform_VMCU1_Sig" SG_ 2566560036 MaintInfoGrp_Data11_ISig_4 1;
BA_ "GenSigSendType" SG_ 2566560036 MaintInfoGrp_Unit0_ISig_4 1;
BA_ "GenSigStartValue" SG_ 2566560036 MaintInfoGrp_Unit0_ISig_4 7;
BA_ "GenSigMaxLatency" SG_ 2566560036 MaintInfoGrp_Unit0_ISig_4 3000;
BA_ "Platform_VMCU1_Sig" SG_ 2566560036 MaintInfoGrp_Unit0_ISig_4 1;
BA_ "GenSigSendType" SG_ 2566560036 MaintInfoGrp_Supported14_ISig_4 1;
BA_ "GenSigStartValue" SG_ 2566560036 MaintInfoGrp_Supported14_ISig_4 3;
BA_ "GenSigMaxLatency" SG_ 2566560036 MaintInfoGrp_Supported14_ISig_4 3000;
BA_ "Platform_VMCU1_Sig" SG_ 2566560036 MaintInfoGrp_Supported14_ISig_4 1;
BA_ "GenSigSendType" SG_ 2566560036 MaintInfoGrp_Supported8_ISig_4 1;
BA_ "GenSigStartValue" SG_ 2566560036 MaintInfoGrp_Supported8_ISig_4 3;
BA_ "GenSigMaxLatency" SG_ 2566560036 MaintInfoGrp_Supported8_ISig_4 3000;
BA_ "Platform_VMCU1_Sig" SG_ 2566560036 MaintInfoGrp_Supported8_ISig_4 1;
BA_ "GenSigSendType" SG_ 2566044965 VMCU_BB2_32S_FCS 7;
BA_ "Platform_VMCU1_Sig" SG_ 2566044965 VMCU_BB2_32S_FCS 1;
BA_ "GenSigSendType" SG_ 2566044964 ECU2VIN_stat_ISig_4 1;
BA_ "GenSigMaxLatency" SG_ 2566044964 ECU2VIN_stat_ISig_4 137;
BA_ "Platform_VMCU1_Sig" SG_ 2566044964 ECU2VIN_stat_ISig_4 1;
BA_ "GenSigSendType" SG_ 2566089509 VMCU_BB2_31S_FCS 7;
BA_ "Platform_VMCU1_Sig" SG_ 2566089509 VMCU_BB2_31S_FCS 1;
BA_ "GenSigSendType" SG_ 2566089508 ECU1VIN_stat 1;
BA_ "GenSigMaxLatency" SG_ 2566089508 ECU1VIN_stat 137;
BA_ "Platform_VMCU1_Sig" SG_ 2566089508 ECU1VIN_stat 1;
BA_ "GenSigSendType" SG_ 2565822244 MaintInfo_Status 1;
BA_ "GenSigStartValue" SG_ 2565822244 MaintInfo_Status 7;
BA_ "GenSigMaxLatency" SG_ 2565822244 MaintInfo_Status 107;
BA_ "Platform_VMCU1_Sig" SG_ 2565822244 MaintInfo_Status 1;
BA_ "GenSigSendType" SG_ 2565822244 MaintInfo_Unit 1;
BA_ "GenSigStartValue" SG_ 2565822244 MaintInfo_Unit 7;
BA_ "GenSigMaxLatency" SG_ 2565822244 MaintInfo_Unit 107;
BA_ "Platform_VMCU1_Sig" SG_ 2565822244 MaintInfo_Unit 1;
BA_ "GenSigSendType" SG_ 2565822244 MaintInfo_MaintID 1;
BA_ "GenSigStartValue" SG_ 2565822244 MaintInfo_MaintID 63;
BA_ "GenSigMaxLatency" SG_ 2565822244 MaintInfo_MaintID 107;
BA_ "Platform_VMCU1_Sig" SG_ 2565822244 MaintInfo_MaintID 1;
BA_ "GenSigSendType" SG_ 2565822244 MaintInfo_Supported 1;
BA_ "GenSigStartValue" SG_ 2565822244 MaintInfo_Supported 3;
BA_ "GenSigMaxLatency" SG_ 2565822244 MaintInfo_Supported 107;
BA_ "Platform_VMCU1_Sig" SG_ 2565822244 MaintInfo_Supported 1;
BA_ "GenSigSendType" SG_ 2565822244 MaintInfo_ResetAuthorized 1;
BA_ "GenSigStartValue" SG_ 2565822244 MaintInfo_ResetAuthorized 3;
BA_ "GenSigMaxLatency" SG_ 2565822244 MaintInfo_ResetAuthorized 107;
BA_ "Platform_VMCU1_Sig" SG_ 2565822244 MaintInfo_ResetAuthorized 1;
BA_ "GenSigSendType" SG_ 2565822244 MaintInfo_MaintOption 1;
BA_ "GenSigStartValue" SG_ 2565822244 MaintInfo_MaintOption 15;
BA_ "GenSigMaxLatency" SG_ 2565822244 MaintInfo_MaintOption 107;
BA_ "Platform_VMCU1_Sig" SG_ 2565822244 MaintInfo_MaintOption 1;
BA_ "GenSigSendType" SG_ 2565822244 MaintInfo_Data 1;
BA_ "GenSigStartValue" SG_ 2565822244 MaintInfo_Data 4294967295;
BA_ "GenSigMaxLatency" SG_ 2565822244 MaintInfo_Data 107;
BA_ "Platform_VMCU1_Sig" SG_ 2565822244 MaintInfo_Data 1;
BA_ "GenSigSendType" SG_ 2548896548 FrontAxle2Load_UB_ISig_4 7;
BA_ "Platform_VMCU1_Sig" SG_ 2548896548 FrontAxle2Load_UB_ISig_4 1;
BA_ "GenSigSendType" SG_ 2548896548 FrontAxle1Load_UB_ISig_4 7;
BA_ "Platform_VMCU1_Sig" SG_ 2548896548 FrontAxle1Load_UB_ISig_4 1;
BA_ "GenSigCycleTime" SG_ 2548896548 TransferCasePTOEngaged_ISig_4 100;
BA_ "GenSigCycleTimeActive" SG_ 2548896548 TransferCasePTOEngaged_ISig_4 100;
BA_ "GenSigStartValue" SG_ 2548896548 TransferCasePTOEngaged_ISig_4 3;
BA_ "Platform_VMCU1_Sig" SG_ 2548896548 TransferCasePTOEngaged_ISig_4 1;
BA_ "GenSigCycleTime" SG_ 2548896548 FrontAxle1Load_ISig_4 100;
BA_ "GenSigCycleTimeActive" SG_ 2548896548 FrontAxle1Load_ISig_4 100;
BA_ "GenSigStartValue" SG_ 2548896548 FrontAxle1Load_ISig_4 65535;
BA_ "NeedsUpdateBit" SG_ 2548896548 FrontAxle1Load_ISig_4 1;
BA_ "Platform_VMCU1_Sig" SG_ 2548896548 FrontAxle1Load_ISig_4 1;
BA_ "SeToolAncestorID_SIGNAL" SG_ 2548896548 FrontAxle1Load_ISig_4 "x0000001D0412EB1E";
BA_ "SeToolItemID_SIGNAL" SG_ 2548896548 FrontAxle1Load_ISig_4 "x0000001D04274C69";
BA_ "SeToolName_SIGNAL" SG_ 2548896548 FrontAxle1Load_ISig_4 "FrontAxle1Load";
BA_ "SeToolVersion_SIGNAL" SG_ 2548896548 FrontAxle1Load_ISig_4 "3";
BA_ "GenSigCycleTime" SG_ 2548896548 TransferCaseNeutral_status 100;
BA_ "GenSigCycleTimeActive" SG_ 2548896548 TransferCaseNeutral_status 100;
BA_ "GenSigStartValue" SG_ 2548896548 TransferCaseNeutral_status 3;
BA_ "Platform_VMCU1_Sig" SG_ 2548896548 TransferCaseNeutral_status 1;
BA_ "GenSigCycleTime" SG_ 2548896548 FrontAxle2Load_ISig_4 100;
BA_ "GenSigCycleTimeActive" SG_ 2548896548 FrontAxle2Load_ISig_4 100;
BA_ "GenSigStartValue" SG_ 2548896548 FrontAxle2Load_ISig_4 65535;
BA_ "NeedsUpdateBit" SG_ 2548896548 FrontAxle2Load_ISig_4 1;
BA_ "Platform_VMCU1_Sig" SG_ 2548896548 FrontAxle2Load_ISig_4 1;
BA_ "SeToolAncestorID_SIGNAL" SG_ 2548896548 FrontAxle2Load_ISig_4 "x0000001D0412EB1E";
BA_ "SeToolItemID_SIGNAL" SG_ 2548896548 FrontAxle2Load_ISig_4 "x0000001D04274C69";
BA_ "SeToolName_SIGNAL" SG_ 2548896548 FrontAxle2Load_ISig_4 "FrontAxle2Load";
BA_ "SeToolVersion_SIGNAL" SG_ 2548896548 FrontAxle2Load_ISig_4 "3";
BA_ "GenSigCycleTime" SG_ 2566891300 Driver1CumulativeBreakTime_ISig_ 100;
BA_ "GenSigCycleTimeActive" SG_ 2566891300 Driver1CumulativeBreakTime_ISig_ 100;
BA_ "GenSigStartValue" SG_ 2566891300 Driver1CumulativeBreakTime_ISig_ 65535;
BA_ "GenSigMaxLatency" SG_ 2566891300 Driver1CumulativeBreakTime_ISig_ 1054;
BA_ "Platform_VMCU1_Sig" SG_ 2566891300 Driver1CumulativeBreakTime_ISig_ 1;
BA_ "SeToolAncestorID_SIGNAL" SG_ 2566891300 Driver1CumulativeBreakTime_ISig_ "x0000001D042CB4DF";
BA_ "SeToolItemID_SIGNAL" SG_ 2566891300 Driver1CumulativeBreakTime_ISig_ "x0000001D042CB4DF";
BA_ "SeToolName_SIGNAL" SG_ 2566891300 Driver1CumulativeBreakTime_ISig_ "Driver1CumulativeBreakTime";
BA_ "SeToolVersion_SIGNAL" SG_ 2566891300 Driver1CumulativeBreakTime_ISig_ "1";
BA_ "SystemSignalLongSymbol" SG_ 2566891300 Driver1CumulativeBreakTime_ISig_ "Driver1CumulativeBreakTime_ISig_4";
BA_ "GenSigCycleTime" SG_ 2566891300 DrawerState 100;
BA_ "GenSigCycleTimeActive" SG_ 2566891300 DrawerState 100;
BA_ "GenSigStartValue" SG_ 2566891300 DrawerState 3;
BA_ "Platform_VMCU1_Sig" SG_ 2566891300 DrawerState 1;
BA_ "SeToolAncestorID_SIGNAL" SG_ 2566891300 DrawerState "x0000001D042CB4F2";
BA_ "SeToolItemID_SIGNAL" SG_ 2566891300 DrawerState "x0000001D042CB4F2";
BA_ "SeToolName_SIGNAL" SG_ 2566891300 DrawerState "DrawerState";
BA_ "SeToolVersion_SIGNAL" SG_ 2566891300 DrawerState "1";
BA_ "GenSigCycleTime" SG_ 2566891300 EndofLifeDriver1Card 100;
BA_ "GenSigCycleTimeActive" SG_ 2566891300 EndofLifeDriver1Card 100;
BA_ "GenSigStartValue" SG_ 2566891300 EndofLifeDriver1Card 3;
BA_ "Platform_VMCU1_Sig" SG_ 2566891300 EndofLifeDriver1Card 1;
BA_ "SeToolAncestorID_SIGNAL" SG_ 2566891300 EndofLifeDriver1Card "x0000001D043F3E2C";
BA_ "SeToolItemID_SIGNAL" SG_ 2566891300 EndofLifeDriver1Card "x0000001D043F3E2C";
BA_ "SeToolName_SIGNAL" SG_ 2566891300 EndofLifeDriver1Card "EndofLifeDriver1Card";
BA_ "SeToolVersion_SIGNAL" SG_ 2566891300 EndofLifeDriver1Card "1";
BA_ "GenSigCycleTime" SG_ 2566891300 Driver1ContinuousDrivingTime_ISi 100;
BA_ "GenSigCycleTimeActive" SG_ 2566891300 Driver1ContinuousDrivingTime_ISi 100;
BA_ "GenSigStartValue" SG_ 2566891300 Driver1ContinuousDrivingTime_ISi 65535;
BA_ "GenSigMaxLatency" SG_ 2566891300 Driver1ContinuousDrivingTime_ISi 1054;
BA_ "Platform_VMCU1_Sig" SG_ 2566891300 Driver1ContinuousDrivingTime_ISi 1;
BA_ "SeToolAncestorID_SIGNAL" SG_ 2566891300 Driver1ContinuousDrivingTime_ISi "x0000001D042D24E3";
BA_ "SeToolItemID_SIGNAL" SG_ 2566891300 Driver1ContinuousDrivingTime_ISi "x0000001D042D24E3";
BA_ "SeToolName_SIGNAL" SG_ 2566891300 Driver1ContinuousDrivingTime_ISi "Driver1ContinuousDrivingTime ";
BA_ "SeToolVersion_SIGNAL" SG_ 2566891300 Driver1ContinuousDrivingTime_ISi "1";
BA_ "SystemSignalLongSymbol" SG_ 2566891300 Driver1ContinuousDrivingTime_ISi "Driver1ContinuousDrivingTime_ISig_4";
BA_ "GenSigCycleTime" SG_ 2566891300 Driver1CardUnload 100;
BA_ "GenSigCycleTimeActive" SG_ 2566891300 Driver1CardUnload 100;
BA_ "GenSigStartValue" SG_ 2566891300 Driver1CardUnload 3;
BA_ "GenSigMaxLatency" SG_ 2566891300 Driver1CardUnload 1054;
BA_ "Platform_VMCU1_Sig" SG_ 2566891300 Driver1CardUnload 1;
BA_ "SeToolAncestorID_SIGNAL" SG_ 2566891300 Driver1CardUnload "x0000001D043F99B9";
BA_ "SeToolItemID_SIGNAL" SG_ 2566891300 Driver1CardUnload "x0000001D043F99B9";
BA_ "SeToolName_SIGNAL" SG_ 2566891300 Driver1CardUnload "Driver1CardUnload";
BA_ "SeToolVersion_SIGNAL" SG_ 2566891300 Driver1CardUnload "1";
BA_ "GenSigCycleTime" SG_ 2566891300 Drvr1CurDurationSelectedActy_ISi 100;
BA_ "GenSigCycleTimeActive" SG_ 2566891300 Drvr1CurDurationSelectedActy_ISi 100;
BA_ "GenSigStartValue" SG_ 2566891300 Drvr1CurDurationSelectedActy_ISi 65535;
BA_ "GenSigMaxLatency" SG_ 2566891300 Drvr1CurDurationSelectedActy_ISi 1054;
BA_ "Platform_VMCU1_Sig" SG_ 2566891300 Drvr1CurDurationSelectedActy_ISi 1;
BA_ "SeToolAncestorID_SIGNAL" SG_ 2566891300 Drvr1CurDurationSelectedActy_ISi "x0000001D042CB4EB";
BA_ "SeToolItemID_SIGNAL" SG_ 2566891300 Drvr1CurDurationSelectedActy_ISi "x0000001D042CB4EB";
BA_ "SeToolName_SIGNAL" SG_ 2566891300 Drvr1CurDurationSelectedActy_ISi "Driver1CurrentDurationOfSelectedActivity";
BA_ "SeToolVersion_SIGNAL" SG_ 2566891300 Drvr1CurDurationSelectedActy_ISi "1";
BA_ "SystemSignalLongSymbol" SG_ 2566891300 Drvr1CurDurationSelectedActy_ISi "Drvr1CurDurationSelectedActy_ISig_4";
BA_ "GenSigCycleTime" SG_ 2566490404 FuelConsumptionPTO_ISig_4 100;
BA_ "GenSigCycleTimeActive" SG_ 2566490404 FuelConsumptionPTO_ISig_4 100;
BA_ "GenSigStartValue" SG_ 2566490404 FuelConsumptionPTO_ISig_4 4294967295;
BA_ "Platform_VMCU1_Sig" SG_ 2566490404 FuelConsumptionPTO_ISig_4 1;
BA_ "GenSigCycleTime" SG_ 2566490404 AtLeastOnePTOActivationTime_ISig 100;
BA_ "GenSigCycleTimeActive" SG_ 2566490404 AtLeastOnePTOActivationTime_ISig 100;
BA_ "GenSigStartValue" SG_ 2566490404 AtLeastOnePTOActivationTime_ISig 4294967295;
BA_ "GenSigMaxLatency" SG_ 2566490404 AtLeastOnePTOActivationTime_ISig 1021;
BA_ "Platform_VMCU1_Sig" SG_ 2566490404 AtLeastOnePTOActivationTime_ISig 1;
BA_ "SystemSignalLongSymbol" SG_ 2566490404 AtLeastOnePTOActivationTime_ISig "AtLeastOnePTOActivationTime_ISig_4";
BA_ "GenSigCycleTime" SG_ 2566445860 EngineGreenAreaOutFuel_ISig_4 100;
BA_ "GenSigCycleTimeActive" SG_ 2566445860 EngineGreenAreaOutFuel_ISig_4 100;
BA_ "GenSigStartValue" SG_ 2566445860 EngineGreenAreaOutFuel_ISig_4 4294967295;
BA_ "GenSigMaxLatency" SG_ 2566445860 EngineGreenAreaOutFuel_ISig_4 1019;
BA_ "Platform_VMCU1_Sig" SG_ 2566445860 EngineGreenAreaOutFuel_ISig_4 1;
BA_ "GenSigCycleTime" SG_ 2566445860 CCTime_ISig_4 100;
BA_ "GenSigCycleTimeActive" SG_ 2566445860 CCTime_ISig_4 100;
BA_ "GenSigStartValue" SG_ 2566445860 CCTime_ISig_4 4294967295;
BA_ "GenSigMaxLatency" SG_ 2566445860 CCTime_ISig_4 1019;
BA_ "Platform_VMCU1_Sig" SG_ 2566445860 CCTime_ISig_4 1;
BA_ "GenSigCycleTime" SG_ 2566401316 MIStatusExtVMCU 100;
BA_ "GenSigCycleTimeActive" SG_ 2566401316 MIStatusExtVMCU 100;
BA_ "GenSigStartValue" SG_ 2566401316 MIStatusExtVMCU 3;
BA_ "Platform_VMCU1_Sig" SG_ 2566401316 MIStatusExtVMCU 1;
BA_ "GenSigCycleTime" SG_ 2566401316 MIDistinctWarningExtVMCU 100;
BA_ "GenSigCycleTimeActive" SG_ 2566401316 MIDistinctWarningExtVMCU 100;
BA_ "GenSigStartValue" SG_ 2566401316 MIDistinctWarningExtVMCU 15;
BA_ "Platform_VMCU1_Sig" SG_ 2566401316 MIDistinctWarningExtVMCU 1;
BA_ "GenSigCycleTime" SG_ 2566401316 EngTrueIdleSpeedFuel_ISig_4 100;
BA_ "GenSigCycleTimeActive" SG_ 2566401316 EngTrueIdleSpeedFuel_ISig_4 100;
BA_ "GenSigStartValue" SG_ 2566401316 EngTrueIdleSpeedFuel_ISig_4 4294967295;
BA_ "GenSigMaxLatency" SG_ 2566401316 EngTrueIdleSpeedFuel_ISig_4 1018;
BA_ "Platform_VMCU1_Sig" SG_ 2566401316 EngTrueIdleSpeedFuel_ISig_4 1;
BA_ "GenSigCycleTime" SG_ 2566401316 LngTotalRemainingGasVolume2 100;
BA_ "GenSigCycleTimeActive" SG_ 2566401316 LngTotalRemainingGasVolume2 100;
BA_ "GenSigStartValue" SG_ 2566401316 LngTotalRemainingGasVolume2 65535;
BA_ "Platform_VMCU1_Sig" SG_ 2566401316 LngTotalRemainingGasVolume2 1;
BA_ "GenSigCycleTime" SG_ 2566356772 FuelConsumptionVehicleStopped_IS 100;
BA_ "GenSigCycleTimeActive" SG_ 2566356772 FuelConsumptionVehicleStopped_IS 100;
BA_ "GenSigStartValue" SG_ 2566356772 FuelConsumptionVehicleStopped_IS 4294967295;
BA_ "GenSigMaxLatency" SG_ 2566356772 FuelConsumptionVehicleStopped_IS 1017;
BA_ "Platform_VMCU1_Sig" SG_ 2566356772 FuelConsumptionVehicleStopped_IS 1;
BA_ "SystemSignalLongSymbol" SG_ 2566356772 FuelConsumptionVehicleStopped_IS "FuelConsumptionVehicleStopped_ISig_4";
BA_ "GenSigCycleTime" SG_ 2566356772 FuelConsumptionVehicleRunning_IS 100;
BA_ "GenSigCycleTimeActive" SG_ 2566356772 FuelConsumptionVehicleRunning_IS 100;
BA_ "GenSigStartValue" SG_ 2566356772 FuelConsumptionVehicleRunning_IS 4294967295;
BA_ "GenSigMaxLatency" SG_ 2566356772 FuelConsumptionVehicleRunning_IS 1017;
BA_ "Platform_VMCU1_Sig" SG_ 2566356772 FuelConsumptionVehicleRunning_IS 1;
BA_ "SystemSignalLongSymbol" SG_ 2566356772 FuelConsumptionVehicleRunning_IS "FuelConsumptionVehicleRunning_ISig_4";
BA_ "GenSigCycleTime" SG_ 2566312228 AdBlueConsumptVehicleRunning_ISi 100;
BA_ "GenSigCycleTimeActive" SG_ 2566312228 AdBlueConsumptVehicleRunning_ISi 100;
BA_ "GenSigStartValue" SG_ 2566312228 AdBlueConsumptVehicleRunning_ISi 4294967295;
BA_ "GenSigMaxLatency" SG_ 2566312228 AdBlueConsumptVehicleRunning_ISi 1014;
BA_ "Platform_VMCU1_Sig" SG_ 2566312228 AdBlueConsumptVehicleRunning_ISi 1;
BA_ "SystemSignalLongSymbol" SG_ 2566312228 AdBlueConsumptVehicleRunning_ISi "AdBlueConsumptVehicleRunning_ISig_4";
BA_ "GenSigCycleTime" SG_ 2566312228 AdBlueConsumptVehicleStopped_ISi 100;
BA_ "GenSigCycleTimeActive" SG_ 2566312228 AdBlueConsumptVehicleStopped_ISi 100;
BA_ "GenSigStartValue" SG_ 2566312228 AdBlueConsumptVehicleStopped_ISi 4294967295;
BA_ "GenSigMaxLatency" SG_ 2566312228 AdBlueConsumptVehicleStopped_ISi 1014;
BA_ "Platform_VMCU1_Sig" SG_ 2566312228 AdBlueConsumptVehicleStopped_ISi 1;
BA_ "SystemSignalLongSymbol" SG_ 2566312228 AdBlueConsumptVehicleStopped_ISi "AdBlueConsumptVehicleStopped_ISig_4";
BA_REL_ "GenSigFirstTimeoutTime" BU_SG_REL_ CIOM SG_ 2548896548 TransferCasePTOEngaged_ISig_4 6000;
BA_REL_ "GenSigTimeoutTime" BU_SG_REL_ CIOM SG_ 2548896548 TransferCasePTOEngaged_ISig_4 1500;
BA_REL_ "GenSigFirstTimeoutTime" BU_SG_REL_ HMIIOM SG_ 2548896548 FrontAxle1Load_ISig_4 6000;
BA_REL_ "GenSigTimeoutTime" BU_SG_REL_ HMIIOM SG_ 2548896548 FrontAxle1Load_ISig_4 1500;
BA_REL_ "GenSigFirstTimeoutTime" BU_SG_REL_ DACU SG_ 2548896548 FrontAxle1Load_ISig_4 6000;
BA_REL_ "GenSigTimeoutTime" BU_SG_REL_ DACU SG_ 2548896548 FrontAxle1Load_ISig_4 1500;
BA_REL_ "GenSigFirstTimeoutTime" BU_SG_REL_ TECU SG_ 2548896548 FrontAxle1Load_ISig_4 6000;
BA_REL_ "GenSigTimeoutTime" BU_SG_REL_ TECU SG_ 2548896548 FrontAxle1Load_ISig_4 1500;
BA_REL_ "GenSigFirstTimeoutTime" BU_SG_REL_ BBM SG_ 2548896548 FrontAxle1Load_ISig_4 6000;
BA_REL_ "GenSigTimeoutTime" BU_SG_REL_ BBM SG_ 2548896548 FrontAxle1Load_ISig_4 1500;
BA_REL_ "GenSigFirstTimeoutTime" BU_SG_REL_ CIOM SG_ 2548896548 TransferCaseNeutral_status 6000;
BA_REL_ "GenSigTimeoutTime" BU_SG_REL_ CIOM SG_ 2548896548 TransferCaseNeutral_status 1500;
BA_REL_ "GenSigFirstTimeoutTime" BU_SG_REL_ HMIIOM SG_ 2548896548 TransferCaseNeutral_status 6000;
BA_REL_ "GenSigTimeoutTime" BU_SG_REL_ HMIIOM SG_ 2548896548 TransferCaseNeutral_status 1500;
BA_REL_ "GenSigFirstTimeoutTime" BU_SG_REL_ BBM SG_ 2548896548 TransferCaseNeutral_status 6000;
BA_REL_ "GenSigTimeoutTime" BU_SG_REL_ BBM SG_ 2548896548 TransferCaseNeutral_status 1500;
BA_REL_ "GenSigFirstTimeoutTime" BU_SG_REL_ HMIIOM SG_ 2548896548 FrontAxle2Load_ISig_4 6000;
BA_REL_ "GenSigTimeoutTime" BU_SG_REL_ HMIIOM SG_ 2548896548 FrontAxle2Load_ISig_4 1500;
BA_REL_ "GenSigFirstTimeoutTime" BU_SG_REL_ DACU SG_ 2548896548 FrontAxle2Load_ISig_4 6000;
BA_REL_ "GenSigTimeoutTime" BU_SG_REL_ DACU SG_ 2548896548 FrontAxle2Load_ISig_4 1500;
BA_REL_ "GenSigFirstTimeoutTime" BU_SG_REL_ BBM SG_ 2548896548 FrontAxle2Load_ISig_4 6000;
BA_REL_ "GenSigTimeoutTime" BU_SG_REL_ BBM SG_ 2548896548 FrontAxle2Load_ISig_4 1500;
BA_REL_ "GenSigFirstTimeoutTime" BU_SG_REL_ TECU SG_ 2548896548 FrontAxle2Load_ISig_4 6000;
BA_REL_ "GenSigTimeoutTime" BU_SG_REL_ TECU SG_ 2548896548 FrontAxle2Load_ISig_4 1500;
BA_REL_ "GenSigFirstTimeoutTime" BU_SG_REL_ HMIIOM SG_ 2566891300 Driver1CumulativeBreakTime_ISig_ 24000;
BA_REL_ "GenSigTimeoutTime" BU_SG_REL_ HMIIOM SG_ 2566891300 Driver1CumulativeBreakTime_ISig_ 6000;
BA_REL_ "GenSigFirstTimeoutTime" BU_SG_REL_ HMIIOM SG_ 2566891300 DrawerState 24000;
BA_REL_ "GenSigTimeoutTime" BU_SG_REL_ HMIIOM SG_ 2566891300 DrawerState 6000;
BA_REL_ "GenSigFirstTimeoutTime" BU_SG_REL_ HMIIOM SG_ 2566891300 EndofLifeDriver1Card 24000;
BA_REL_ "GenSigTimeoutTime" BU_SG_REL_ HMIIOM SG_ 2566891300 EndofLifeDriver1Card 6000;
BA_REL_ "GenSigFirstTimeoutTime" BU_SG_REL_ HMIIOM SG_ 2566891300 Driver1ContinuousDrivingTime_ISi 24000;
BA_REL_ "GenSigTimeoutTime" BU_SG_REL_ HMIIOM SG_ 2566891300 Driver1ContinuousDrivingTime_ISi 6000;
BA_REL_ "GenSigFirstTimeoutTime" BU_SG_REL_ HMIIOM SG_ 2566891300 Driver1CardUnload 24000;
BA_REL_ "GenSigTimeoutTime" BU_SG_REL_ HMIIOM SG_ 2566891300 Driver1CardUnload 6000;
BA_REL_ "GenSigFirstTimeoutTime" BU_SG_REL_ HMIIOM SG_ 2566891300 Drvr1CurDurationSelectedActy_ISi 24000;
BA_REL_ "GenSigTimeoutTime" BU_SG_REL_ HMIIOM SG_ 2566891300 Drvr1CurDurationSelectedActy_ISi 6000;
BA_REL_ "GenSigFirstTimeoutTime" BU_SG_REL_ HMIIOM SG_ 2566490404 FuelConsumptionPTO_ISig_4 24000;
BA_REL_ "GenSigTimeoutTime" BU_SG_REL_ HMIIOM SG_ 2566490404 FuelConsumptionPTO_ISig_4 6000;
BA_REL_ "GenSigFirstTimeoutTime" BU_SG_REL_ HMIIOM SG_ 2566490404 AtLeastOnePTOActivationTime_ISig 24000;
BA_REL_ "GenSigTimeoutTime" BU_SG_REL_ HMIIOM SG_ 2566490404 AtLeastOnePTOActivationTime_ISig 6000;
BA_REL_ "GenSigFirstTimeoutTime" BU_SG_REL_ BBM SG_ 2566490404 AtLeastOnePTOActivationTime_ISig 24000;
BA_REL_ "GenSigTimeoutTime" BU_SG_REL_ BBM SG_ 2566490404 AtLeastOnePTOActivationTime_ISig 6000;
BA_REL_ "GenSigFirstTimeoutTime" BU_SG_REL_ HMIIOM SG_ 2566445860 EngineGreenAreaOutFuel_ISig_4 24000;
BA_REL_ "GenSigTimeoutTime" BU_SG_REL_ HMIIOM SG_ 2566445860 EngineGreenAreaOutFuel_ISig_4 6000;
BA_REL_ "GenSigFirstTimeoutTime" BU_SG_REL_ HMIIOM SG_ 2566445860 CCTime_ISig_4 24000;
BA_REL_ "GenSigTimeoutTime" BU_SG_REL_ HMIIOM SG_ 2566445860 CCTime_ISig_4 6000;
BA_REL_ "GenSigFirstTimeoutTime" BU_SG_REL_ EMS SG_ 2566401316 MIStatusExtVMCU 24000;
BA_REL_ "GenSigTimeoutTime" BU_SG_REL_ EMS SG_ 2566401316 MIStatusExtVMCU 6000;
BA_REL_ "GenSigFirstTimeoutTime" BU_SG_REL_ EMS SG_ 2566401316 MIDistinctWarningExtVMCU 24000;
BA_REL_ "GenSigTimeoutTime" BU_SG_REL_ EMS SG_ 2566401316 MIDistinctWarningExtVMCU 6000;
BA_REL_ "GenSigFirstTimeoutTime" BU_SG_REL_ HMIIOM SG_ 2566401316 EngTrueIdleSpeedFuel_ISig_4 24000;
BA_REL_ "GenSigTimeoutTime" BU_SG_REL_ HMIIOM SG_ 2566401316 EngTrueIdleSpeedFuel_ISig_4 6000;
BA_REL_ "GenSigFirstTimeoutTime" BU_SG_REL_ HMIIOM SG_ 2566401316 LngTotalRemainingGasVolume2 24000;
BA_REL_ "GenSigTimeoutTime" BU_SG_REL_ HMIIOM SG_ 2566401316 LngTotalRemainingGasVolume2 6000;
BA_REL_ "GenSigFirstTimeoutTime" BU_SG_REL_ HMIIOM SG_ 2566356772 FuelConsumptionVehicleStopped_IS 24000;
BA_REL_ "GenSigTimeoutTime" BU_SG_REL_ HMIIOM SG_ 2566356772 FuelConsumptionVehicleStopped_IS 6000;
BA_REL_ "GenSigFirstTimeoutTime" BU_SG_REL_ HMIIOM SG_ 2566356772 FuelConsumptionVehicleRunning_IS 24000;
BA_REL_ "GenSigTimeoutTime" BU_SG_REL_ HMIIOM SG_ 2566356772 FuelConsumptionVehicleRunning_IS 6000;
BA_REL_ "GenSigFirstTimeoutTime" BU_SG_REL_ HMIIOM SG_ 2566312228 AdBlueConsumptVehicleRunning_ISi 24000;
BA_REL_ "GenSigTimeoutTime" BU_SG_REL_ HMIIOM SG_ 2566312228 AdBlueConsumptVehicleRunning_ISi 6000;
BA_REL_ "GenSigFirstTimeoutTime" BU_SG_REL_ HMIIOM SG_ 2566312228 AdBlueConsumptVehicleStopped_ISi 24000;
BA_REL_ "GenSigTimeoutTime" BU_SG_REL_ HMIIOM SG_ 2566312228 AdBlueConsumptVehicleStopped_ISi 6000;
VAL_ 2566560036 MaintInfoGrp_MaintOption30_ISig_ 15 "MaintOption_NotAvailable" 14 "MaintOption_Error" 13 "MaintOption_13" 12 "MaintOption_12" 11 "MaintOption_11" 10 "MaintOption_10" 9 "MaintOption_9" 8 "MaintOption_8" 7 "MaintOption_7" 6 "MaintOption_6" 5 "MaintOption_5" 4 "MaintOption_4" 3 "MaintOption_3" 2 "MaintOption_2" 1 "MaintOption_1" 0 "MaintOption_0" ;
VAL_ 2566560036 MaintInfoGrp_Unit36_ISig_4 7 "MaintenanceUnit_NotAvailable" 6 "MaintenanceUnit_Error" 5 "MaintenanceUnit_None" 4 "MaintenanceUnit_AxleNumber" 3 "MaintenanceUnit_Percentage" 2 "MaintenanceUnit_Date" 1 "MaintenanceUnit_Distance" 0 "MaintenanceUnit_EngineTime" ;
VAL_ 2566560036 MaintInfoGrp_MaintOption33_ISig_ 15 "MaintOption_NotAvailable" 14 "MaintOption_Error" 13 "MaintOption_13" 12 "MaintOption_12" 11 "MaintOption_11" 10 "MaintOption_10" 9 "MaintOption_9" 8 "MaintOption_8" 7 "MaintOption_7" 6 "MaintOption_6" 5 "MaintOption_5" 4 "MaintOption_4" 3 "MaintOption_3" 2 "MaintOption_2" 1 "MaintOption_1" 0 "MaintOption_0" ;
VAL_ 2566560036 MaintInfoGrp_ResetAuthorized32_I 3 "NoYes_NotAvailable" 2 "NoYes_Error" 1 "NoYes_Yes" 0 "NoYes_No" ;
VAL_ 2566560036 MaintInfoGrp_Status10_ISig_4 7 "MaintenanceStatus_NotAvailable" 6 "MaintenanceStatus_Error" 5 "MaintenanceStatus_Spare_01" 4 "MaintenanceStatus_InProgress" 3 "MaintenanceStatus_Spare" 2 "MaintenanceStatus_Warning" 1 "MaintenanceStatus_PreWarning" 0 "MaintenanceStatus_OK" ;
VAL_ 2566560036 MaintInfoGrp_Unit2_ISig_4 7 "MaintenanceUnit_NotAvailable" 6 "MaintenanceUnit_Error" 5 "MaintenanceUnit_None" 4 "MaintenanceUnit_AxleNumber" 3 "MaintenanceUnit_Percentage" 2 "MaintenanceUnit_Date" 1 "MaintenanceUnit_Distance" 0 "MaintenanceUnit_EngineTime" ;
VAL_ 2566560036 MaintInfoGrp_Unit14_ISig_4 7 "MaintenanceUnit_NotAvailable" 6 "MaintenanceUnit_Error" 5 "MaintenanceUnit_None" 4 "MaintenanceUnit_AxleNumber" 3 "MaintenanceUnit_Percentage" 2 "MaintenanceUnit_Date" 1 "MaintenanceUnit_Distance" 0 "MaintenanceUnit_EngineTime" ;
VAL_ 2566560036 MaintInfoGrp_ResetAuthorized28_I 3 "NoYes_NotAvailable" 2 "NoYes_Error" 1 "NoYes_Yes" 0 "NoYes_No" ;
VAL_ 2566560036 MaintInfoGrp_ResetAuthorized10_I 3 "NoYes_NotAvailable" 2 "NoYes_Error" 1 "NoYes_Yes" 0 "NoYes_No" ;
VAL_ 2566560036 MaintInfoGrp_Status31_ISig_4 7 "MaintenanceStatus_NotAvailable" 6 "MaintenanceStatus_Error" 5 "MaintenanceStatus_Spare_01" 4 "MaintenanceStatus_InProgress" 3 "MaintenanceStatus_Spare" 2 "MaintenanceStatus_Warning" 1 "MaintenanceStatus_PreWarning" 0 "MaintenanceStatus_OK" ;
VAL_ 2566560036 MaintInfoGrp_Unit32_ISig_4 7 "MaintenanceUnit_NotAvailable" 6 "MaintenanceUnit_Error" 5 "MaintenanceUnit_None" 4 "MaintenanceUnit_AxleNumber" 3 "MaintenanceUnit_Percentage" 2 "MaintenanceUnit_Date" 1 "MaintenanceUnit_Distance" 0 "MaintenanceUnit_EngineTime" ;
VAL_ 2566560036 MaintInfoGrp_Status15_ISig_4 7 "MaintenanceStatus_NotAvailable" 6 "MaintenanceStatus_Error" 5 "MaintenanceStatus_Spare_01" 4 "MaintenanceStatus_InProgress" 3 "MaintenanceStatus_Spare" 2 "MaintenanceStatus_Warning" 1 "MaintenanceStatus_PreWarning" 0 "MaintenanceStatus_OK" ;
VAL_ 2566560036 MaintInfoGrp_Supported19_ISig_4 3 "NoYes_NotAvailable" 2 "NoYes_Error" 1 "NoYes_Yes" 0 "NoYes_No" ;
VAL_ 2566560036 MaintInfoGrp_Unit34_ISig_4 7 "MaintenanceUnit_NotAvailable" 6 "MaintenanceUnit_Error" 5 "MaintenanceUnit_None" 4 "MaintenanceUnit_AxleNumber" 3 "MaintenanceUnit_Percentage" 2 "MaintenanceUnit_Date" 1 "MaintenanceUnit_Distance" 0 "MaintenanceUnit_EngineTime" ;
VAL_ 2566560036 MaintInfoGrp_Unit26_ISig_4 7 "MaintenanceUnit_NotAvailable" 6 "MaintenanceUnit_Error" 5 "MaintenanceUnit_None" 4 "MaintenanceUnit_AxleNumber" 3 "MaintenanceUnit_Percentage" 2 "MaintenanceUnit_Date" 1 "MaintenanceUnit_Distance" 0 "MaintenanceUnit_EngineTime" ;
VAL_ 2566560036 MaintInfoGrp_ResetAuthorized24_I 3 "NoYes_NotAvailable" 2 "NoYes_Error" 1 "NoYes_Yes" 0 "NoYes_No" ;
VAL_ 2566560036 MaintInfoGrp_ResetAuthorized34_I 3 "NoYes_NotAvailable" 2 "NoYes_Error" 1 "NoYes_Yes" 0 "NoYes_No" ;
VAL_ 2566560036 MaintInfoGrp_Unit28_ISig_4 7 "MaintenanceUnit_NotAvailable" 6 "MaintenanceUnit_Error" 5 "MaintenanceUnit_None" 4 "MaintenanceUnit_AxleNumber" 3 "MaintenanceUnit_Percentage" 2 "MaintenanceUnit_Date" 1 "MaintenanceUnit_Distance" 0 "MaintenanceUnit_EngineTime" ;
VAL_ 2566560036 MaintInfoGrp_Status26_ISig_4 7 "MaintenanceStatus_NotAvailable" 6 "MaintenanceStatus_Error" 5 "MaintenanceStatus_Spare_01" 4 "MaintenanceStatus_InProgress" 3 "MaintenanceStatus_Spare" 2 "MaintenanceStatus_Warning" 1 "MaintenanceStatus_PreWarning" 0 "MaintenanceStatus_OK" ;
VAL_ 2566560036 MaintInfoGrp_Unit10_ISig_4 7 "MaintenanceUnit_NotAvailable" 6 "MaintenanceUnit_Error" 5 "MaintenanceUnit_None" 4 "MaintenanceUnit_AxleNumber" 3 "MaintenanceUnit_Percentage" 2 "MaintenanceUnit_Date" 1 "MaintenanceUnit_Distance" 0 "MaintenanceUnit_EngineTime" ;
VAL_ 2566560036 MaintInfoGrp_ResetAuthorized38_I 3 "NoYes_NotAvailable" 2 "NoYes_Error" 1 "NoYes_Yes" 0 "NoYes_No" ;
VAL_ 2566560036 MaintInfoGrp_MaintOption14_ISig_ 15 "MaintOption_NotAvailable" 14 "MaintOption_Error" 13 "MaintOption_13" 12 "MaintOption_12" 11 "MaintOption_11" 10 "MaintOption_10" 9 "MaintOption_9" 8 "MaintOption_8" 7 "MaintOption_7" 6 "MaintOption_6" 5 "MaintOption_5" 4 "MaintOption_4" 3 "MaintOption_3" 2 "MaintOption_2" 1 "MaintOption_1" 0 "MaintOption_0" ;
VAL_ 2566560036 MaintInfoGrp_MaintOption17_ISig_ 15 "MaintOption_NotAvailable" 14 "MaintOption_Error" 13 "MaintOption_13" 12 "MaintOption_12" 11 "MaintOption_11" 10 "MaintOption_10" 9 "MaintOption_9" 8 "MaintOption_8" 7 "MaintOption_7" 6 "MaintOption_6" 5 "MaintOption_5" 4 "MaintOption_4" 3 "MaintOption_3" 2 "MaintOption_2" 1 "MaintOption_1" 0 "MaintOption_0" ;
VAL_ 2566560036 MaintInfoGrp_Status33_ISig_4 7 "MaintenanceStatus_NotAvailable" 6 "MaintenanceStatus_Error" 5 "MaintenanceStatus_Spare_01" 4 "MaintenanceStatus_InProgress" 3 "MaintenanceStatus_Spare" 2 "MaintenanceStatus_Warning" 1 "MaintenanceStatus_PreWarning" 0 "MaintenanceStatus_OK" ;
VAL_ 2566560036 MaintInfoGrp_Unit6_ISig_4 7 "MaintenanceUnit_NotAvailable" 6 "MaintenanceUnit_Error" 5 "MaintenanceUnit_None" 4 "MaintenanceUnit_AxleNumber" 3 "MaintenanceUnit_Percentage" 2 "MaintenanceUnit_Date" 1 "MaintenanceUnit_Distance" 0 "MaintenanceUnit_EngineTime" ;
VAL_ 2566560036 MaintInfoGrp_Supported7_ISig_4 3 "NoYes_NotAvailable" 2 "NoYes_Error" 1 "NoYes_Yes" 0 "NoYes_No" ;
VAL_ 2566560036 MaintInfoGrp_Status7_ISig_4 7 "MaintenanceStatus_NotAvailable" 6 "MaintenanceStatus_Error" 5 "MaintenanceStatus_Spare_01" 4 "MaintenanceStatus_InProgress" 3 "MaintenanceStatus_Spare" 2 "MaintenanceStatus_Warning" 1 "MaintenanceStatus_PreWarning" 0 "MaintenanceStatus_OK" ;
VAL_ 2566560036 MaintInfoGrp_ResetAuthorized2_IS 3 "NoYes_NotAvailable" 2 "NoYes_Error" 1 "NoYes_Yes" 0 "NoYes_No" ;
VAL_ 2566560036 MaintInfoGrp_MaintOption27_ISig_ 15 "MaintOption_NotAvailable" 14 "MaintOption_Error" 13 "MaintOption_13" 12 "MaintOption_12" 11 "MaintOption_11" 10 "MaintOption_10" 9 "MaintOption_9" 8 "MaintOption_8" 7 "MaintOption_7" 6 "MaintOption_6" 5 "MaintOption_5" 4 "MaintOption_4" 3 "MaintOption_3" 2 "MaintOption_2" 1 "MaintOption_1" 0 "MaintOption_0" ;
VAL_ 2566560036 MaintInfoGrp_Supported36_ISig_4 3 "NoYes_NotAvailable" 2 "NoYes_Error" 1 "NoYes_Yes" 0 "NoYes_No" ;
VAL_ 2566560036 MaintInfoGrp_Unit22_ISig_4 7 "MaintenanceUnit_NotAvailable" 6 "MaintenanceUnit_Error" 5 "MaintenanceUnit_None" 4 "MaintenanceUnit_AxleNumber" 3 "MaintenanceUnit_Percentage" 2 "MaintenanceUnit_Date" 1 "MaintenanceUnit_Distance" 0 "MaintenanceUnit_EngineTime" ;
VAL_ 2566560036 MaintInfoGrp_Unit18_ISig_4 7 "MaintenanceUnit_NotAvailable" 6 "MaintenanceUnit_Error" 5 "MaintenanceUnit_None" 4 "MaintenanceUnit_AxleNumber" 3 "MaintenanceUnit_Percentage" 2 "MaintenanceUnit_Date" 1 "MaintenanceUnit_Distance" 0 "MaintenanceUnit_EngineTime" ;
VAL_ 2566560036 MaintInfoGrp_MaintOption28_ISig_ 15 "MaintOption_NotAvailable" 14 "MaintOption_Error" 13 "MaintOption_13" 12 "MaintOption_12" 11 "MaintOption_11" 10 "MaintOption_10" 9 "MaintOption_9" 8 "MaintOption_8" 7 "MaintOption_7" 6 "MaintOption_6" 5 "MaintOption_5" 4 "MaintOption_4" 3 "MaintOption_3" 2 "MaintOption_2" 1 "MaintOption_1" 0 "MaintOption_0" ;
VAL_ 2566560036 MaintInfoGrp_Supported18_ISig_4 3 "NoYes_NotAvailable" 2 "NoYes_Error" 1 "NoYes_Yes" 0 "NoYes_No" ;
VAL_ 2566560036 MaintInfoGrp_Status22_ISig_4 7 "MaintenanceStatus_NotAvailable" 6 "MaintenanceStatus_Error" 5 "MaintenanceStatus_Spare_01" 4 "MaintenanceStatus_InProgress" 3 "MaintenanceStatus_Spare" 2 "MaintenanceStatus_Warning" 1 "MaintenanceStatus_PreWarning" 0 "MaintenanceStatus_OK" ;
VAL_ 2566560036 MaintInfoGrp_Status30_ISig_4 7 "MaintenanceStatus_NotAvailable" 6 "MaintenanceStatus_Error" 5 "MaintenanceStatus_Spare_01" 4 "MaintenanceStatus_InProgress" 3 "MaintenanceStatus_Spare" 2 "MaintenanceStatus_Warning" 1 "MaintenanceStatus_PreWarning" 0 "MaintenanceStatus_OK" ;
VAL_ 2566560036 MaintInfoGrp_Status20_ISig_4 7 "MaintenanceStatus_NotAvailable" 6 "MaintenanceStatus_Error" 5 "MaintenanceStatus_Spare_01" 4 "MaintenanceStatus_InProgress" 3 "MaintenanceStatus_Spare" 2 "MaintenanceStatus_Warning" 1 "MaintenanceStatus_PreWarning" 0 "MaintenanceStatus_OK" ;
VAL_ 2566560036 MaintInfoGrp_Status38_ISig_4 7 "MaintenanceStatus_NotAvailable" 6 "MaintenanceStatus_Error" 5 "MaintenanceStatus_Spare_01" 4 "MaintenanceStatus_InProgress" 3 "MaintenanceStatus_Spare" 2 "MaintenanceStatus_Warning" 1 "MaintenanceStatus_PreWarning" 0 "MaintenanceStatus_OK" ;
VAL_ 2566560036 MaintInfoGrp_ResetAuthorized7_IS 3 "NoYes_NotAvailable" 2 "NoYes_Error" 1 "NoYes_Yes" 0 "NoYes_No" ;
VAL_ 2566560036 MaintInfoGrp_ResetAuthorized19_I 3 "NoYes_NotAvailable" 2 "NoYes_Error" 1 "NoYes_Yes" 0 "NoYes_No" ;
VAL_ 2566560036 MaintInfoGrp_ResetAuthorized12_I 3 "NoYes_NotAvailable" 2 "NoYes_Error" 1 "NoYes_Yes" 0 "NoYes_No" ;
VAL_ 2566560036 MaintInfoGrp_MaintOption8_ISig_4 15 "MaintOption_NotAvailable" 14 "MaintOption_Error" 13 "MaintOption_13" 12 "MaintOption_12" 11 "MaintOption_11" 10 "MaintOption_10" 9 "MaintOption_9" 8 "MaintOption_8" 7 "MaintOption_7" 6 "MaintOption_6" 5 "MaintOption_5" 4 "MaintOption_4" 3 "MaintOption_3" 2 "MaintOption_2" 1 "MaintOption_1" 0 "MaintOption_0" ;
VAL_ 2566560036 MaintInfoGrp_MaintOption9_ISig_4 15 "MaintOption_NotAvailable" 14 "MaintOption_Error" 13 "MaintOption_13" 12 "MaintOption_12" 11 "MaintOption_11" 10 "MaintOption_10" 9 "MaintOption_9" 8 "MaintOption_8" 7 "MaintOption_7" 6 "MaintOption_6" 5 "MaintOption_5" 4 "MaintOption_4" 3 "MaintOption_3" 2 "MaintOption_2" 1 "MaintOption_1" 0 "MaintOption_0" ;
VAL_ 2566560036 MaintInfoGrp_ResetAuthorized13_I 3 "NoYes_NotAvailable" 2 "NoYes_Error" 1 "NoYes_Yes" 0 "NoYes_No" ;
VAL_ 2566560036 MaintInfoGrp_Unit31_ISig_4 7 "MaintenanceUnit_NotAvailable" 6 "MaintenanceUnit_Error" 5 "MaintenanceUnit_None" 4 "MaintenanceUnit_AxleNumber" 3 "MaintenanceUnit_Percentage" 2 "MaintenanceUnit_Date" 1 "MaintenanceUnit_Distance" 0 "MaintenanceUnit_EngineTime" ;
VAL_ 2566560036 MaintInfoGrp_Status2_ISig_4 7 "MaintenanceStatus_NotAvailable" 6 "MaintenanceStatus_Error" 5 "MaintenanceStatus_Spare_01" 4 "MaintenanceStatus_InProgress" 3 "MaintenanceStatus_Spare" 2 "MaintenanceStatus_Warning" 1 "MaintenanceStatus_PreWarning" 0 "MaintenanceStatus_OK" ;
VAL_ 2566560036 MaintInfoGrp_ResetAuthorized5_IS 3 "NoYes_NotAvailable" 2 "NoYes_Error" 1 "NoYes_Yes" 0 "NoYes_No" ;
VAL_ 2566560036 MaintInfoGrp_Supported33_ISig_4 3 "NoYes_NotAvailable" 2 "NoYes_Error" 1 "NoYes_Yes" 0 "NoYes_No" ;
VAL_ 2566560036 MaintInfoGrp_Unit7_ISig_4 7 "MaintenanceUnit_NotAvailable" 6 "MaintenanceUnit_Error" 5 "MaintenanceUnit_None" 4 "MaintenanceUnit_AxleNumber" 3 "MaintenanceUnit_Percentage" 2 "MaintenanceUnit_Date" 1 "MaintenanceUnit_Distance" 0 "MaintenanceUnit_EngineTime" ;
VAL_ 2566560036 MaintInfoGrp_Supported34_ISig_4 3 "NoYes_NotAvailable" 2 "NoYes_Error" 1 "NoYes_Yes" 0 "NoYes_No" ;
VAL_ 2566560036 MaintInfoGrp_Unit19_ISig_4 7 "MaintenanceUnit_NotAvailable" 6 "MaintenanceUnit_Error" 5 "MaintenanceUnit_None" 4 "MaintenanceUnit_AxleNumber" 3 "MaintenanceUnit_Percentage" 2 "MaintenanceUnit_Date" 1 "MaintenanceUnit_Distance" 0 "MaintenanceUnit_EngineTime" ;
VAL_ 2566560036 MaintInfoGrp_ResetAuthorized21_I 3 "NoYes_NotAvailable" 2 "NoYes_Error" 1 "NoYes_Yes" 0 "NoYes_No" ;
VAL_ 2566560036 MaintInfoGrp_ResetAuthorized31_I 3 "NoYes_NotAvailable" 2 "NoYes_Error" 1 "NoYes_Yes" 0 "NoYes_No" ;
VAL_ 2566560036 MaintInfoGrp_ResetAuthorized3_IS 3 "NoYes_NotAvailable" 2 "NoYes_Error" 1 "NoYes_Yes" 0 "NoYes_No" ;
VAL_ 2566560036 MaintInfoGrp_MaintOption34_ISig_ 15 "MaintOption_NotAvailable" 14 "MaintOption_Error" 13 "MaintOption_13" 12 "MaintOption_12" 11 "MaintOption_11" 10 "MaintOption_10" 9 "MaintOption_9" 8 "MaintOption_8" 7 "MaintOption_7" 6 "MaintOption_6" 5 "MaintOption_5" 4 "MaintOption_4" 3 "MaintOption_3" 2 "MaintOption_2" 1 "MaintOption_1" 0 "MaintOption_0" ;
VAL_ 2566560036 MaintInfoGrp_Status21_ISig_4 7 "MaintenanceStatus_NotAvailable" 6 "MaintenanceStatus_Error" 5 "MaintenanceStatus_Spare_01" 4 "MaintenanceStatus_InProgress" 3 "MaintenanceStatus_Spare" 2 "MaintenanceStatus_Warning" 1 "MaintenanceStatus_PreWarning" 0 "MaintenanceStatus_OK" ;
VAL_ 2566560036 MaintInfoGrp_Unit21_ISig_4 7 "MaintenanceUnit_NotAvailable" 6 "MaintenanceUnit_Error" 5 "MaintenanceUnit_None" 4 "MaintenanceUnit_AxleNumber" 3 "MaintenanceUnit_Percentage" 2 "MaintenanceUnit_Date" 1 "MaintenanceUnit_Distance" 0 "MaintenanceUnit_EngineTime" ;
VAL_ 2566560036 MaintInfoGrp_MaintOption24_ISig_ 15 "MaintOption_NotAvailable" 14 "MaintOption_Error" 13 "MaintOption_13" 12 "MaintOption_12" 11 "MaintOption_11" 10 "MaintOption_10" 9 "MaintOption_9" 8 "MaintOption_8" 7 "MaintOption_7" 6 "MaintOption_6" 5 "MaintOption_5" 4 "MaintOption_4" 3 "MaintOption_3" 2 "MaintOption_2" 1 "MaintOption_1" 0 "MaintOption_0" ;
VAL_ 2566560036 MaintInfoGrp_Supported17_ISig_4 3 "NoYes_NotAvailable" 2 "NoYes_Error" 1 "NoYes_Yes" 0 "NoYes_No" ;
VAL_ 2566560036 MaintInfoGrp_ResetAuthorized17_I 3 "NoYes_NotAvailable" 2 "NoYes_Error" 1 "NoYes_Yes" 0 "NoYes_No" ;
VAL_ 2566560036 MaintInfoGrp_Unit25_ISig_4 7 "MaintenanceUnit_NotAvailable" 6 "MaintenanceUnit_Error" 5 "MaintenanceUnit_None" 4 "MaintenanceUnit_AxleNumber" 3 "MaintenanceUnit_Percentage" 2 "MaintenanceUnit_Date" 1 "MaintenanceUnit_Distance" 0 "MaintenanceUnit_EngineTime" ;
VAL_ 2566560036 MaintInfoGrp_Unit37_ISig_4 7 "MaintenanceUnit_NotAvailable" 6 "MaintenanceUnit_Error" 5 "MaintenanceUnit_None" 4 "MaintenanceUnit_AxleNumber" 3 "MaintenanceUnit_Percentage" 2 "MaintenanceUnit_Date" 1 "MaintenanceUnit_Distance" 0 "MaintenanceUnit_EngineTime" ;
VAL_ 2566560036 MaintInfoGrp_MaintOption2_ISig_4 15 "MaintOption_NotAvailable" 14 "MaintOption_Error" 13 "MaintOption_13" 12 "MaintOption_12" 11 "MaintOption_11" 10 "MaintOption_10" 9 "MaintOption_9" 8 "MaintOption_8" 7 "MaintOption_7" 6 "MaintOption_6" 5 "MaintOption_5" 4 "MaintOption_4" 3 "MaintOption_3" 2 "MaintOption_2" 1 "MaintOption_1" 0 "MaintOption_0" ;
VAL_ 2566560036 MaintInfoGrp_Supported21_ISig_4 3 "NoYes_NotAvailable" 2 "NoYes_Error" 1 "NoYes_Yes" 0 "NoYes_No" ;
VAL_ 2566560036 MaintInfoGrp_ResetAuthorized16_I 3 "NoYes_NotAvailable" 2 "NoYes_Error" 1 "NoYes_Yes" 0 "NoYes_No" ;
VAL_ 2566560036 MaintInfoGrp_Supported15_ISig_4 3 "NoYes_NotAvailable" 2 "NoYes_Error" 1 "NoYes_Yes" 0 "NoYes_No" ;
VAL_ 2566560036 MaintInfoGrp_ResetAuthorized9_IS 3 "NoYes_NotAvailable" 2 "NoYes_Error" 1 "NoYes_Yes" 0 "NoYes_No" ;
VAL_ 2566560036 MaintInfoGrp_MaintOption18_ISig_ 15 "MaintOption_NotAvailable" 14 "MaintOption_Error" 13 "MaintOption_13" 12 "MaintOption_12" 11 "MaintOption_11" 10 "MaintOption_10" 9 "MaintOption_9" 8 "MaintOption_8" 7 "MaintOption_7" 6 "MaintOption_6" 5 "MaintOption_5" 4 "MaintOption_4" 3 "MaintOption_3" 2 "MaintOption_2" 1 "MaintOption_1" 0 "MaintOption_0" ;
VAL_ 2566560036 MaintInfoGrp_Supported29_ISig_4 3 "NoYes_NotAvailable" 2 "NoYes_Error" 1 "NoYes_Yes" 0 "NoYes_No" ;
VAL_ 2566560036 MaintInfoGrp_ResetAuthorized39_I 3 "NoYes_NotAvailable" 2 "NoYes_Error" 1 "NoYes_Yes" 0 "NoYes_No" ;
VAL_ 2566560036 MaintInfoGrp_Supported32_ISig_4 3 "NoYes_NotAvailable" 2 "NoYes_Error" 1 "NoYes_Yes" 0 "NoYes_No" ;
VAL_ 2566560036 MaintInfoGrp_ResetAuthorized35_I 3 "NoYes_NotAvailable" 2 "NoYes_Error" 1 "NoYes_Yes" 0 "NoYes_No" ;
VAL_ 2566560036 MaintInfoGrp_ResetAuthorized29_I 3 "NoYes_NotAvailable" 2 "NoYes_Error" 1 "NoYes_Yes" 0 "NoYes_No" ;
VAL_ 2566560036 MaintInfoGrp_Supported35_ISig_4 3 "NoYes_NotAvailable" 2 "NoYes_Error" 1 "NoYes_Yes" 0 "NoYes_No" ;
VAL_ 2566560036 MaintInfoGrp_ResetAuthorized4_IS 3 "NoYes_NotAvailable" 2 "NoYes_Error" 1 "NoYes_Yes" 0 "NoYes_No" ;
VAL_ 2566560036 MaintInfoGrp_Unit1_ISig_4 7 "MaintenanceUnit_NotAvailable" 6 "MaintenanceUnit_Error" 5 "MaintenanceUnit_None" 4 "MaintenanceUnit_AxleNumber" 3 "MaintenanceUnit_Percentage" 2 "MaintenanceUnit_Date" 1 "MaintenanceUnit_Distance" 0 "MaintenanceUnit_EngineTime" ;
VAL_ 2566560036 MaintInfoGrp_MaintOption7_ISig_4 15 "MaintOption_NotAvailable" 14 "MaintOption_Error" 13 "MaintOption_13" 12 "MaintOption_12" 11 "MaintOption_11" 10 "MaintOption_10" 9 "MaintOption_9" 8 "MaintOption_8" 7 "MaintOption_7" 6 "MaintOption_6" 5 "MaintOption_5" 4 "MaintOption_4" 3 "MaintOption_3" 2 "MaintOption_2" 1 "MaintOption_1" 0 "MaintOption_0" ;
VAL_ 2566560036 MaintInfoGrp_Supported24_ISig_4 3 "NoYes_NotAvailable" 2 "NoYes_Error" 1 "NoYes_Yes" 0 "NoYes_No" ;
VAL_ 2566560036 MaintInfoGrp_Supported25_ISig_4 3 "NoYes_NotAvailable" 2 "NoYes_Error" 1 "NoYes_Yes" 0 "NoYes_No" ;
VAL_ 2566560036 MaintInfoGrp_Unit15_ISig_4 7 "MaintenanceUnit_NotAvailable" 6 "MaintenanceUnit_Error" 5 "MaintenanceUnit_None" 4 "MaintenanceUnit_AxleNumber" 3 "MaintenanceUnit_Percentage" 2 "MaintenanceUnit_Date" 1 "MaintenanceUnit_Distance" 0 "MaintenanceUnit_EngineTime" ;
VAL_ 2566560036 MaintInfoGrp_Supported1_ISig_4 3 "NoYes_NotAvailable" 2 "NoYes_Error" 1 "NoYes_Yes" 0 "NoYes_No" ;
VAL_ 2566560036 MaintInfoGrp_ResetAuthorized11_I 3 "NoYes_NotAvailable" 2 "NoYes_Error" 1 "NoYes_Yes" 0 "NoYes_No" ;
VAL_ 2566560036 MaintInfoGrp_Supported13_ISig_4 3 "NoYes_NotAvailable" 2 "NoYes_Error" 1 "NoYes_Yes" 0 "NoYes_No" ;
VAL_ 2566560036 MaintInfoGrp_Supported10_ISig_4 3 "NoYes_NotAvailable" 2 "NoYes_Error" 1 "NoYes_Yes" 0 "NoYes_No" ;
VAL_ 2566560036 MaintInfoGrp_Unit16_ISig_4 7 "MaintenanceUnit_NotAvailable" 6 "MaintenanceUnit_Error" 5 "MaintenanceUnit_None" 4 "MaintenanceUnit_AxleNumber" 3 "MaintenanceUnit_Percentage" 2 "MaintenanceUnit_Date" 1 "MaintenanceUnit_Distance" 0 "MaintenanceUnit_EngineTime" ;
VAL_ 2566560036 MaintInfoGrp_MaintOption35_ISig_ 15 "MaintOption_NotAvailable" 14 "MaintOption_Error" 13 "MaintOption_13" 12 "MaintOption_12" 11 "MaintOption_11" 10 "MaintOption_10" 9 "MaintOption_9" 8 "MaintOption_8" 7 "MaintOption_7" 6 "MaintOption_6" 5 "MaintOption_5" 4 "MaintOption_4" 3 "MaintOption_3" 2 "MaintOption_2" 1 "MaintOption_1" 0 "MaintOption_0" ;
VAL_ 2566560036 MaintInfoGrp_MaintOption22_ISig_ 15 "MaintOption_NotAvailable" 14 "MaintOption_Error" 13 "MaintOption_13" 12 "MaintOption_12" 11 "MaintOption_11" 10 "MaintOption_10" 9 "MaintOption_9" 8 "MaintOption_8" 7 "MaintOption_7" 6 "MaintOption_6" 5 "MaintOption_5" 4 "MaintOption_4" 3 "MaintOption_3" 2 "MaintOption_2" 1 "MaintOption_1" 0 "MaintOption_0" ;
VAL_ 2566560036 MaintInfoGrp_MaintOption12_ISig_ 15 "MaintOption_NotAvailable" 14 "MaintOption_Error" 13 "MaintOption_13" 12 "MaintOption_12" 11 "MaintOption_11" 10 "MaintOption_10" 9 "MaintOption_9" 8 "MaintOption_8" 7 "MaintOption_7" 6 "MaintOption_6" 5 "MaintOption_5" 4 "MaintOption_4" 3 "MaintOption_3" 2 "MaintOption_2" 1 "MaintOption_1" 0 "MaintOption_0" ;
VAL_ 2566560036 MaintInfoGrp_Supported9_ISig_4 3 "NoYes_NotAvailable" 2 "NoYes_Error" 1 "NoYes_Yes" 0 "NoYes_No" ;
VAL_ 2566560036 MaintInfoGrp_Supported31_ISig_4 3 "NoYes_NotAvailable" 2 "NoYes_Error" 1 "NoYes_Yes" 0 "NoYes_No" ;
VAL_ 2566560036 MaintInfoGrp_MaintOption37_ISig_ 15 "MaintOption_NotAvailable" 14 "MaintOption_Error" 13 "MaintOption_13" 12 "MaintOption_12" 11 "MaintOption_11" 10 "MaintOption_10" 9 "MaintOption_9" 8 "MaintOption_8" 7 "MaintOption_7" 6 "MaintOption_6" 5 "MaintOption_5" 4 "MaintOption_4" 3 "MaintOption_3" 2 "MaintOption_2" 1 "MaintOption_1" 0 "MaintOption_0" ;
VAL_ 2566560036 MaintInfoGrp_MaintOption13_ISig_ 15 "MaintOption_NotAvailable" 14 "MaintOption_Error" 13 "MaintOption_13" 12 "MaintOption_12" 11 "MaintOption_11" 10 "MaintOption_10" 9 "MaintOption_9" 8 "MaintOption_8" 7 "MaintOption_7" 6 "MaintOption_6" 5 "MaintOption_5" 4 "MaintOption_4" 3 "MaintOption_3" 2 "MaintOption_2" 1 "MaintOption_1" 0 "MaintOption_0" ;
VAL_ 2566560036 MaintInfoGrp_ResetAuthorized22_I 3 "NoYes_NotAvailable" 2 "NoYes_Error" 1 "NoYes_Yes" 0 "NoYes_No" ;
VAL_ 2566560036 MaintInfoGrp_Status14_ISig_4 7 "MaintenanceStatus_NotAvailable" 6 "MaintenanceStatus_Error" 5 "MaintenanceStatus_Spare_01" 4 "MaintenanceStatus_InProgress" 3 "MaintenanceStatus_Spare" 2 "MaintenanceStatus_Warning" 1 "MaintenanceStatus_PreWarning" 0 "MaintenanceStatus_OK" ;
VAL_ 2566560036 MaintInfoGrp_Status18_ISig_4 7 "MaintenanceStatus_NotAvailable" 6 "MaintenanceStatus_Error" 5 "MaintenanceStatus_Spare_01" 4 "MaintenanceStatus_InProgress" 3 "MaintenanceStatus_Spare" 2 "MaintenanceStatus_Warning" 1 "MaintenanceStatus_PreWarning" 0 "MaintenanceStatus_OK" ;
VAL_ 2566560036 MaintInfoGrp_Unit17_ISig_4 7 "MaintenanceUnit_NotAvailable" 6 "MaintenanceUnit_Error" 5 "MaintenanceUnit_None" 4 "MaintenanceUnit_AxleNumber" 3 "MaintenanceUnit_Percentage" 2 "MaintenanceUnit_Date" 1 "MaintenanceUnit_Distance" 0 "MaintenanceUnit_EngineTime" ;
VAL_ 2566560036 MaintInfoGrp_Unit12_ISig_4 7 "MaintenanceUnit_NotAvailable" 6 "MaintenanceUnit_Error" 5 "MaintenanceUnit_None" 4 "MaintenanceUnit_AxleNumber" 3 "MaintenanceUnit_Percentage" 2 "MaintenanceUnit_Date" 1 "MaintenanceUnit_Distance" 0 "MaintenanceUnit_EngineTime" ;
VAL_ 2566560036 MaintInfoGrp_Supported27_ISig_4 3 "NoYes_NotAvailable" 2 "NoYes_Error" 1 "NoYes_Yes" 0 "NoYes_No" ;
VAL_ 2566560036 MaintInfoGrp_Unit4_ISig_4 7 "MaintenanceUnit_NotAvailable" 6 "MaintenanceUnit_Error" 5 "MaintenanceUnit_None" 4 "MaintenanceUnit_AxleNumber" 3 "MaintenanceUnit_Percentage" 2 "MaintenanceUnit_Date" 1 "MaintenanceUnit_Distance" 0 "MaintenanceUnit_EngineTime" ;
VAL_ 2566560036 MaintInfoGrp_Status27_ISig_4 7 "MaintenanceStatus_NotAvailable" 6 "MaintenanceStatus_Error" 5 "MaintenanceStatus_Spare_01" 4 "MaintenanceStatus_InProgress" 3 "MaintenanceStatus_Spare" 2 "MaintenanceStatus_Warning" 1 "MaintenanceStatus_PreWarning" 0 "MaintenanceStatus_OK" ;
VAL_ 2566560036 MaintInfoGrp_MaintOption29_ISig_ 15 "MaintOption_NotAvailable" 14 "MaintOption_Error" 13 "MaintOption_13" 12 "MaintOption_12" 11 "MaintOption_11" 10 "MaintOption_10" 9 "MaintOption_9" 8 "MaintOption_8" 7 "MaintOption_7" 6 "MaintOption_6" 5 "MaintOption_5" 4 "MaintOption_4" 3 "MaintOption_3" 2 "MaintOption_2" 1 "MaintOption_1" 0 "MaintOption_0" ;
VAL_ 2566560036 MaintInfoGrp_Unit9_ISig_4 7 "MaintenanceUnit_NotAvailable" 6 "MaintenanceUnit_Error" 5 "MaintenanceUnit_None" 4 "MaintenanceUnit_AxleNumber" 3 "MaintenanceUnit_Percentage" 2 "MaintenanceUnit_Date" 1 "MaintenanceUnit_Distance" 0 "MaintenanceUnit_EngineTime" ;
VAL_ 2566560036 MaintInfoGrp_Unit13_ISig_4 7 "MaintenanceUnit_NotAvailable" 6 "MaintenanceUnit_Error" 5 "MaintenanceUnit_None" 4 "MaintenanceUnit_AxleNumber" 3 "MaintenanceUnit_Percentage" 2 "MaintenanceUnit_Date" 1 "MaintenanceUnit_Distance" 0 "MaintenanceUnit_EngineTime" ;
VAL_ 2566560036 MaintInfoGrp_Unit3_ISig_4 7 "MaintenanceUnit_NotAvailable" 6 "MaintenanceUnit_Error" 5 "MaintenanceUnit_None" 4 "MaintenanceUnit_AxleNumber" 3 "MaintenanceUnit_Percentage" 2 "MaintenanceUnit_Date" 1 "MaintenanceUnit_Distance" 0 "MaintenanceUnit_EngineTime" ;
VAL_ 2566560036 MaintInfoGrp_MaintOption15_ISig_ 15 "MaintOption_NotAvailable" 14 "MaintOption_Error" 13 "MaintOption_13" 12 "MaintOption_12" 11 "MaintOption_11" 10 "MaintOption_10" 9 "MaintOption_9" 8 "MaintOption_8" 7 "MaintOption_7" 6 "MaintOption_6" 5 "MaintOption_5" 4 "MaintOption_4" 3 "MaintOption_3" 2 "MaintOption_2" 1 "MaintOption_1" 0 "MaintOption_0" ;
VAL_ 2566560036 MaintInfoGrp_ResetAuthorized15_I 3 "NoYes_NotAvailable" 2 "NoYes_Error" 1 "NoYes_Yes" 0 "NoYes_No" ;
VAL_ 2566560036 MaintInfoGrp_MaintOption11_ISig_ 15 "MaintOption_NotAvailable" 14 "MaintOption_Error" 13 "MaintOption_13" 12 "MaintOption_12" 11 "MaintOption_11" 10 "MaintOption_10" 9 "MaintOption_9" 8 "MaintOption_8" 7 "MaintOption_7" 6 "MaintOption_6" 5 "MaintOption_5" 4 "MaintOption_4" 3 "MaintOption_3" 2 "MaintOption_2" 1 "MaintOption_1" 0 "MaintOption_0" ;
VAL_ 2566560036 MaintInfoGrp_MaintOption25_ISig_ 15 "MaintOption_NotAvailable" 14 "MaintOption_Error" 13 "MaintOption_13" 12 "MaintOption_12" 11 "MaintOption_11" 10 "MaintOption_10" 9 "MaintOption_9" 8 "MaintOption_8" 7 "MaintOption_7" 6 "MaintOption_6" 5 "MaintOption_5" 4 "MaintOption_4" 3 "MaintOption_3" 2 "MaintOption_2" 1 "MaintOption_1" 0 "MaintOption_0" ;
VAL_ 2566560036 MaintInfoGrp_Supported16_ISig_4 3 "NoYes_NotAvailable" 2 "NoYes_Error" 1 "NoYes_Yes" 0 "NoYes_No" ;
VAL_ 2566560036 MaintInfoGrp_Supported23_ISig_4 3 "NoYes_NotAvailable" 2 "NoYes_Error" 1 "NoYes_Yes" 0 "NoYes_No" ;
VAL_ 2566560036 MaintInfoGrp_Status13_ISig_4 7 "MaintenanceStatus_NotAvailable" 6 "MaintenanceStatus_Error" 5 "MaintenanceStatus_Spare_01" 4 "MaintenanceStatus_InProgress" 3 "MaintenanceStatus_Spare" 2 "MaintenanceStatus_Warning" 1 "MaintenanceStatus_PreWarning" 0 "MaintenanceStatus_OK" ;
VAL_ 2566560036 MaintInfoGrp_Status17_ISig_4 7 "MaintenanceStatus_NotAvailable" 6 "MaintenanceStatus_Error" 5 "MaintenanceStatus_Spare_01" 4 "MaintenanceStatus_InProgress" 3 "MaintenanceStatus_Spare" 2 "MaintenanceStatus_Warning" 1 "MaintenanceStatus_PreWarning" 0 "MaintenanceStatus_OK" ;
VAL_ 2566560036 MaintInfoGrp_Unit8_ISig_4 7 "MaintenanceUnit_NotAvailable" 6 "MaintenanceUnit_Error" 5 "MaintenanceUnit_None" 4 "MaintenanceUnit_AxleNumber" 3 "MaintenanceUnit_Percentage" 2 "MaintenanceUnit_Date" 1 "MaintenanceUnit_Distance" 0 "MaintenanceUnit_EngineTime" ;
VAL_ 2566560036 MaintInfoGrp_MaintOption38_ISig_ 15 "MaintOption_NotAvailable" 14 "MaintOption_Error" 13 "MaintOption_13" 12 "MaintOption_12" 11 "MaintOption_11" 10 "MaintOption_10" 9 "MaintOption_9" 8 "MaintOption_8" 7 "MaintOption_7" 6 "MaintOption_6" 5 "MaintOption_5" 4 "MaintOption_4" 3 "MaintOption_3" 2 "MaintOption_2" 1 "MaintOption_1" 0 "MaintOption_0" ;
VAL_ 2566560036 MaintInfoGrp_Supported2_ISig_4 3 "NoYes_NotAvailable" 2 "NoYes_Error" 1 "NoYes_Yes" 0 "NoYes_No" ;
VAL_ 2566560036 MaintInfoGrp_ResetAuthorized0_IS 3 "NoYes_NotAvailable" 2 "NoYes_Error" 1 "NoYes_Yes" 0 "NoYes_No" ;
VAL_ 2566560036 MaintInfoGrp_Supported5_ISig_4 3 "NoYes_NotAvailable" 2 "NoYes_Error" 1 "NoYes_Yes" 0 "NoYes_No" ;
VAL_ 2566560036 MaintInfoGrp_Status6_ISig_4 7 "MaintenanceStatus_NotAvailable" 6 "MaintenanceStatus_Error" 5 "MaintenanceStatus_Spare_01" 4 "MaintenanceStatus_InProgress" 3 "MaintenanceStatus_Spare" 2 "MaintenanceStatus_Warning" 1 "MaintenanceStatus_PreWarning" 0 "MaintenanceStatus_OK" ;
VAL_ 2566560036 MaintInfoGrp_Unit5_ISig_4 7 "MaintenanceUnit_NotAvailable" 6 "MaintenanceUnit_Error" 5 "MaintenanceUnit_None" 4 "MaintenanceUnit_AxleNumber" 3 "MaintenanceUnit_Percentage" 2 "MaintenanceUnit_Date" 1 "MaintenanceUnit_Distance" 0 "MaintenanceUnit_EngineTime" ;
VAL_ 2566560036 MaintInfoGrp_Supported28_ISig_4 3 "NoYes_NotAvailable" 2 "NoYes_Error" 1 "NoYes_Yes" 0 "NoYes_No" ;
VAL_ 2566560036 MaintInfoGrp_Status32_ISig_4 7 "MaintenanceStatus_NotAvailable" 6 "MaintenanceStatus_Error" 5 "MaintenanceStatus_Spare_01" 4 "MaintenanceStatus_InProgress" 3 "MaintenanceStatus_Spare" 2 "MaintenanceStatus_Warning" 1 "MaintenanceStatus_PreWarning" 0 "MaintenanceStatus_OK" ;
VAL_ 2566560036 MaintInfoGrp_MaintOption0_ISig_4 15 "MaintOption_NotAvailable" 14 "MaintOption_Error" 13 "MaintOption_13" 12 "MaintOption_12" 11 "MaintOption_11" 10 "MaintOption_10" 9 "MaintOption_9" 8 "MaintOption_8" 7 "MaintOption_7" 6 "MaintOption_6" 5 "MaintOption_5" 4 "MaintOption_4" 3 "MaintOption_3" 2 "MaintOption_2" 1 "MaintOption_1" 0 "MaintOption_0" ;
VAL_ 2566560036 MaintInfoGrp_ResetAuthorized25_I 3 "NoYes_NotAvailable" 2 "NoYes_Error" 1 "NoYes_Yes" 0 "NoYes_No" ;
VAL_ 2566560036 MaintInfoGrp_MaintOption32_ISig_ 15 "MaintOption_NotAvailable" 14 "MaintOption_Error" 13 "MaintOption_13" 12 "MaintOption_12" 11 "MaintOption_11" 10 "MaintOption_10" 9 "MaintOption_9" 8 "MaintOption_8" 7 "MaintOption_7" 6 "MaintOption_6" 5 "MaintOption_5" 4 "MaintOption_4" 3 "MaintOption_3" 2 "MaintOption_2" 1 "MaintOption_1" 0 "MaintOption_0" ;
VAL_ 2566560036 MaintInfoGrp_Unit11_ISig_4 7 "MaintenanceUnit_NotAvailable" 6 "MaintenanceUnit_Error" 5 "MaintenanceUnit_None" 4 "MaintenanceUnit_AxleNumber" 3 "MaintenanceUnit_Percentage" 2 "MaintenanceUnit_Date" 1 "MaintenanceUnit_Distance" 0 "MaintenanceUnit_EngineTime" ;
VAL_ 2566560036 MaintInfoGrp_MaintOption4_ISig_4 15 "MaintOption_NotAvailable" 14 "MaintOption_Error" 13 "MaintOption_13" 12 "MaintOption_12" 11 "MaintOption_11" 10 "MaintOption_10" 9 "MaintOption_9" 8 "MaintOption_8" 7 "MaintOption_7" 6 "MaintOption_6" 5 "MaintOption_5" 4 "MaintOption_4" 3 "MaintOption_3" 2 "MaintOption_2" 1 "MaintOption_1" 0 "MaintOption_0" ;
VAL_ 2566560036 MaintInfoGrp_Supported38_ISig_4 3 "NoYes_NotAvailable" 2 "NoYes_Error" 1 "NoYes_Yes" 0 "NoYes_No" ;
VAL_ 2566560036 MaintInfoGrp_MaintOption1_ISig_4 15 "MaintOption_NotAvailable" 14 "MaintOption_Error" 13 "MaintOption_13" 12 "MaintOption_12" 11 "MaintOption_11" 10 "MaintOption_10" 9 "MaintOption_9" 8 "MaintOption_8" 7 "MaintOption_7" 6 "MaintOption_6" 5 "MaintOption_5" 4 "MaintOption_4" 3 "MaintOption_3" 2 "MaintOption_2" 1 "MaintOption_1" 0 "MaintOption_0" ;
VAL_ 2566560036 MaintInfoGrp_Supported30_ISig_4 3 "NoYes_NotAvailable" 2 "NoYes_Error" 1 "NoYes_Yes" 0 "NoYes_No" ;
VAL_ 2566560036 MaintInfoGrp_ResetAuthorized33_I 3 "NoYes_NotAvailable" 2 "NoYes_Error" 1 "NoYes_Yes" 0 "NoYes_No" ;
VAL_ 2566560036 MaintInfoGrp_Status0_ISig_4 7 "MaintenanceStatus_NotAvailable" 6 "MaintenanceStatus_Error" 5 "MaintenanceStatus_Spare_01" 4 "MaintenanceStatus_InProgress" 3 "MaintenanceStatus_Spare" 2 "MaintenanceStatus_Warning" 1 "MaintenanceStatus_PreWarning" 0 "MaintenanceStatus_OK" ;
VAL_ 2566560036 MaintInfoGrp_ResetAuthorized20_I 3 "NoYes_NotAvailable" 2 "NoYes_Error" 1 "NoYes_Yes" 0 "NoYes_No" ;
VAL_ 2566560036 MaintInfoGrp_Unit33_ISig_4 7 "MaintenanceUnit_NotAvailable" 6 "MaintenanceUnit_Error" 5 "MaintenanceUnit_None" 4 "MaintenanceUnit_AxleNumber" 3 "MaintenanceUnit_Percentage" 2 "MaintenanceUnit_Date" 1 "MaintenanceUnit_Distance" 0 "MaintenanceUnit_EngineTime" ;
VAL_ 2566560036 MaintInfoGrp_Supported26_ISig_4 3 "NoYes_NotAvailable" 2 "NoYes_Error" 1 "NoYes_Yes" 0 "NoYes_No" ;
VAL_ 2566560036 MaintInfoGrp_ResetAuthorized6_IS 3 "NoYes_NotAvailable" 2 "NoYes_Error" 1 "NoYes_Yes" 0 "NoYes_No" ;
VAL_ 2566560036 MaintInfoGrp_Status16_ISig_4 7 "MaintenanceStatus_NotAvailable" 6 "MaintenanceStatus_Error" 5 "MaintenanceStatus_Spare_01" 4 "MaintenanceStatus_InProgress" 3 "MaintenanceStatus_Spare" 2 "MaintenanceStatus_Warning" 1 "MaintenanceStatus_PreWarning" 0 "MaintenanceStatus_OK" ;
VAL_ 2566560036 MaintInfoGrp_ResetAuthorized18_I 3 "NoYes_NotAvailable" 2 "NoYes_Error" 1 "NoYes_Yes" 0 "NoYes_No" ;
VAL_ 2566560036 MaintInfoGrp_Status4_ISig_4 7 "MaintenanceStatus_NotAvailable" 6 "MaintenanceStatus_Error" 5 "MaintenanceStatus_Spare_01" 4 "MaintenanceStatus_InProgress" 3 "MaintenanceStatus_Spare" 2 "MaintenanceStatus_Warning" 1 "MaintenanceStatus_PreWarning" 0 "MaintenanceStatus_OK" ;
VAL_ 2566560036 MaintInfoGrp_MaintOption20_ISig_ 15 "MaintOption_NotAvailable" 14 "MaintOption_Error" 13 "MaintOption_13" 12 "MaintOption_12" 11 "MaintOption_11" 10 "MaintOption_10" 9 "MaintOption_9" 8 "MaintOption_8" 7 "MaintOption_7" 6 "MaintOption_6" 5 "MaintOption_5" 4 "MaintOption_4" 3 "MaintOption_3" 2 "MaintOption_2" 1 "MaintOption_1" 0 "MaintOption_0" ;
VAL_ 2566560036 MaintInfoGrp_ResetAuthorized30_I 3 "NoYes_NotAvailable" 2 "NoYes_Error" 1 "NoYes_Yes" 0 "NoYes_No" ;
VAL_ 2566560036 MaintInfoGrp_ResetAuthorized23_I 3 "NoYes_NotAvailable" 2 "NoYes_Error" 1 "NoYes_Yes" 0 "NoYes_No" ;
VAL_ 2566560036 MaintInfoGrp_Unit30_ISig_4 7 "MaintenanceUnit_NotAvailable" 6 "MaintenanceUnit_Error" 5 "MaintenanceUnit_None" 4 "MaintenanceUnit_AxleNumber" 3 "MaintenanceUnit_Percentage" 2 "MaintenanceUnit_Date" 1 "MaintenanceUnit_Distance" 0 "MaintenanceUnit_EngineTime" ;
VAL_ 2566560036 MaintInfoGrp_MaintOption23_ISig_ 15 "MaintOption_NotAvailable" 14 "MaintOption_Error" 13 "MaintOption_13" 12 "MaintOption_12" 11 "MaintOption_11" 10 "MaintOption_10" 9 "MaintOption_9" 8 "MaintOption_8" 7 "MaintOption_7" 6 "MaintOption_6" 5 "MaintOption_5" 4 "MaintOption_4" 3 "MaintOption_3" 2 "MaintOption_2" 1 "MaintOption_1" 0 "MaintOption_0" ;
VAL_ 2566560036 MaintInfoGrp_Unit20_ISig_4 7 "MaintenanceUnit_NotAvailable" 6 "MaintenanceUnit_Error" 5 "MaintenanceUnit_None" 4 "MaintenanceUnit_AxleNumber" 3 "MaintenanceUnit_Percentage" 2 "MaintenanceUnit_Date" 1 "MaintenanceUnit_Distance" 0 "MaintenanceUnit_EngineTime" ;
VAL_ 2566560036 MaintInfoGrp_MaintOption10_ISig_ 15 "MaintOption_NotAvailable" 14 "MaintOption_Error" 13 "MaintOption_13" 12 "MaintOption_12" 11 "MaintOption_11" 10 "MaintOption_10" 9 "MaintOption_9" 8 "MaintOption_8" 7 "MaintOption_7" 6 "MaintOption_6" 5 "MaintOption_5" 4 "MaintOption_4" 3 "MaintOption_3" 2 "MaintOption_2" 1 "MaintOption_1" 0 "MaintOption_0" ;
VAL_ 2566560036 MaintInfoGrp_Status39_ISig_4 7 "MaintenanceStatus_NotAvailable" 6 "MaintenanceStatus_Error" 5 "MaintenanceStatus_Spare_01" 4 "MaintenanceStatus_InProgress" 3 "MaintenanceStatus_Spare" 2 "MaintenanceStatus_Warning" 1 "MaintenanceStatus_PreWarning" 0 "MaintenanceStatus_OK" ;
VAL_ 2566560036 MaintInfoGrp_Status3_ISig_4 7 "MaintenanceStatus_NotAvailable" 6 "MaintenanceStatus_Error" 5 "MaintenanceStatus_Spare_01" 4 "MaintenanceStatus_InProgress" 3 "MaintenanceStatus_Spare" 2 "MaintenanceStatus_Warning" 1 "MaintenanceStatus_PreWarning" 0 "MaintenanceStatus_OK" ;
VAL_ 2566560036 MaintInfoGrp_ResetAuthorized26_I 3 "NoYes_NotAvailable" 2 "NoYes_Error" 1 "NoYes_Yes" 0 "NoYes_No" ;
VAL_ 2566560036 MaintInfoGrp_Supported12_ISig_4 3 "NoYes_NotAvailable" 2 "NoYes_Error" 1 "NoYes_Yes" 0 "NoYes_No" ;
VAL_ 2566560036 MaintInfoGrp_Status29_ISig_4 7 "MaintenanceStatus_NotAvailable" 6 "MaintenanceStatus_Error" 5 "MaintenanceStatus_Spare_01" 4 "MaintenanceStatus_InProgress" 3 "MaintenanceStatus_Spare" 2 "MaintenanceStatus_Warning" 1 "MaintenanceStatus_PreWarning" 0 "MaintenanceStatus_OK" ;
VAL_ 2566560036 MaintInfoGrp_ResetAuthorized37_I 3 "NoYes_NotAvailable" 2 "NoYes_Error" 1 "NoYes_Yes" 0 "NoYes_No" ;
VAL_ 2566560036 MaintInfoGrp_Status36_ISig_4 7 "MaintenanceStatus_NotAvailable" 6 "MaintenanceStatus_Error" 5 "MaintenanceStatus_Spare_01" 4 "MaintenanceStatus_InProgress" 3 "MaintenanceStatus_Spare" 2 "MaintenanceStatus_Warning" 1 "MaintenanceStatus_PreWarning" 0 "MaintenanceStatus_OK" ;
VAL_ 2566560036 MaintInfoGrp_Supported22_ISig_4 3 "NoYes_NotAvailable" 2 "NoYes_Error" 1 "NoYes_Yes" 0 "NoYes_No" ;
VAL_ 2566560036 MaintInfoGrp_Status35_ISig_4 7 "MaintenanceStatus_NotAvailable" 6 "MaintenanceStatus_Error" 5 "MaintenanceStatus_Spare_01" 4 "MaintenanceStatus_InProgress" 3 "MaintenanceStatus_Spare" 2 "MaintenanceStatus_Warning" 1 "MaintenanceStatus_PreWarning" 0 "MaintenanceStatus_OK" ;
VAL_ 2566560036 MaintInfoGrp_MaintOption26_ISig_ 15 "MaintOption_NotAvailable" 14 "MaintOption_Error" 13 "MaintOption_13" 12 "MaintOption_12" 11 "MaintOption_11" 10 "MaintOption_10" 9 "MaintOption_9" 8 "MaintOption_8" 7 "MaintOption_7" 6 "MaintOption_6" 5 "MaintOption_5" 4 "MaintOption_4" 3 "MaintOption_3" 2 "MaintOption_2" 1 "MaintOption_1" 0 "MaintOption_0" ;
VAL_ 2566560036 MaintInfoGrp_Status23_ISig_4 7 "MaintenanceStatus_NotAvailable" 6 "MaintenanceStatus_Error" 5 "MaintenanceStatus_Spare_01" 4 "MaintenanceStatus_InProgress" 3 "MaintenanceStatus_Spare" 2 "MaintenanceStatus_Warning" 1 "MaintenanceStatus_PreWarning" 0 "MaintenanceStatus_OK" ;
VAL_ 2566560036 MaintInfoGrp_Unit35_ISig_4 7 "MaintenanceUnit_NotAvailable" 6 "MaintenanceUnit_Error" 5 "MaintenanceUnit_None" 4 "MaintenanceUnit_AxleNumber" 3 "MaintenanceUnit_Percentage" 2 "MaintenanceUnit_Date" 1 "MaintenanceUnit_Distance" 0 "MaintenanceUnit_EngineTime" ;
VAL_ 2566560036 MaintInfoGrp_Supported6_ISig_4 3 "NoYes_NotAvailable" 2 "NoYes_Error" 1 "NoYes_Yes" 0 "NoYes_No" ;
VAL_ 2566560036 MaintInfoGrp_Unit27_ISig_4 7 "MaintenanceUnit_NotAvailable" 6 "MaintenanceUnit_Error" 5 "MaintenanceUnit_None" 4 "MaintenanceUnit_AxleNumber" 3 "MaintenanceUnit_Percentage" 2 "MaintenanceUnit_Date" 1 "MaintenanceUnit_Distance" 0 "MaintenanceUnit_EngineTime" ;
VAL_ 2566560036 MaintInfoGrp_MaintOption19_ISig_ 15 "MaintOption_NotAvailable" 14 "MaintOption_Error" 13 "MaintOption_13" 12 "MaintOption_12" 11 "MaintOption_11" 10 "MaintOption_10" 9 "MaintOption_9" 8 "MaintOption_8" 7 "MaintOption_7" 6 "MaintOption_6" 5 "MaintOption_5" 4 "MaintOption_4" 3 "MaintOption_3" 2 "MaintOption_2" 1 "MaintOption_1" 0 "MaintOption_0" ;
VAL_ 2566560036 MaintInfoGrp_ResetAuthorized14_I 3 "NoYes_NotAvailable" 2 "NoYes_Error" 1 "NoYes_Yes" 0 "NoYes_No" ;
VAL_ 2566560036 MaintInfoGrp_Status34_ISig_4 7 "MaintenanceStatus_NotAvailable" 6 "MaintenanceStatus_Error" 5 "MaintenanceStatus_Spare_01" 4 "MaintenanceStatus_InProgress" 3 "MaintenanceStatus_Spare" 2 "MaintenanceStatus_Warning" 1 "MaintenanceStatus_PreWarning" 0 "MaintenanceStatus_OK" ;
VAL_ 2566560036 MaintInfoGrp_Supported37_ISig_4 3 "NoYes_NotAvailable" 2 "NoYes_Error" 1 "NoYes_Yes" 0 "NoYes_No" ;
VAL_ 2566560036 MaintInfoGrp_MaintOption3_ISig_4 15 "MaintOption_NotAvailable" 14 "MaintOption_Error" 13 "MaintOption_13" 12 "MaintOption_12" 11 "MaintOption_11" 10 "MaintOption_10" 9 "MaintOption_9" 8 "MaintOption_8" 7 "MaintOption_7" 6 "MaintOption_6" 5 "MaintOption_5" 4 "MaintOption_4" 3 "MaintOption_3" 2 "MaintOption_2" 1 "MaintOption_1" 0 "MaintOption_0" ;
VAL_ 2566560036 MaintInfoGrp_Status1_ISig_4 7 "MaintenanceStatus_NotAvailable" 6 "MaintenanceStatus_Error" 5 "MaintenanceStatus_Spare_01" 4 "MaintenanceStatus_InProgress" 3 "MaintenanceStatus_Spare" 2 "MaintenanceStatus_Warning" 1 "MaintenanceStatus_PreWarning" 0 "MaintenanceStatus_OK" ;
VAL_ 2566560036 MaintInfoGrp_Status25_ISig_4 7 "MaintenanceStatus_NotAvailable" 6 "MaintenanceStatus_Error" 5 "MaintenanceStatus_Spare_01" 4 "MaintenanceStatus_InProgress" 3 "MaintenanceStatus_Spare" 2 "MaintenanceStatus_Warning" 1 "MaintenanceStatus_PreWarning" 0 "MaintenanceStatus_OK" ;
VAL_ 2566560036 MaintInfoGrp_ResetAuthorized1_IS 3 "NoYes_NotAvailable" 2 "NoYes_Error" 1 "NoYes_Yes" 0 "NoYes_No" ;
VAL_ 2566560036 MaintInfoGrp_ResetAuthorized27_I 3 "NoYes_NotAvailable" 2 "NoYes_Error" 1 "NoYes_Yes" 0 "NoYes_No" ;
VAL_ 2566560036 MaintInfoGrp_ResetAuthorized36_I 3 "NoYes_NotAvailable" 2 "NoYes_Error" 1 "NoYes_Yes" 0 "NoYes_No" ;
VAL_ 2566560036 MaintInfoGrp_Status28_ISig_4 7 "MaintenanceStatus_NotAvailable" 6 "MaintenanceStatus_Error" 5 "MaintenanceStatus_Spare_01" 4 "MaintenanceStatus_InProgress" 3 "MaintenanceStatus_Spare" 2 "MaintenanceStatus_Warning" 1 "MaintenanceStatus_PreWarning" 0 "MaintenanceStatus_OK" ;
VAL_ 2566560036 MaintInfoGrp_Status24_ISig_4 7 "MaintenanceStatus_NotAvailable" 6 "MaintenanceStatus_Error" 5 "MaintenanceStatus_Spare_01" 4 "MaintenanceStatus_InProgress" 3 "MaintenanceStatus_Spare" 2 "MaintenanceStatus_Warning" 1 "MaintenanceStatus_PreWarning" 0 "MaintenanceStatus_OK" ;
VAL_ 2566560036 MaintInfoGrp_MaintOption31_ISig_ 15 "MaintOption_NotAvailable" 14 "MaintOption_Error" 13 "MaintOption_13" 12 "MaintOption_12" 11 "MaintOption_11" 10 "MaintOption_10" 9 "MaintOption_9" 8 "MaintOption_8" 7 "MaintOption_7" 6 "MaintOption_6" 5 "MaintOption_5" 4 "MaintOption_4" 3 "MaintOption_3" 2 "MaintOption_2" 1 "MaintOption_1" 0 "MaintOption_0" ;
VAL_ 2566560036 MaintInfoGrp_Supported20_ISig_4 3 "NoYes_NotAvailable" 2 "NoYes_Error" 1 "NoYes_Yes" 0 "NoYes_No" ;
VAL_ 2566560036 MaintInfoGrp_Unit38_ISig_4 7 "MaintenanceUnit_NotAvailable" 6 "MaintenanceUnit_Error" 5 "MaintenanceUnit_None" 4 "MaintenanceUnit_AxleNumber" 3 "MaintenanceUnit_Percentage" 2 "MaintenanceUnit_Date" 1 "MaintenanceUnit_Distance" 0 "MaintenanceUnit_EngineTime" ;
VAL_ 2566560036 MaintInfoGrp_Unit24_ISig_4 7 "MaintenanceUnit_NotAvailable" 6 "MaintenanceUnit_Error" 5 "MaintenanceUnit_None" 4 "MaintenanceUnit_AxleNumber" 3 "MaintenanceUnit_Percentage" 2 "MaintenanceUnit_Date" 1 "MaintenanceUnit_Distance" 0 "MaintenanceUnit_EngineTime" ;
VAL_ 2566560036 MaintInfoGrp_Status37_ISig_4 7 "MaintenanceStatus_NotAvailable" 6 "MaintenanceStatus_Error" 5 "MaintenanceStatus_Spare_01" 4 "MaintenanceStatus_InProgress" 3 "MaintenanceStatus_Spare" 2 "MaintenanceStatus_Warning" 1 "MaintenanceStatus_PreWarning" 0 "MaintenanceStatus_OK" ;
VAL_ 2566560036 MaintInfoGrp_Supported39_ISig_4 3 "NoYes_NotAvailable" 2 "NoYes_Error" 1 "NoYes_Yes" 0 "NoYes_No" ;
VAL_ 2566560036 MaintInfoGrp_MaintOption39_ISig_ 15 "MaintOption_NotAvailable" 14 "MaintOption_Error" 13 "MaintOption_13" 12 "MaintOption_12" 11 "MaintOption_11" 10 "MaintOption_10" 9 "MaintOption_9" 8 "MaintOption_8" 7 "MaintOption_7" 6 "MaintOption_6" 5 "MaintOption_5" 4 "MaintOption_4" 3 "MaintOption_3" 2 "MaintOption_2" 1 "MaintOption_1" 0 "MaintOption_0" ;
VAL_ 2566560036 MaintInfoGrp_Supported4_ISig_4 3 "NoYes_NotAvailable" 2 "NoYes_Error" 1 "NoYes_Yes" 0 "NoYes_No" ;
VAL_ 2566560036 MaintInfoGrp_Supported3_ISig_4 3 "NoYes_NotAvailable" 2 "NoYes_Error" 1 "NoYes_Yes" 0 "NoYes_No" ;
VAL_ 2566560036 MaintInfoGrp_Unit39_ISig_4 7 "MaintenanceUnit_NotAvailable" 6 "MaintenanceUnit_Error" 5 "MaintenanceUnit_None" 4 "MaintenanceUnit_AxleNumber" 3 "MaintenanceUnit_Percentage" 2 "MaintenanceUnit_Date" 1 "MaintenanceUnit_Distance" 0 "MaintenanceUnit_EngineTime" ;
VAL_ 2566560036 MaintInfoGrp_Status5_ISig_4 7 "MaintenanceStatus_NotAvailable" 6 "MaintenanceStatus_Error" 5 "MaintenanceStatus_Spare_01" 4 "MaintenanceStatus_InProgress" 3 "MaintenanceStatus_Spare" 2 "MaintenanceStatus_Warning" 1 "MaintenanceStatus_PreWarning" 0 "MaintenanceStatus_OK" ;
VAL_ 2566560036 MaintInfoGrp_MaintOption6_ISig_4 15 "MaintOption_NotAvailable" 14 "MaintOption_Error" 13 "MaintOption_13" 12 "MaintOption_12" 11 "MaintOption_11" 10 "MaintOption_10" 9 "MaintOption_9" 8 "MaintOption_8" 7 "MaintOption_7" 6 "MaintOption_6" 5 "MaintOption_5" 4 "MaintOption_4" 3 "MaintOption_3" 2 "MaintOption_2" 1 "MaintOption_1" 0 "MaintOption_0" ;
VAL_ 2566560036 MaintInfoGrp_Status11_ISig_4 7 "MaintenanceStatus_NotAvailable" 6 "MaintenanceStatus_Error" 5 "MaintenanceStatus_Spare_01" 4 "MaintenanceStatus_InProgress" 3 "MaintenanceStatus_Spare" 2 "MaintenanceStatus_Warning" 1 "MaintenanceStatus_PreWarning" 0 "MaintenanceStatus_OK" ;
VAL_ 2566560036 MaintInfoGrp_Status19_ISig_4 7 "MaintenanceStatus_NotAvailable" 6 "MaintenanceStatus_Error" 5 "MaintenanceStatus_Spare_01" 4 "MaintenanceStatus_InProgress" 3 "MaintenanceStatus_Spare" 2 "MaintenanceStatus_Warning" 1 "MaintenanceStatus_PreWarning" 0 "MaintenanceStatus_OK" ;
VAL_ 2566560036 MaintInfoGrp_Status9_ISig_4 7 "MaintenanceStatus_NotAvailable" 6 "MaintenanceStatus_Error" 5 "MaintenanceStatus_Spare_01" 4 "MaintenanceStatus_InProgress" 3 "MaintenanceStatus_Spare" 2 "MaintenanceStatus_Warning" 1 "MaintenanceStatus_PreWarning" 0 "MaintenanceStatus_OK" ;
VAL_ 2566560036 MaintInfoGrp_Supported11_ISig_4 3 "NoYes_NotAvailable" 2 "NoYes_Error" 1 "NoYes_Yes" 0 "NoYes_No" ;
VAL_ 2566560036 MaintInfoGrp_MaintOption36_ISig_ 15 "MaintOption_NotAvailable" 14 "MaintOption_Error" 13 "MaintOption_13" 12 "MaintOption_12" 11 "MaintOption_11" 10 "MaintOption_10" 9 "MaintOption_9" 8 "MaintOption_8" 7 "MaintOption_7" 6 "MaintOption_6" 5 "MaintOption_5" 4 "MaintOption_4" 3 "MaintOption_3" 2 "MaintOption_2" 1 "MaintOption_1" 0 "MaintOption_0" ;
VAL_ 2566560036 MaintInfoGrp_ResetAuthorized8_IS 3 "NoYes_NotAvailable" 2 "NoYes_Error" 1 "NoYes_Yes" 0 "NoYes_No" ;
VAL_ 2566560036 MaintInfoGrp_MaintOption21_ISig_ 15 "MaintOption_NotAvailable" 14 "MaintOption_Error" 13 "MaintOption_13" 12 "MaintOption_12" 11 "MaintOption_11" 10 "MaintOption_10" 9 "MaintOption_9" 8 "MaintOption_8" 7 "MaintOption_7" 6 "MaintOption_6" 5 "MaintOption_5" 4 "MaintOption_4" 3 "MaintOption_3" 2 "MaintOption_2" 1 "MaintOption_1" 0 "MaintOption_0" ;
VAL_ 2566560036 MaintInfoGrp_Unit23_ISig_4 7 "MaintenanceUnit_NotAvailable" 6 "MaintenanceUnit_Error" 5 "MaintenanceUnit_None" 4 "MaintenanceUnit_AxleNumber" 3 "MaintenanceUnit_Percentage" 2 "MaintenanceUnit_Date" 1 "MaintenanceUnit_Distance" 0 "MaintenanceUnit_EngineTime" ;
VAL_ 2566560036 MaintInfoGrp_MaintOption5_ISig_4 15 "MaintOption_NotAvailable" 14 "MaintOption_Error" 13 "MaintOption_13" 12 "MaintOption_12" 11 "MaintOption_11" 10 "MaintOption_10" 9 "MaintOption_9" 8 "MaintOption_8" 7 "MaintOption_7" 6 "MaintOption_6" 5 "MaintOption_5" 4 "MaintOption_4" 3 "MaintOption_3" 2 "MaintOption_2" 1 "MaintOption_1" 0 "MaintOption_0" ;
VAL_ 2566560036 MaintInfoGrp_MaintOption16_ISig_ 15 "MaintOption_NotAvailable" 14 "MaintOption_Error" 13 "MaintOption_13" 12 "MaintOption_12" 11 "MaintOption_11" 10 "MaintOption_10" 9 "MaintOption_9" 8 "MaintOption_8" 7 "MaintOption_7" 6 "MaintOption_6" 5 "MaintOption_5" 4 "MaintOption_4" 3 "MaintOption_3" 2 "MaintOption_2" 1 "MaintOption_1" 0 "MaintOption_0" ;
VAL_ 2566560036 MaintInfoGrp_Unit29_ISig_4 7 "MaintenanceUnit_NotAvailable" 6 "MaintenanceUnit_Error" 5 "MaintenanceUnit_None" 4 "MaintenanceUnit_AxleNumber" 3 "MaintenanceUnit_Percentage" 2 "MaintenanceUnit_Date" 1 "MaintenanceUnit_Distance" 0 "MaintenanceUnit_EngineTime" ;
VAL_ 2566560036 MaintInfoGrp_Status12_ISig_4 7 "MaintenanceStatus_NotAvailable" 6 "MaintenanceStatus_Error" 5 "MaintenanceStatus_Spare_01" 4 "MaintenanceStatus_InProgress" 3 "MaintenanceStatus_Spare" 2 "MaintenanceStatus_Warning" 1 "MaintenanceStatus_PreWarning" 0 "MaintenanceStatus_OK" ;
VAL_ 2566560036 MaintInfoGrp_Supported0_ISig_4 3 "NoYes_NotAvailable" 2 "NoYes_Error" 1 "NoYes_Yes" 0 "NoYes_No" ;
VAL_ 2566560036 MaintInfoGrp_Status8_ISig_4 7 "MaintenanceStatus_NotAvailable" 6 "MaintenanceStatus_Error" 5 "MaintenanceStatus_Spare_01" 4 "MaintenanceStatus_InProgress" 3 "MaintenanceStatus_Spare" 2 "MaintenanceStatus_Warning" 1 "MaintenanceStatus_PreWarning" 0 "MaintenanceStatus_OK" ;
VAL_ 2566560036 MaintInfoGrp_Unit0_ISig_4 7 "MaintenanceUnit_NotAvailable" 6 "MaintenanceUnit_Error" 5 "MaintenanceUnit_None" 4 "MaintenanceUnit_AxleNumber" 3 "MaintenanceUnit_Percentage" 2 "MaintenanceUnit_Date" 1 "MaintenanceUnit_Distance" 0 "MaintenanceUnit_EngineTime" ;
VAL_ 2566560036 MaintInfoGrp_Supported14_ISig_4 3 "NoYes_NotAvailable" 2 "NoYes_Error" 1 "NoYes_Yes" 0 "NoYes_No" ;
VAL_ 2566560036 MaintInfoGrp_Supported8_ISig_4 3 "NoYes_NotAvailable" 2 "NoYes_Error" 1 "NoYes_Yes" 0 "NoYes_No" ;
VAL_ 2565822244 MaintInfo_Status 7 "MaintenanceStatus_NotAvailable" 6 "MaintenanceStatus_Error" 5 "MaintenanceStatus_Spare_01" 4 "MaintenanceStatus_InProgress" 3 "MaintenanceStatus_Spare" 2 "MaintenanceStatus_Warning" 1 "MaintenanceStatus_PreWarning" 0 "MaintenanceStatus_OK" ;
VAL_ 2565822244 MaintInfo_Unit 7 "MaintenanceUnit_NotAvailable" 6 "MaintenanceUnit_Error" 5 "MaintenanceUnit_None" 4 "MaintenanceUnit_AxleNumber" 3 "MaintenanceUnit_Percentage" 2 "MaintenanceUnit_Date" 1 "MaintenanceUnit_Distance" 0 "MaintenanceUnit_EngineTime" ;
VAL_ 2565822244 MaintInfo_MaintID 63 "MaintID_NotAvailable" 62 "MaintID_Error" 39 "MaintID_Monitor39" 38 "MaintID_Monitor38" 37 "MaintID_Monitor37" 36 "MaintID_Monitor36" 35 "MaintID_Monitor35" 34 "MaintID_Monitor34" 33 "MaintID_Monitor33" 32 "MaintID_Monitor32" 31 "MaintID_Monitor31" 30 "MaintID_Monitor30" 29 "MaintID_Monitor29" 28 "MaintID_Monitor28" 27 "MaintID_Monitor27" 26 "MaintID_Monitor26" 25 "MaintID_Monitor25" 24 "MaintID_Monitor24" 23 "MaintID_Monitor23" 22 "MaintID_Monitor22" 21 "MaintID_Monitor21" 20 "MaintID_Monitor20" 19 "MaintID_Monitor19" 18 "MaintID_Monitor18" 17 "MaintID_Monitor17" 16 "MaintID_Monitor16" 15 "MaintID_Monitor15" 14 "MaintID_Monitor14" 13 "MaintID_Monitor13" 12 "MaintID_Monitor12" 11 "MaintID_Monitor11" 10 "MaintID_Monitor10" 9 "MaintID_Monitor9" 8 "MaintID_Monitor8" 7 "MaintID_Monitor7" 6 "MaintID_Monitor6" 5 "MaintID_Monitor5" 4 "MaintID_Monitor4" 3 "MaintID_Monitor3" 2 "MaintID_Monitor2" 1 "MaintID_Monitor1" 0 "MaintID_Monitor0" ;
VAL_ 2565822244 MaintInfo_Supported 3 "NoYes_NotAvailable" 2 "NoYes_Error" 1 "NoYes_Yes" 0 "NoYes_No" ;
VAL_ 2565822244 MaintInfo_ResetAuthorized 3 "NoYes_NotAvailable" 2 "NoYes_Error" 1 "NoYes_Yes" 0 "NoYes_No" ;
VAL_ 2565822244 MaintInfo_MaintOption 15 "MaintOption_NotAvailable" 14 "MaintOption_Error" 13 "MaintOption_13" 12 "MaintOption_12" 11 "MaintOption_11" 10 "MaintOption_10" 9 "MaintOption_9" 8 "MaintOption_8" 7 "MaintOption_7" 6 "MaintOption_6" 5 "MaintOption_5" 4 "MaintOption_4" 3 "MaintOption_3" 2 "MaintOption_2" 1 "MaintOption_1" 0 "MaintOption_0" ;
VAL_ 2548896548 TransferCasePTOEngaged_ISig_4 3 "NotEngagedEngaged_NotAvailable" 2 "NotEngagedEngaged_Error" 1 "NotEngagedEngaged_Engaged" 0 "NotEngagedEngaged_NotEngaged" ;
VAL_ 2548896548 TransferCaseNeutral_status 3 "TransferCaseNeutral_status_NotAvailable" 2 "TransferCaseNeutral_status_Error" 1 "TransferCaseNeutral_status_TransferCaseInNeutral" 0 "TransferCaseNeutral_status_TransferCaseInDrive" ;
VAL_ 2566891300 DrawerState 3 "DrawerState_NotAvailable" 2 "DrawerState_Error" 1 "DrawerState_Close" 0 "DrawerState_Open" ;
VAL_ 2566891300 EndofLifeDriver1Card 3 "Alert_NotAvailable" 2 "Alert_Error" 1 "Alert_Alert" 0 "Alert_NoAlert" ;
VAL_ 2566891300 Driver1CardUnload 3 "Alert_NotAvailable" 2 "Alert_Error" 1 "Alert_Alert" 0 "Alert_NoAlert" ;
VAL_ 2566401316 MIStatusExtVMCU 3 "MIStatusExt_NotAvailable" 2 "MIStatusExt_Error" 1 "MIStatusExt_Ready" 0 "MIStatusExt_NotReady5Flash" ;
VAL_ 2566401316 MIDistinctWarningExtVMCU 15 "MIDistinctWarningExt_NotAvailable" 14 "MIDistinctWarningExt_Error" 3 "MIDistinctWarningExt_ContinuousMISteady" 2 "MIDistinctWarningExt_ShortMI3Flash" 1 "MIDistinctWarningExt_OnDemandMI2Flash" 0 "MIDistinctWarningExt_Off1Flash" ;
SIG_GROUP_ 2566560036 MaintInfoGrp_sg_ISig_4 1 : MaintInfoGrp_MaintOption30_ISig_ MaintInfoGrp_Unit36_ISig_4 MaintInfoGrp_MaintOption33_ISig_ MaintInfoGrp_ResetAuthorized32_I MaintInfoGrp_Status10_ISig_4 MaintInfoGrp_Unit2_ISig_4 MaintInfoGrp_Unit14_ISig_4 MaintInfoGrp_ResetAuthorized28_I MaintInfoGrp_ResetAuthorized10_I MaintInfoGrp_Status31_ISig_4 MaintInfoGrp_Unit32_ISig_4 MaintInfoGrp_Status15_ISig_4 MaintInfoGrp_Supported19_ISig_4 MaintInfoGrp_Unit34_ISig_4 MaintInfoGrp_Data17_ISig_4 MaintInfoGrp_Unit26_ISig_4 MaintInfoGrp_Data24_ISig_4 MaintInfoGrp_ResetAuthorized24_I MaintInfoGrp_ResetAuthorized34_I MaintInfoGrp_Unit28_ISig_4 MaintInfoGrp_Status26_ISig_4 MaintInfoGrp_Unit10_ISig_4 MaintInfoGrp_Data12_ISig_4 MaintInfoGrp_ResetAuthorized38_I MaintInfoGrp_MaintOption14_ISig_ MaintInfoGrp_MaintOption17_ISig_ MaintInfoGrp_Status33_ISig_4 MaintInfoGrp_Unit6_ISig_4 MaintInfoGrp_Supported7_ISig_4 MaintInfoGrp_Status7_ISig_4 MaintInfoGrp_ResetAuthorized2_IS MaintInfoGrp_MaintOption27_ISig_ MaintInfoGrp_Supported36_ISig_4 MaintInfoGrp_Unit22_ISig_4 MaintInfoGrp_Unit18_ISig_4 MaintInfoGrp_MaintOption28_ISig_ MaintInfoGrp_Supported18_ISig_4 MaintInfoGrp_Status22_ISig_4 MaintInfoGrp_Status30_ISig_4 MaintInfoGrp_Status20_ISig_4 MaintInfoGrp_Status38_ISig_4 MaintInfoGrp_Data38_ISig_4 MaintInfoGrp_ResetAuthorized7_IS MaintInfoGrp_Data19_ISig_4 MaintInfoGrp_ResetAuthorized19_I MaintInfoGrp_ResetAuthorized12_I MaintInfoGrp_MaintOption8_ISig_4 MaintInfoGrp_MaintOption9_ISig_4 MaintInfoGrp_ResetAuthorized13_I MaintInfoGrp_Unit31_ISig_4 MaintInfoGrp_Status2_ISig_4 MaintInfoGrp_ResetAuthorized5_IS MaintInfoGrp_Supported33_ISig_4 MaintInfoGrp_Unit7_ISig_4 MaintInfoGrp_Supported34_ISig_4 MaintInfoGrp_Data16_ISig_4 MaintInfoGrp_Unit19_ISig_4 MaintInfoGrp_ResetAuthorized21_I MaintInfoGrp_ResetAuthorized31_I MaintInfoGrp_Data28_ISig_4 MaintInfoGrp_ResetAuthorized3_IS MaintInfoGrp_MaintOption34_ISig_ MaintInfoGrp_Status21_ISig_4 MaintInfoGrp_Unit21_ISig_4 MaintInfoGrp_MaintOption24_ISig_ MaintInfoGrp_Data26_ISig_4 MaintInfoGrp_Data37_ISig_4 MaintInfoGrp_Data35_ISig_4 MaintInfoGrp_Supported17_ISig_4 MaintInfoGrp_ResetAuthorized17_I MaintInfoGrp_Unit25_ISig_4 MaintInfoGrp_Unit37_ISig_4 MaintInfoGrp_MaintOption2_ISig_4 MaintInfoGrp_Supported21_ISig_4 MaintInfoGrp_ResetAuthorized16_I MaintInfoGrp_Supported15_ISig_4 MaintInfoGrp_ResetAuthorized9_IS MaintInfoGrp_MaintOption18_ISig_ MaintInfoGrp_Data14_ISig_4 MaintInfoGrp_Data8_ISig_4 MaintInfoGrp_Supported29_ISig_4 MaintInfoGrp_ResetAuthorized39_I MaintInfoGrp_Supported32_ISig_4 MaintInfoGrp_Data33_ISig_4 MaintInfoGrp_ResetAuthorized35_I MaintInfoGrp_Data30_ISig_4 MaintInfoGrp_ResetAuthorized29_I MaintInfoGrp_Supported35_ISig_4 MaintInfoGrp_ResetAuthorized4_IS MaintInfoGrp_Data10_ISig_4 MaintInfoGrp_Data9_ISig_4 MaintInfoGrp_Unit1_ISig_4 MaintInfoGrp_MaintOption7_ISig_4 MaintInfoGrp_Supported24_ISig_4 MaintInfoGrp_Supported25_ISig_4 MaintInfoGrp_Unit15_ISig_4 MaintInfoGrp_Supported1_ISig_4 MaintInfoGrp_ResetAuthorized11_I MaintInfoGrp_Supported13_ISig_4 MaintInfoGrp_Supported10_ISig_4 MaintInfoGrp_Data2_ISig_4 MaintInfoGrp_Unit16_ISig_4 MaintInfoGrp_MaintOption35_ISig_ MaintInfoGrp_MaintOption22_ISig_ MaintInfoGrp_MaintOption12_ISig_ MaintInfoGrp_Supported9_ISig_4 MaintInfoGrp_Supported31_ISig_4 MaintInfoGrp_MaintOption37_ISig_ MaintInfoGrp_MaintOption13_ISig_ MaintInfoGrp_ResetAuthorized22_I MaintInfoGrp_Status14_ISig_4 MaintInfoGrp_Status18_ISig_4 MaintInfoGrp_Unit17_ISig_4 MaintInfoGrp_Unit12_ISig_4 MaintInfoGrp_Data22_ISig_4 MaintInfoGrp_Supported27_ISig_4 MaintInfoGrp_Unit4_ISig_4 MaintInfoGrp_Data13_ISig_4 MaintInfoGrp_Status27_ISig_4 MaintInfoGrp_MaintOption29_ISig_ MaintInfoGrp_Unit9_ISig_4 MaintInfoGrp_Unit13_ISig_4 MaintInfoGrp_Data25_ISig_4 MaintInfoGrp_Unit3_ISig_4 MaintInfoGrp_MaintOption15_ISig_ MaintInfoGrp_ResetAuthorized15_I MaintInfoGrp_MaintOption11_ISig_ MaintInfoGrp_MaintOption25_ISig_ MaintInfoGrp_Supported16_ISig_4 MaintInfoGrp_Supported23_ISig_4 MaintInfoGrp_Status13_ISig_4 MaintInfoGrp_Status17_ISig_4 MaintInfoGrp_Unit8_ISig_4 MaintInfoGrp_MaintOption38_ISig_ MaintInfoGrp_Data4_ISig_4 MaintInfoGrp_Supported2_ISig_4 MaintInfoGrp_ResetAuthorized0_IS MaintInfoGrp_Supported5_ISig_4 MaintInfoGrp_Status6_ISig_4 MaintInfoGrp_Unit5_ISig_4 MaintInfoGrp_Data0_ISig_4 MaintInfoGrp_Data29_ISig_4 MaintInfoGrp_Supported28_ISig_4 MaintInfoGrp_Status32_ISig_4 MaintInfoGrp_MaintOption0_ISig_4 MaintInfoGrp_ResetAuthorized25_I MaintInfoGrp_MaintOption32_ISig_ MaintInfoGrp_Unit11_ISig_4 MaintInfoGrp_Data39_ISig_4 MaintInfoGrp_MaintOption4_ISig_4 MaintInfoGrp_Supported38_ISig_4 MaintInfoGrp_MaintOption1_ISig_4 MaintInfoGrp_Supported30_ISig_4 MaintInfoGrp_ResetAuthorized33_I MaintInfoGrp_Status0_ISig_4 MaintInfoGrp_ResetAuthorized20_I MaintInfoGrp_Unit33_ISig_4 MaintInfoGrp_Supported26_ISig_4 MaintInfoGrp_ResetAuthorized6_IS MaintInfoGrp_Data18_ISig_4 MaintInfoGrp_Status16_ISig_4 MaintInfoGrp_ResetAuthorized18_I MaintInfoGrp_Status4_ISig_4 MaintInfoGrp_Data3_ISig_4 MaintInfoGrp_MaintOption20_ISig_ MaintInfoGrp_ResetAuthorized30_I MaintInfoGrp_ResetAuthorized23_I MaintInfoGrp_Unit30_ISig_4 MaintInfoGrp_Data20_ISig_4 MaintInfoGrp_MaintOption23_ISig_ MaintInfoGrp_Data23_ISig_4 MaintInfoGrp_Unit20_ISig_4 MaintInfoGrp_MaintOption10_ISig_ MaintInfoGrp_Status39_ISig_4 MaintInfoGrp_Data21_ISig_4 MaintInfoGrp_Status3_ISig_4 MaintInfoGrp_Data5_ISig_4 MaintInfoGrp_ResetAuthorized26_I MaintInfoGrp_Supported12_ISig_4 MaintInfoGrp_Data32_ISig_4 MaintInfoGrp_Status29_ISig_4 MaintInfoGrp_ResetAuthorized37_I MaintInfoGrp_Status36_ISig_4 MaintInfoGrp_Supported22_ISig_4 MaintInfoGrp_Status35_ISig_4 MaintInfoGrp_Data7_ISig_4 MaintInfoGrp_MaintOption26_ISig_ MaintInfoGrp_Status23_ISig_4 MaintInfoGrp_Unit35_ISig_4 MaintInfoGrp_Supported6_ISig_4 MaintInfoGrp_Data34_ISig_4 MaintInfoGrp_Unit27_ISig_4 MaintInfoGrp_MaintOption19_ISig_ MaintInfoGrp_ResetAuthorized14_I MaintInfoGrp_Status34_ISig_4 MaintInfoGrp_Supported37_ISig_4 MaintInfoGrp_MaintOption3_ISig_4 MaintInfoGrp_Status1_ISig_4 MaintInfoGrp_Data1_ISig_4 MaintInfoGrp_Status25_ISig_4 MaintInfoGrp_ResetAuthorized1_IS MaintInfoGrp_ResetAuthorized27_I MaintInfoGrp_ResetAuthorized36_I MaintInfoGrp_Status28_ISig_4 MaintInfoGrp_Status24_ISig_4 MaintInfoGrp_MaintOption31_ISig_ MaintInfoGrp_Supported20_ISig_4 MaintInfoGrp_Unit38_ISig_4 MaintInfoGrp_Unit24_ISig_4 MaintInfoGrp_Data15_ISig_4 MaintInfoGrp_Status37_ISig_4 MaintInfoGrp_Supported39_ISig_4 MaintInfoGrp_MaintOption39_ISig_ MaintInfoGrp_Supported4_ISig_4 MaintInfoGrp_Supported3_ISig_4 MaintInfoGrp_Data6_ISig_4 MaintInfoGrp_Unit39_ISig_4 MaintInfoGrp_Status5_ISig_4 MaintInfoGrp_Data36_ISig_4 MaintInfoGrp_MaintOption6_ISig_4 MaintInfoGrp_Status11_ISig_4 MaintInfoGrp_Status19_ISig_4 MaintInfoGrp_Status9_ISig_4 MaintInfoGrp_Supported11_ISig_4 MaintInfoGrp_Data27_ISig_4 MaintInfoGrp_Data31_ISig_4 MaintInfoGrp_MaintOption36_ISig_ MaintInfoGrp_ResetAuthorized8_IS MaintInfoGrp_MaintOption21_ISig_ MaintInfoGrp_Unit23_ISig_4 MaintInfoGrp_MaintOption5_ISig_4 MaintInfoGrp_MaintOption16_ISig_ MaintInfoGrp_Unit29_ISig_4 MaintInfoGrp_Status12_ISig_4 MaintInfoGrp_Supported0_ISig_4 MaintInfoGrp_Status8_ISig_4 MaintInfoGrp_Data11_ISig_4 MaintInfoGrp_Unit0_ISig_4 MaintInfoGrp_Supported14_ISig_4 MaintInfoGrp_Supported8_ISig_4;
SIG_GROUP_ 2565822244 MaintInfo_sg 1 : MaintInfo_Status MaintInfo_Unit MaintInfo_MaintID MaintInfo_Supported MaintInfo_ResetAuthorized MaintInfo_MaintOption MaintInfo_Data;
